VERSION "BASE;119 -- 04.07.2025 -- R3233 -- FDMgenDBC1.0"

NS_ :

BS_:

BU_: CM4

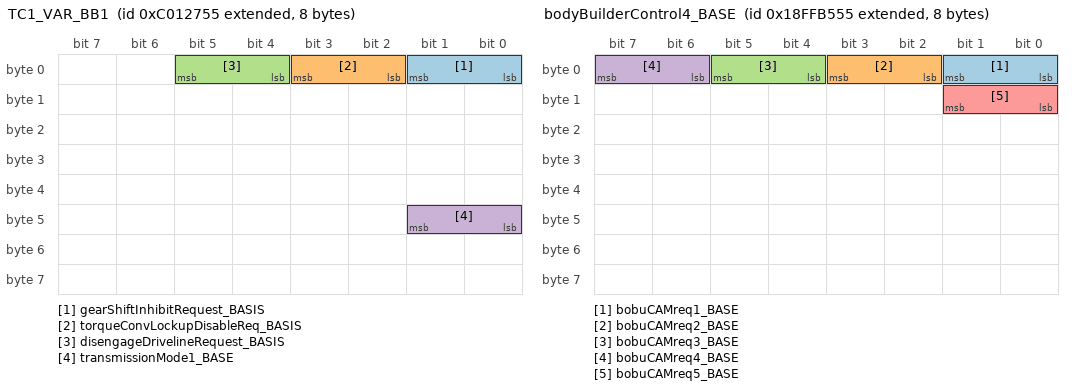
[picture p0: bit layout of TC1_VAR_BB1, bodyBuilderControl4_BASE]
BO_ 2348885845 TC1_VAR_BB1: 8 CM4
 SG_ gearShiftInhibitRequest_BASIS : 0|2@1+ (1,0) [0|0] "-" Vector__XXX
 SG_ torqueConvLockupDisableReq_BASIS : 2|2@1+ (1,0) [0|0] "-" Vector__XXX
 SG_ disengageDrivelineRequest_BASIS : 4|2@1+ (1,0) [0|0] "-" Vector__XXX
 SG_ transmissionMode1_BASE : 40|2@1+ (1,0) [0|0] "-" Vector__XXX

BO_ 2349075285 XBR_VAR7: 8 CM4
 SG_ externalAccelerationDemand_BASIS : 0|16@1+ (0.00048828125,-15.687) [-15.687|15.687] "m/s²" Vector__XXX
 SG_ XBRcontrolMode_BASIS : 20|2@1+ (1,0) [0|0] "-" Vector__XXX
 SG_ XBRmessageCounter_BASIS : 56|4@1+ (1,0) [0|15] "count" Vector__XXX
 SG_ XBRmessageChecksum_BASIS : 60|4@1+ (1,0) [0|15] "count" Vector__XXX

BO_ 2566894933 bodyBuilderControl4_BASE: 8 CM4
 SG_ bobuCAMreq1_BASE : 0|2@1+ (1,0) [0|0] "-" Vector__XXX
 SG_ bobuCAMreq2_BASE : 2|2@1+ (1,0) [0|0] "-" Vector__XXX
 SG_ bobuCAMreq3_BASE : 4|2@1+ (1,0) [0|0] "-" Vector__XXX
 SG_ bobuCAMreq4_BASE : 6|2@1+ (1,0) [0|0] "-" Vector__XXX
 SG_ bobuCAMreq5_BASE : 8|2@1+ (1,0) [0|0] "-" Vector__XXX

BO_ 2566656597 CDC1_BASE: 8 CM4
 SG_ leftFrontWindowPositionCommand_B : 16|3@1+ (1,0) [0|0] "-" Vector__XXX
 SG_ righFrontWindowPositionCommand_B : 19|3@1+ (1,0) [0|0] "-" Vector__XXX
 SG_ remoteCabDoorLockRequest_BASE : 8|3@1+ (1,0) [0|0] "-" Vector__XXX

BO_ 2564816981 cabMessage1_VAR4: 8 CM4
 SG_ DPFregenerationInhibitSw_BASE : 40|2@1+ (1,0) [0|0] "-" Vector__XXX

BO_ 2364538256 KSM1_A_VAR_BB2: 8 CM4
 SG_ requestedRoadSpeedLimit_BASIS : 32|8@1+ (1,0) [0|250] "km/h" Vector__XXX
 SG_ CCswitchStatus_KSM : 40|8@1+ (1,0) [0|0] "-" Vector__XXX
 SG_ motorStart_KSM : 48|2@1+ (1,0) [0|0] "-" Vector__XXX
 SG_ motorStop_KSM : 50|2@1+ (1,0) [0|0] "-" Vector__XXX

BO_ 2348885904 TC1_VAR_BB2: 8 CM4
 SG_ gearShiftInhibitRequest_BASIS : 0|2@1+ (1,0) [0|0] "-" Vector__XXX
 SG_ torqueConvLockupDisableReq_BASIS : 2|2@1+ (1,0) [0|0] "-" Vector__XXX
 SG_ disengageDrivelineRequest_BASIS : 4|2@1+ (1,0) [0|0] "-" Vector__XXX
 SG_ transmissionMode1_BASE : 40|2@1+ (1,0) [0|0] "-" Vector__XXX

BO_ 2349075344 XBR_VAR_BB2: 8 CM4
 SG_ externalAccelerationDemand_BASIS : 0|16@1+ (0.00048828125,-15.687) [-15.687|15.687] "m/s²" Vector__XXX
 SG_ XBRcontrolMode_BASIS : 20|2@1+ (1,0) [0|0] "-" Vector__XXX
 SG_ XBRmessageCounter_BASIS : 56|4@1+ (1,0) [0|15] "count" Vector__XXX
 SG_ XBRmessageChecksum_BASIS : 60|4@1+ (1,0) [0|15] "count" Vector__XXX

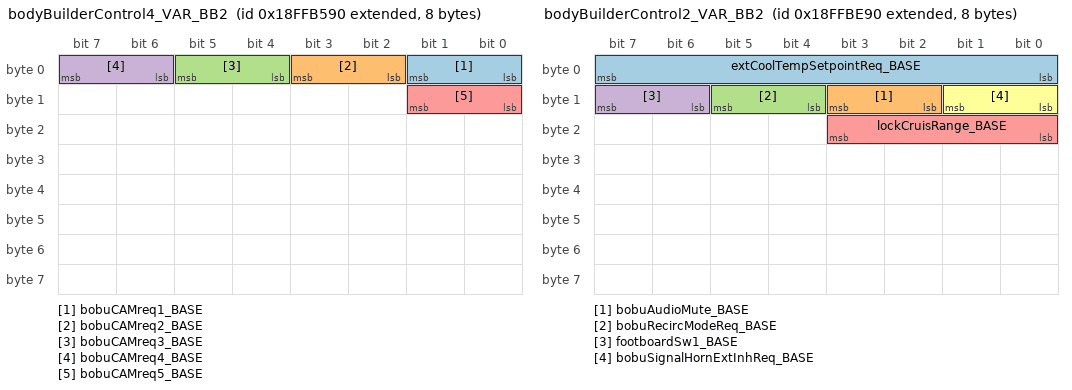
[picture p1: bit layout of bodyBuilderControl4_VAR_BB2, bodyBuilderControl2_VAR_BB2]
BO_ 2566894992 bodyBuilderControl4_VAR_BB2: 8 CM4
 SG_ bobuCAMreq1_BASE : 0|2@1+ (1,0) [0|0] "-" Vector__XXX
 SG_ bobuCAMreq2_BASE : 2|2@1+ (1,0) [0|0] "-" Vector__XXX
 SG_ bobuCAMreq3_BASE : 4|2@1+ (1,0) [0|0] "-" Vector__XXX
 SG_ bobuCAMreq4_BASE : 6|2@1+ (1,0) [0|0] "-" Vector__XXX
 SG_ bobuCAMreq5_BASE : 8|2@1+ (1,0) [0|0] "-" Vector__XXX

BO_ 2566897296 bodyBuilderControl2_VAR_BB2: 8 CM4
 SG_ extCoolTempSetpointReq_BASE : 0|8@1+ (1,-40) [-40|210] "°C" Vector__XXX
 SG_ bobuAudioMute_BASE : 10|2@1+ (1,0) [0|0] "-" Vector__XXX
 SG_ bobuRecircModeReq_BASE : 12|2@1+ (1,0) [0|0] "-" Vector__XXX
 SG_ footboardSw1_BASE : 14|2@1+ (1,0) [0|0] "-" Vector__XXX
 SG_ lockCruisRange_BASE : 16|4@1+ (1,0) [0|0] "-" Vector__XXX
 SG_ bobuSignalHornExtInhReq_BASE : 8|2@1+ (1,0) [0|0] "-" Vector__XXX

BO_ 2564817040 cabMessage1_VAR_BB2: 8 CM4
 SG_ DPFregenerationInhibitSw_BASE : 40|2@1+ (1,0) [0|0] "-" Vector__XXX

BO_ 2566656656 CDC1_VAR_BB2: 8 CM4
 SG_ leftFrontWindowPositionCommand_B : 16|3@1+ (1,0) [0|0] "-" Vector__XXX
 SG_ righFrontWindowPositionCommand_B : 19|3@1+ (1,0) [0|0] "-" Vector__XXX
 SG_ remoteCabDoorLockRequest_BASE : 8|3@1+ (1,0) [0|0] "-" Vector__XXX

BO_ 2365443216 operatorsExtLightControlsMessage: 8 CM4
 SG_ hazardLightSwitch_BASE : 40|2@1+ (1,0) [0|0] "-" Vector__XXX

BO_ 2564817041 cabMessage1_VAR_BB3: 8 CM4
 SG_ DPFregenerationInhibitSw_BASE : 40|2@1+ (1,0) [0|0] "-" Vector__XXX

BO_ 2566656657 CDC1_VAR_BB3: 8 CM4
 SG_ leftFrontWindowPositionCommand_B : 16|3@1+ (1,0) [0|0] "-" Vector__XXX
 SG_ righFrontWindowPositionCommand_B : 19|3@1+ (1,0) [0|0] "-" Vector__XXX
 SG_ remoteCabDoorLockRequest_BASE : 8|3@1+ (1,0) [0|0] "-" Vector__XXX

BO_ 2364538257 KSM1_A_VAR_BB3: 8 CM4
 SG_ requestedRoadSpeedLimit_BASIS : 32|8@1+ (1,0) [0|250] "km/h" Vector__XXX
 SG_ CCswitchStatus_KSM : 40|8@1+ (1,0) [0|0] "-" Vector__XXX
 SG_ motorStart_KSM : 48|2@1+ (1,0) [0|0] "-" Vector__XXX
 SG_ motorStop_KSM : 50|2@1+ (1,0) [0|0] "-" Vector__XXX

BO_ 2365443217 operatorsExtLightControlsMessage: 8 CM4
 SG_ hazardLightSwitch_BASE : 12|2@1+ (1,0) [0|0] "-" Vector__XXX

BO_ 2348885905 TC1_VAR_BB3: 8 CM4
 SG_ gearShiftInhibitRequest_BASIS : 0|2@1+ (1,0) [0|0] "-" Vector__XXX
 SG_ torqueConvLockupDisableReq_BASIS : 2|2@1+ (1,0) [0|0] "-" Vector__XXX
 SG_ disengageDrivelineRequest_BASIS : 4|2@1+ (1,0) [0|0] "-" Vector__XXX
 SG_ transmissionMode1_BASE : 40|2@1+ (1,0) [0|0] "-" Vector__XXX

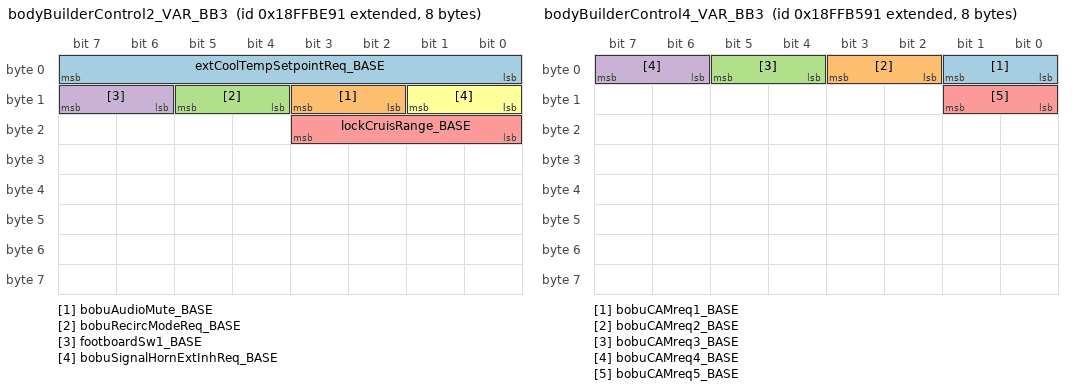
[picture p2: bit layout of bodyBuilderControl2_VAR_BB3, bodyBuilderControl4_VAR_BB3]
BO_ 2566897297 bodyBuilderControl2_VAR_BB3: 8 CM4
 SG_ extCoolTempSetpointReq_BASE : 0|8@1+ (1,-40) [-40|210] "°C" Vector__XXX
 SG_ bobuAudioMute_BASE : 10|2@1+ (1,0) [0|0] "-" Vector__XXX
 SG_ bobuRecircModeReq_BASE : 12|2@1+ (1,0) [0|0] "-" Vector__XXX
 SG_ footboardSw1_BASE : 14|2@1+ (1,0) [0|0] "-" Vector__XXX
 SG_ lockCruisRange_BASE : 16|4@1+ (1,0) [0|0] "-" Vector__XXX
 SG_ bobuSignalHornExtInhReq_BASE : 8|2@1+ (1,0) [0|0] "-" Vector__XXX

BO_ 2566894993 bodyBuilderControl4_VAR_BB3: 8 CM4
 SG_ bobuCAMreq1_BASE : 0|2@1+ (1,0) [0|0] "-" Vector__XXX
 SG_ bobuCAMreq2_BASE : 2|2@1+ (1,0) [0|0] "-" Vector__XXX
 SG_ bobuCAMreq3_BASE : 4|2@1+ (1,0) [0|0] "-" Vector__XXX
 SG_ bobuCAMreq4_BASE : 6|2@1+ (1,0) [0|0] "-" Vector__XXX
 SG_ bobuCAMreq5_BASE : 8|2@1+ (1,0) [0|0] "-" Vector__XXX

BO_ 2349075345 XBR_VAR_BB3: 8 CM4
 SG_ externalAccelerationDemand_BASIS : 0|16@1+ (0.00048828125,-15.687) [-15.687|15.687] "m/s²" Vector__XXX
 SG_ XBRcontrolMode_BASIS : 20|2@1+ (1,0) [0|0] "-" Vector__XXX
 SG_ XBRmessageCounter_BASIS : 56|4@1+ (1,0) [0|15] "count" Vector__XXX
 SG_ XBRmessageChecksum_BASIS : 60|4@1+ (1,0) [0|15] "count" Vector__XXX

BO_ 2565865813 EBC1_VAR3: 8 CM4
 SG_ haltBrakeSwitch_BASIS : 58|2@1+ (1,0) [0|0] "-" Vector__XXX

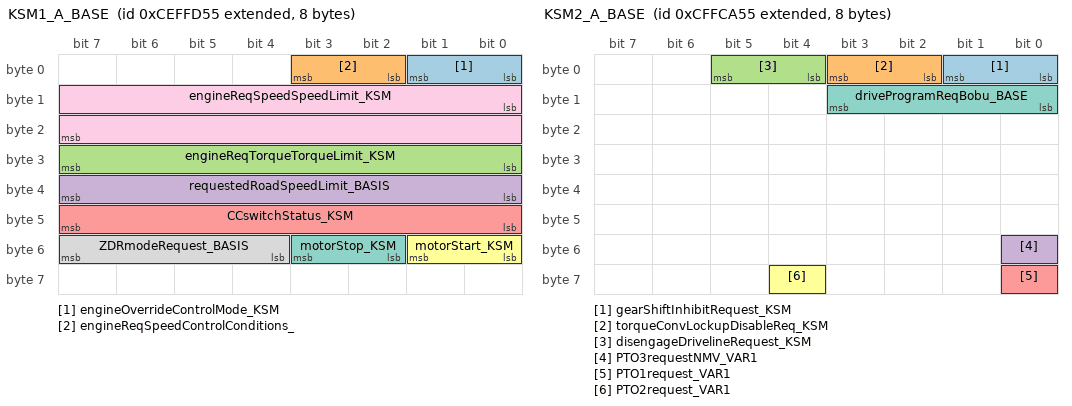
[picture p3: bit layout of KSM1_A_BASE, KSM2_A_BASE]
BO_ 2364538197 KSM1_A_BASE: 8 CM4
 SG_ engineOverrideControlMode_KSM : 0|2@1+ (1,0) [0|0] "-" Vector__XXX
 SG_ engineReqSpeedControlConditions_ : 2|2@1+ (1,0) [0|0] "-" Vector__XXX
 SG_ engineReqTorqueTorqueLimit_KSM : 24|8@1+ (1,-125) [-125|125] "%" Vector__XXX
 SG_ requestedRoadSpeedLimit_BASIS : 32|8@1+ (1,0) [0|250] "km/h" Vector__XXX
 SG_ CCswitchStatus_KSM : 40|8@1+ (1,0) [0|0] "-" Vector__XXX
 SG_ motorStart_KSM : 48|2@1+ (1,0) [0|0] "-" Vector__XXX
 SG_ motorStop_KSM : 50|2@1+ (1,0) [0|0] "-" Vector__XXX
 SG_ ZDRmodeRequest_BASIS : 52|4@1+ (1,0) [0|0] "-" Vector__XXX
 SG_ engineReqSpeedSpeedLimit_KSM : 8|16@1+ (0.125,0) [0|8031.875] "rpm" Vector__XXX

BO_ 2365573717 KSM2_A_BASE: 8 CM4
 SG_ gearShiftInhibitRequest_KSM : 0|2@1+ (1,0) [0|0] "-" Vector__XXX
 SG_ torqueConvLockupDisableReq_KSM : 2|2@1+ (1,0) [0|0] "-" Vector__XXX
 SG_ disengageDrivelineRequest_KSM : 4|2@1+ (1,0) [0|0] "-" Vector__XXX
 SG_ PTO3requestNMV_VAR1 : 48|1@1+ (1,0) [0|0] "-" Vector__XXX
 SG_ PTO1request_VAR1 : 56|1@1+ (1,0) [0|0] "-" Vector__XXX
 SG_ PTO2request_VAR1 : 60|1@1+ (1,0) [0|0] "-" Vector__XXX
 SG_ driveProgramReqBobu_BASE : 8|4@1+ (1,0) [0|0] "-" Vector__XXX

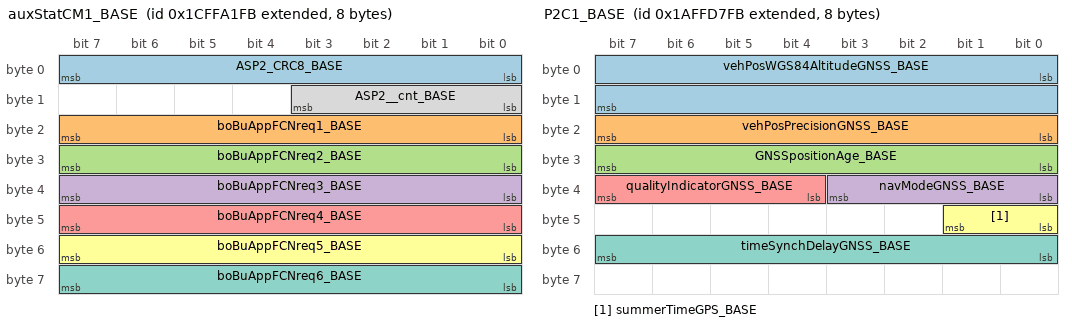
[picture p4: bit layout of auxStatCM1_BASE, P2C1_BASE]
BO_ 2633998843 auxStatCM1_BASE: 8 CM4
 SG_ ASP2_CRC8_BASE : 0|8@1+ (1,0) [0|255] "-" Vector__XXX
 SG_ boBuAppFCNreq1_BASE : 16|8@1+ (1,0) [0|250] "-" Vector__XXX
 SG_ boBuAppFCNreq2_BASE : 24|8@1+ (1,0) [0|250] "-" Vector__XXX
 SG_ boBuAppFCNreq3_BASE : 32|8@1+ (1,0) [0|250] "-" Vector__XXX
 SG_ boBuAppFCNreq4_BASE : 40|8@1+ (1,0) [0|250] "-" Vector__XXX
 SG_ boBuAppFCNreq5_BASE : 48|8@1+ (1,0) [0|250] "-" Vector__XXX
 SG_ boBuAppFCNreq6_BASE : 56|8@1+ (1,0) [0|250] "-" Vector__XXX
 SG_ ASP2__cnt_BASE : 8|4@1+ (1,0) [0|15] "-" Vector__XXX

BO_ 2600458491 P2C2_BASE: 8 CM4
 SG_ vehPosCWGS84LatitudeGNSS_BASE : 0|32@1+ (0.0000001,-210) [-210|210] "°" Vector__XXX
 SG_ vehPosCWGS84LongitudeGNSS_BASE : 32|32@1+ (0.0000001,-210) [-210|210] "°" Vector__XXX

BO_ 2600458235 P2C1_BASE: 8 CM4
 SG_ vehPosWGS84AltitudeGNSS_BASE : 0|16@1+ (1,-1000) [-1000|10000] "m" Vector__XXX
 SG_ vehPosPrecisionGNSS_BASE : 16|8@1+ (0.5,0) [0|120] "m" Vector__XXX
 SG_ GNSSpositionAge_BASE : 24|8@1+ (5,0) [0|1250] "ms" Vector__XXX
 SG_ navModeGNSS_BASE : 32|4@1+ (1,0) [0|0] "-" Vector__XXX
 SG_ qualityIndicatorGNSS_BASE : 36|4@1+ (1,0) [0|0] "-" Vector__XXX
 SG_ summerTimeGPS_BASE : 40|2@1+ (1,0) [0|0] "-" Vector__XXX
 SG_ timeSynchDelayGNSS_BASE : 48|8@1+ (5,0) [0|1250] "ms" Vector__XXX

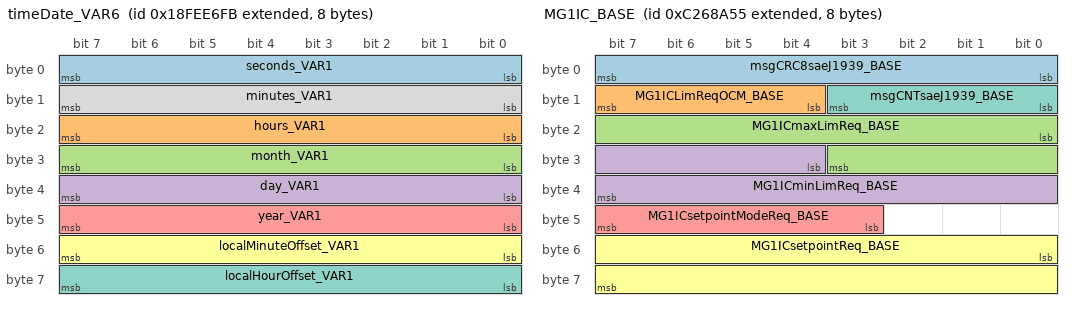
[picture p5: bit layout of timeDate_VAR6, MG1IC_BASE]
BO_ 2566842107 timeDate_VAR6: 8 CM4
 SG_ seconds_VAR1 : 0|8@1+ (0.25,0) [0|62.5] "s" Vector__XXX
 SG_ hours_VAR1 : 16|8@1+ (1,0) [0|250] "h" Vector__XXX
 SG_ month_VAR1 : 24|8@1+ (1,0) [0|250] "month" Vector__XXX
 SG_ day_VAR1 : 32|8@1+ (0.25,0) [0|62.5] "day" Vector__XXX
 SG_ year_VAR1 : 40|8@1+ (1,1985) [1985|2235] "year" Vector__XXX
 SG_ localMinuteOffset_VAR1 : 48|8@1+ (1,-125) [-125|125] "min" Vector__XXX
 SG_ localHourOffset_VAR1 : 56|8@1+ (1,-125) [-125|125] "h" Vector__XXX
 SG_ minutes_VAR1 : 8|8@1+ (1,0) [0|250] "min" Vector__XXX

BO_ 2566649595 VP2_BASE: 8 CM4
 SG_ numberSatellitesGNSS_BASE : 0|8@1+ (1,0) [0|250] "-" Vector__XXX
 SG_ vdopGNSS_BASE : 16|8@1+ (0.1,0) [0|25] "-" Vector__XXX
 SG_ pdopGNSS_BASE : 24|8@1+ (0.1,0) [0|25] "-" Vector__XXX
 SG_ tdopGNSS_BASE : 32|8@1+ (0.1,0) [0|25] "-" Vector__XXX
 SG_ hdopGNSS_BASE : 8|8@1+ (0.1,0) [0|25] "-" Vector__XXX

BO_ 2566842619 VDS_BASE: 8 CM4
 SG_ compBearingGNSS_BASE : 0|16@1+ (0.0078125,0) [0|501.99] "°" Vector__XXX
 SG_ vehSpdGNSS_BASE : 16|16@1+ (0.00390625,0) [0|250.996] "km/h" Vector__XXX
 SG_ pitchGNSS_BASE : 32|16@1+ (0.0078125,-200) [-200|301.99] "°" Vector__XXX
 SG_ altitudeGNSS_BASE : 48|16@1+ (0.125,-2500) [-2500|5531.875] "m" Vector__XXX

BO_ 2566845435 VP1_BASE: 8 CM4
 SG_ vehPosWGS84LatitudeGNSS_BASE : 0|32@1+ (0.0000001,-210) [-210|210] "°" Vector__XXX
 SG_ vehPosWGS84LongitudeGNSS_BASE : 32|32@1+ (0.0000001,-210) [-210|210] "°" Vector__XXX

BO_ 2583638267 appControlInterface_VAR2: 8 CM4
 SG_ appFrameworkCtrlAppID_BASE : 24|16@1+ (1,0) [0|64255] "-" Vector__XXX
 SG_ appFrameworkAppCommand_BASE : 40|16@1+ (1,0) [0|0] "-" Vector__XXX

BO_ 2564484859 UDSreq_TBM2DTCO: 8 CM4
 SG_ UDSreq_TBM2DTCO : 0|8@1+ (1,0) [0|255] "-" Vector__XXX

BO_ 2564554736 UDSreqFCN_F0_TO_ALL: 8 CM4
 SG_ UDS_FCNF0_TO_ALL : 0|8@1+ (1,0) [0|255] "-" Vector__XXX

BO_ 2564484632 UDSreq_CM42DTCO: 8 CM4
 SG_ UDSreq_CM42DTCO : 0|8@1+ (1,0) [0|255] "-" Vector__XXX

BO_ 2600460056 RTprop1_BASE: 100 CM4
 SG_ rmtTstrInstallMsgHeaderRsp_BASE : 0|16@1+ (1,0) [0|0] "-" Vector__XXX
 SG_ rmtTstrInstallPduSize_BASE : 16|8@1+ (1,0) [0|127] "-" Vector__XXX
 SG_ rmtTstrInstallJobIdResp_BASE : 24|8@1+ (1,0) [0|250] "-" Vector__XXX
 SG_ rmtTstrInstallListIdxResp_BASE : 32|8@1+ (1,0) [0|250] "-" Vector__XXX
 SG_ rmtTstrInstallRespCode_BASE : 40|8@1+ (1,0) [0|0] "-" Vector__XXX
 SG_ rmtTstrInstallRespIdx_BASE : 48|8@1+ (1,0) [0|250] "-" Vector__XXX
 SG_ rmtTstrInstallTotNumOfResp_BASE : 56|8@1+ (1,0) [0|250] "-" Vector__XXX
 SG_ rmtTstrInstallContentSize_BASE : 64|8@1+ (1,0) [0|127] "-" Vector__XXX
 SG_ rmtTstrInstallContent_BASE : 72|728@1+ (1,0) [0|0] "-" Vector__XXX

BO_ 2600403195 NM_CM4: 8 CM4
 SG_ HB_Wakeup_BASE : 0|8@1+ (1,0) [0|0] "-" Vector__XXX
 SG_ NM_CBV_Res2_BASE : 10|1@1+ (1,0) [0|1] "-" Vector__XXX
 SG_ NM_CBV_Res3_BASE : 11|1@1+ (1,0) [0|1] "-" Vector__XXX
 SG_ NM_ActiveWakeupBit_BASE : 12|1@1+ (1,0) [0|0] "-" Vector__XXX
 SG_ NM_CBV_Res5_BASE : 13|1@1+ (1,0) [0|1] "-" Vector__XXX
 SG_ NM_CRI_BASE : 14|1@1+ (1,0) [0|0] "-" Vector__XXX
 SG_ NM_CBV_Res7_BASE : 15|1@1+ (1,0) [0|1] "-" Vector__XXX
 SG_ NM_State_BASE : 16|6@1+ (1,0) [0|0] "-" Vector__XXX
 SG_ NM_CarWakeup_BASE : 22|1@1+ (1,0) [0|0] "-" Vector__XXX
 SG_ NM_CC_BASE : 23|1@1+ (1,0) [0|0] "-" Vector__XXX
 SG_ NM_activeClamp15_BASE : 24|1@1+ (1,0) [0|0] "-" Vector__XXX
 SG_ NM_activeDiag_BASE : 25|1@1+ (1,0) [0|0] "-" Vector__XXX
 SG_ NM_activeTmin_BASE : 26|1@1+ (1,0) [0|0] "-" Vector__XXX
 SG_ NM_activeCWU_BASE : 27|1@1+ (1,0) [0|0] "-" Vector__XXX
 SG_ NM_activeFC_BASE : 28|1@1+ (1,0) [0|0] "-" Vector__XXX
 SG_ NM_Res29_BASE : 29|7@1+ (1,0) [0|127] "-" Vector__XXX
 SG_ NM_Res36_BASE : 36|4@1+ (1,0) [0|15] "-" Vector__XXX
 SG_ nmClusterActive00_BASE : 40|1@1+ (1,0) [0|0] "-" Vector__XXX
 SG_ nmClusterActive01_BASE : 41|1@1+ (1,0) [0|0] "-" Vector__XXX
 SG_ nmClusterActive02_BASE : 42|1@1+ (1,0) [0|0] "-" Vector__XXX
 SG_ nmClusterActive03_BASE : 43|1@1+ (1,0) [0|0] "-" Vector__XXX
 SG_ nmClusterActive04_BASE : 44|1@1+ (1,0) [0|0] "-" Vector__XXX
 SG_ nmClusterActive05_BASE : 45|1@1+ (1,0) [0|0] "-" Vector__XXX
 SG_ nmClusterActive06_BASE : 46|1@1+ (1,0) [0|0] "-" Vector__XXX
 SG_ nmClusterActive07_BASE : 47|1@1+ (1,0) [0|0] "-" Vector__XXX
 SG_ nmClusterActive08_BASE : 48|1@1+ (1,0) [0|0] "-" Vector__XXX
 SG_ nmClusterActive09_BASE : 49|1@1+ (1,0) [0|0] "-" Vector__XXX
 SG_ nmClusterActive10_BASE : 50|1@1+ (1,0) [0|0] "-" Vector__XXX
 SG_ nmClusterActive11_BASE : 51|1@1+ (1,0) [0|0] "-" Vector__XXX
 SG_ nmClusterActive12_BASE : 52|1@1+ (1,0) [0|0] "-" Vector__XXX
 SG_ nmClusterActive13_BASE : 53|1@1+ (1,0) [0|0] "-" Vector__XXX
 SG_ nmClusterActive14_BASE : 54|1@1+ (1,0) [0|0] "-" Vector__XXX
 SG_ nmClusterActive15_BASE : 55|1@1+ (1,0) [0|0] "-" Vector__XXX
 SG_ nmClusterActive16_BASE : 56|1@1+ (1,0) [0|0] "-" Vector__XXX
 SG_ nmClusterActive17_BASE : 57|1@1+ (1,0) [0|0] "-" Vector__XXX
 SG_ nmClusterActive18_BASE : 58|1@1+ (1,0) [0|0] "-" Vector__XXX
 SG_ nmClusterActive19_BASE : 59|1@1+ (1,0) [0|0] "-" Vector__XXX
 SG_ nmClusterActive20_BASE : 60|1@1+ (1,0) [0|0] "-" Vector__XXX
 SG_ nmClusterActive21_BASE : 61|1@1+ (1,0) [0|0] "-" Vector__XXX
 SG_ nmClusterActive22_BASE : 62|1@1+ (1,0) [0|0] "-" Vector__XXX
 SG_ nmClusterActive23_BASE : 63|1@1+ (1,0) [0|0] "-" Vector__XXX
 SG_ NM_CBV_Res0_BASE : 8|1@1+ (1,0) [0|1] "-" Vector__XXX
 SG_ NM_CBV_Res1_BASE : 9|1@1+ (1,0) [0|1] "-" Vector__XXX

BO_ 2566893819 FWS_TBM2MC_BASIS: 8 CM4
 SG_ reihenfolge_TBM2MC : 16|6@1+ (1,0) [0|0] "-" Vector__XXX
 SG_ abfrageZWS_FWS_TBM2MC : 3|1@1+ (1,0) [0|0] "-" Vector__XXX
 SG_ typMeldung_TBM2MC : 4|1@1+ (1,0) [0|0] "-" Vector__XXX
 SG_ abfragetyp_TBM2MC : 7|1@1+ (1,0) [0|0] "-" Vector__XXX

BO_ 2365443157 operatorsExtLightControlsMessage: 8 CM4
 SG_ hazardLightSwitch_BASE : 12|2@1+ (1,0) [0|0] "-" Vector__XXX

BO_ 2566895189 bodyBuilderControl5_BASE: 8 CM4
 SG_ ASP2_CRC8_BASE : 0|8@1+ (1,0) [0|255] "-" Vector__XXX
 SG_ statusBodyEPTO_BASE : 12|2@1+ (1,0) [0|0] "-" Vector__XXX
 SG_ ePTOreqBodyBuilder_BASE : 14|2@1+ (1,0) [0|0] "-" Vector__XXX
 SG_ ASP2__cnt_BASE : 8|4@1+ (1,0) [0|15] "-" Vector__XXX

BO_ 2566679953 AWR_VAR_BB3: 8 CM4
 SG_ vehicleHorn_BASE : 2|2@1+ (1,0) [0|0] "-" Vector__XXX
 SG_ reverseDrivingAlarm_BASE : 4|2@1+ (1,0) [0|0] "-" Vector__XXX

BO_ 2566679952 AWR_VAR_BB2: 8 CM4
 SG_ vehicleHorn_BASE : 2|2@1+ (1,0) [0|0] "-" Vector__XXX
 SG_ reverseDrivingAlarm_BASE : 4|2@1+ (1,0) [0|0] "-" Vector__XXX

BO_ 2566679893 AWR_BASE: 8 CM4
 SG_ vehicleHorn_BASE : 2|2@1+ (1,0) [0|0] "-" Vector__XXX
 SG_ reverseDrivingAlarm_BASE : 4|2@1+ (1,0) [0|0] "-" Vector__XXX

BO_ 2566895445 bodyBuilderControl6_BASE: 8 CM4
 SG_ BB_PlaceHolder_BASE : 0|8@1+ (1,0) [0|255] "-" Vector__XXX

BO_ 2600454915 auxStatCM2_BASE: 8 CM4
 SG_ conMapSpdLimDC_BASE : 0|8@1+ (1,0) [0|250] "km/h" Vector__XXX
 SG_ conMapSpdLimPlayStreet_BASE : 16|8@1+ (1,0) [0|250] "km/h" Vector__XXX
 SG_ conMapSpdLimRural_BASE : 24|8@1+ (1,0) [0|250] "km/h" Vector__XXX
 SG_ conMapSpdLimMotorway_BASE : 32|8@1+ (1,0) [0|250] "km/h" Vector__XXX
 SG_ conMapSpdLimUrban_BASE : 40|8@1+ (1,0) [0|250] "km/h" Vector__XXX
 SG_ conMapSpdLimSC_BASE : 8|8@1+ (1,0) [0|250] "km/h" Vector__XXX

BO_ 2583669489 ODSC_HB_BASE: 8 CM4
 SG_ ODSC_errorState_BASE : 0|16@1+ (1,0) [0|64255] "-" Vector__XXX

BO_ 2600454923 auxStatCM14_BASE: 8 CM4
 SG_ auxStatCM14placeholder_BASE : 0|8@1+ (1,0) [0|255] "-" Vector__XXX

BO_ 2600454916 auxStatCM7_BASE: 8 CM4
 SG_ updtMstrUpdateStatus_BASE : 0|4@1+ (1,0) [0|0] "-" Vector__XXX
 SG_ updtMstrDispSupCheckbox_BASE : 10|2@1+ (1,0) [0|0] "-" Vector__XXX
 SG_ updtMstrUpdateTypeInfo_BASE : 4|4@1+ (1,0) [0|0] "-" Vector__XXX
 SG_ updtMstrDrvrNotifStatus_BASE : 8|2@1+ (1,0) [0|0] "-" Vector__XXX

BO_ 2351336021 MG1IC_BASE: 8 CM4
 SG_ msgCRC8saeJ1939_BASE : 0|8@1+ (1,0) [0|255] "-" Vector__XXX
 SG_ MG1ICLimReqOCM_BASE : 12|4@1+ (1,0) [0|0] "-" Vector__XXX
 SG_ MG1ICmaxLimReq_BASE : 16|12@1+ (0.0625,-125) [-125|125.9375] "%" Vector__XXX
 SG_ MG1ICminLimReq_BASE : 28|12@1+ (0.0625,-125) [-125|125.9375] "%" Vector__XXX
 SG_ MG1ICsetpointModeReq_BASE : 43|5@1+ (1,0) [0|0] "-" Vector__XXX
 SG_ MG1ICsetpointReq_BASE : 48|16@1+ (0.00390625,-125) [-125|125.99609375] "%" Vector__XXX
 SG_ msgCNTsaeJ1939_BASE : 8|4@1+ (1,0) [0|15] "-" Vector__XXX

BO_ 2364638805 MG2IMF1_BASE: 8 CM4
 SG_ msgCRC8saeJ1939_BASE : 0|8@1+ (1,0) [0|255] "-" Vector__XXX
 SG_ MG2IMF1setpointMode_BASE : 16|5@1+ (1,0) [0|0] "-" Vector__XXX
 SG_ msgCNTsaeJ1939_BASE : 8|4@1+ (1,0) [0|15] "-" Vector__XXX

BO_ 2365287765 MG2IS1_BASE: 8 CM4
 SG_ msgCRC8saeJ1939_BASE : 0|8@1+ (1,0) [0|255] "-" Vector__XXX
 SG_ actMotorTrqPrcnt_BASE : 12|12@1+ (0.0625,-125) [-125|125.9375] "%" Vector__XXX
 SG_ actMotorSpeedPrcnt_BASE : 24|16@1+ (0.00390625,-125) [-125|125.99609375] "%" Vector__XXX
 SG_ msgCNTsaeJ1939_BASE : 8|4@1+ (1,0) [0|15] "-" Vector__XXX

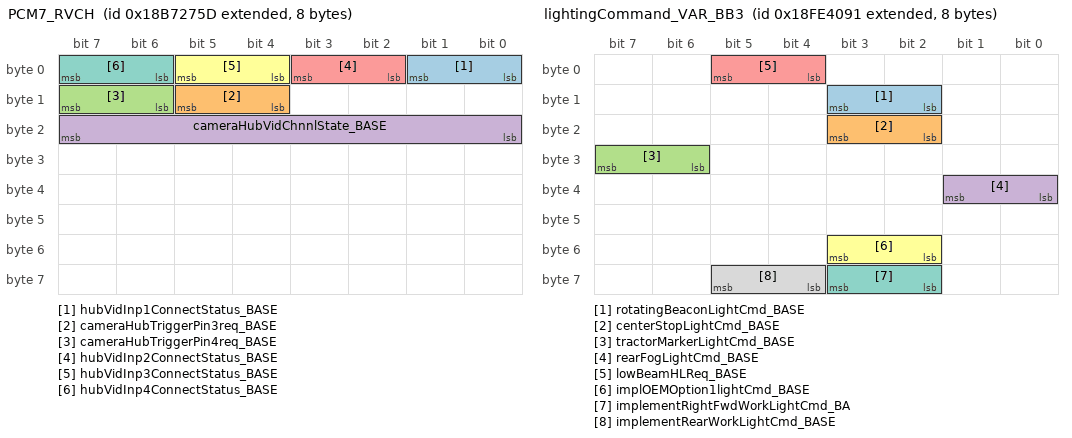
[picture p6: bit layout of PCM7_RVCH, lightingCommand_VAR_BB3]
BO_ 2562139997 PCM7_RVCH: 8 CM4
 SG_ hubVidInp1ConnectStatus_BASE : 0|2@1+ (1,0) [0|0] "-" Vector__XXX
 SG_ cameraHubTriggerPin3req_BASE : 12|2@1+ (1,0) [0|0] "-" Vector__XXX
 SG_ cameraHubTriggerPin4req_BASE : 14|2@1+ (1,0) [0|0] "-" Vector__XXX
 SG_ cameraHubVidChnnlState_BASE : 16|8@1+ (1,0) [0|0] "-" Vector__XXX
 SG_ hubVidInp2ConnectStatus_BASE : 2|2@1+ (1,0) [0|0] "-" Vector__XXX
 SG_ hubVidInp3ConnectStatus_BASE : 4|2@1+ (1,0) [0|0] "-" Vector__XXX
 SG_ hubVidInp4ConnectStatus_BASE : 6|2@1+ (1,0) [0|0] "-" Vector__XXX

BO_ 2566799505 lightingCommand_VAR_BB3: 8 CM4
 SG_ rotatingBeaconLightCmd_BASE : 10|2@1+ (1,0) [0|0] "-" Vector__XXX
 SG_ centerStopLightCmd_BASE : 18|2@1+ (1,0) [0|0] "-" Vector__XXX
 SG_ tractorMarkerLightCmd_BASE : 30|2@1+ (1,0) [0|0] "-" Vector__XXX
 SG_ rearFogLightCmd_BASE : 32|2@1+ (1,0) [0|0] "-" Vector__XXX
 SG_ lowBeamHLReq_BASE : 4|2@1+ (1,0) [0|0] "-" Vector__XXX
 SG_ implOEMOption1lightCmd_BASE : 50|2@1+ (1,0) [0|0] "-" Vector__XXX
 SG_ implementRightFwdWorkLightCmd_BA : 58|2@1+ (1,0) [0|0] "-" Vector__XXX
 SG_ implementRearWorkLightCmd_BASE : 60|2@1+ (1,0) [0|0] "-" Vector__XXX

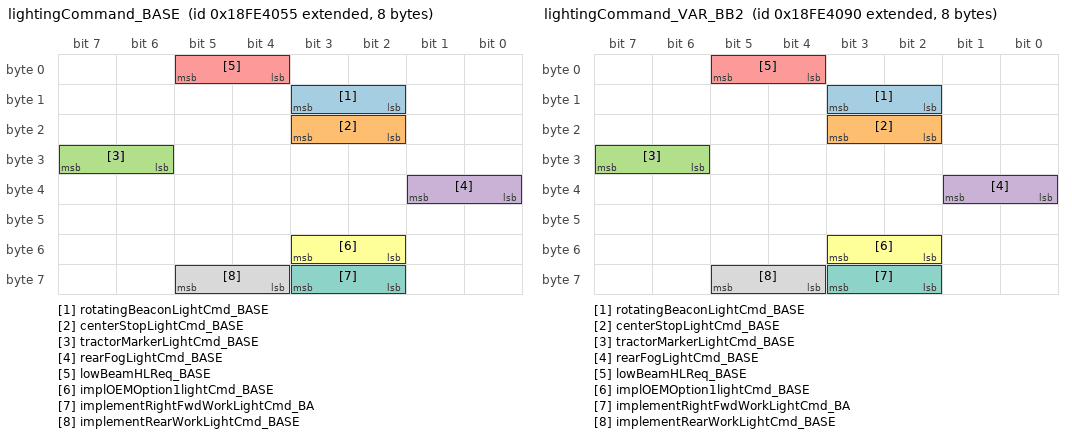
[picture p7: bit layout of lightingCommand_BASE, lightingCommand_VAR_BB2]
BO_ 2566799445 lightingCommand_BASE: 8 CM4
 SG_ rotatingBeaconLightCmd_BASE : 10|2@1+ (1,0) [0|0] "-" Vector__XXX
 SG_ centerStopLightCmd_BASE : 18|2@1+ (1,0) [0|0] "-" Vector__XXX
 SG_ tractorMarkerLightCmd_BASE : 30|2@1+ (1,0) [0|0] "-" Vector__XXX
 SG_ rearFogLightCmd_BASE : 32|2@1+ (1,0) [0|0] "-" Vector__XXX
 SG_ lowBeamHLReq_BASE : 4|2@1+ (1,0) [0|0] "-" Vector__XXX
 SG_ implOEMOption1lightCmd_BASE : 50|2@1+ (1,0) [0|0] "-" Vector__XXX
 SG_ implementRightFwdWorkLightCmd_BA : 58|2@1+ (1,0) [0|0] "-" Vector__XXX
 SG_ implementRearWorkLightCmd_BASE : 60|2@1+ (1,0) [0|0] "-" Vector__XXX

BO_ 2566799504 lightingCommand_VAR_BB2: 8 CM4
 SG_ rotatingBeaconLightCmd_BASE : 10|2@1+ (1,0) [0|0] "-" Vector__XXX
 SG_ centerStopLightCmd_BASE : 18|2@1+ (1,0) [0|0] "-" Vector__XXX
 SG_ tractorMarkerLightCmd_BASE : 30|2@1+ (1,0) [0|0] "-" Vector__XXX
 SG_ rearFogLightCmd_BASE : 32|2@1+ (1,0) [0|0] "-" Vector__XXX
 SG_ lowBeamHLReq_BASE : 4|2@1+ (1,0) [0|0] "-" Vector__XXX
 SG_ implOEMOption1lightCmd_BASE : 50|2@1+ (1,0) [0|0] "-" Vector__XXX
 SG_ implementRightFwdWorkLightCmd_BA : 58|2@1+ (1,0) [0|0] "-" Vector__XXX
 SG_ implementRearWorkLightCmd_BASE : 60|2@1+ (1,0) [0|0] "-" Vector__XXX

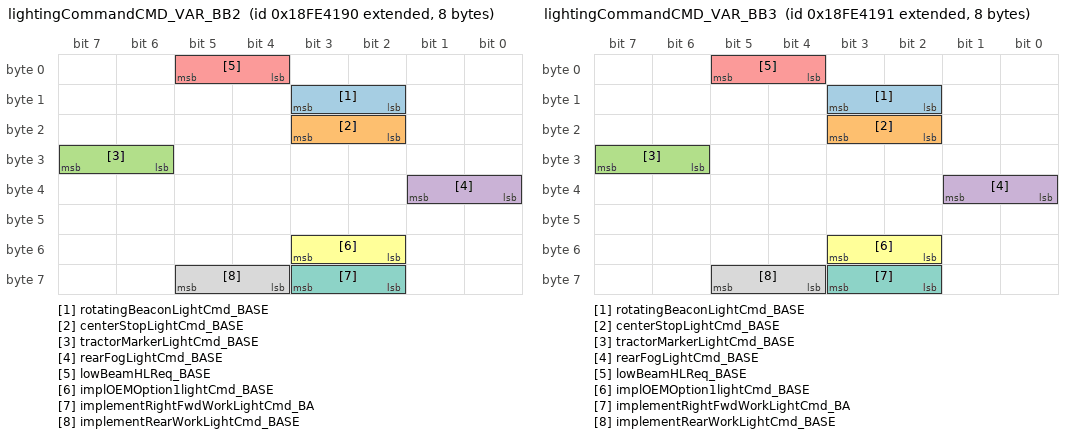
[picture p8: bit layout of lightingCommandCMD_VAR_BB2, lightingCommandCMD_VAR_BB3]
BO_ 2566799760 lightingCommandCMD_VAR_BB2: 8 CM4
 SG_ rotatingBeaconLightCmd_BASE : 10|2@1+ (1,0) [0|0] "-" Vector__XXX
 SG_ centerStopLightCmd_BASE : 18|2@1+ (1,0) [0|0] "-" Vector__XXX
 SG_ tractorMarkerLightCmd_BASE : 30|2@1+ (1,0) [0|0] "-" Vector__XXX
 SG_ rearFogLightCmd_BASE : 32|2@1+ (1,0) [0|0] "-" Vector__XXX
 SG_ lowBeamHLReq_BASE : 4|2@1+ (1,0) [0|0] "-" Vector__XXX
 SG_ implOEMOption1lightCmd_BASE : 50|2@1+ (1,0) [0|0] "-" Vector__XXX
 SG_ implementRightFwdWorkLightCmd_BA : 58|2@1+ (1,0) [0|0] "-" Vector__XXX
 SG_ implementRearWorkLightCmd_BASE : 60|2@1+ (1,0) [0|0] "-" Vector__XXX

BO_ 2566799761 lightingCommandCMD_VAR_BB3: 8 CM4
 SG_ rotatingBeaconLightCmd_BASE : 10|2@1+ (1,0) [0|0] "-" Vector__XXX
 SG_ centerStopLightCmd_BASE : 18|2@1+ (1,0) [0|0] "-" Vector__XXX
 SG_ tractorMarkerLightCmd_BASE : 30|2@1+ (1,0) [0|0] "-" Vector__XXX
 SG_ rearFogLightCmd_BASE : 32|2@1+ (1,0) [0|0] "-" Vector__XXX
 SG_ lowBeamHLReq_BASE : 4|2@1+ (1,0) [0|0] "-" Vector__XXX
 SG_ implOEMOption1lightCmd_BASE : 50|2@1+ (1,0) [0|0] "-" Vector__XXX
 SG_ implementRightFwdWorkLightCmd_BA : 58|2@1+ (1,0) [0|0] "-" Vector__XXX
 SG_ implementRearWorkLightCmd_BASE : 60|2@1+ (1,0) [0|0] "-" Vector__XXX

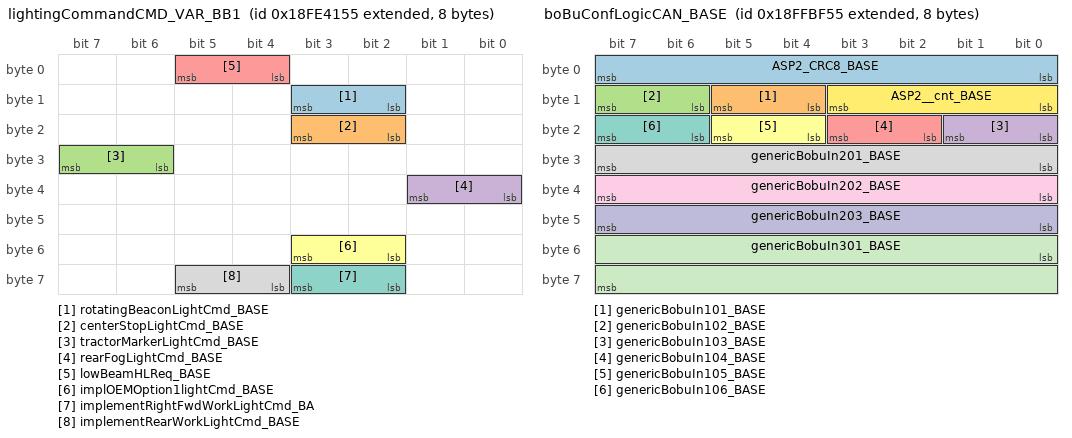
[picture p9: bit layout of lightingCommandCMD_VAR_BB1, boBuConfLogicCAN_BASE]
BO_ 2566799701 lightingCommandCMD_VAR_BB1: 8 CM4
 SG_ rotatingBeaconLightCmd_BASE : 10|2@1+ (1,0) [0|0] "-" Vector__XXX
 SG_ centerStopLightCmd_BASE : 18|2@1+ (1,0) [0|0] "-" Vector__XXX
 SG_ tractorMarkerLightCmd_BASE : 30|2@1+ (1,0) [0|0] "-" Vector__XXX
 SG_ rearFogLightCmd_BASE : 32|2@1+ (1,0) [0|0] "-" Vector__XXX
 SG_ lowBeamHLReq_BASE : 4|2@1+ (1,0) [0|0] "-" Vector__XXX
 SG_ implOEMOption1lightCmd_BASE : 50|2@1+ (1,0) [0|0] "-" Vector__XXX
 SG_ implementRightFwdWorkLightCmd_BA : 58|2@1+ (1,0) [0|0] "-" Vector__XXX
 SG_ implementRearWorkLightCmd_BASE : 60|2@1+ (1,0) [0|0] "-" Vector__XXX

BO_ 2566897493 boBuConfLogicCAN_BASE: 8 CM4
 SG_ ASP2_CRC8_BASE : 0|8@1+ (1,0) [0|255] "-" Vector__XXX
 SG_ genericBobuIn101_BASE : 12|2@1+ (1,0) [0|0] "-" Vector__XXX
 SG_ genericBobuIn102_BASE : 14|2@1+ (1,0) [0|0] "-" Vector__XXX
 SG_ genericBobuIn103_BASE : 16|2@1+ (1,0) [0|0] "-" Vector__XXX
 SG_ genericBobuIn104_BASE : 18|2@1+ (1,0) [0|0] "-" Vector__XXX
 SG_ genericBobuIn105_BASE : 20|2@1+ (1,0) [0|0] "-" Vector__XXX
 SG_ genericBobuIn106_BASE : 22|2@1+ (1,0) [0|0] "-" Vector__XXX
 SG_ genericBobuIn201_BASE : 24|8@1+ (1,0) [0|250] "-" Vector__XXX
 SG_ genericBobuIn202_BASE : 32|8@1+ (1,0) [0|250] "-" Vector__XXX
 SG_ genericBobuIn203_BASE : 40|8@1+ (1,0) [0|250] "-" Vector__XXX
 SG_ genericBobuIn301_BASE : 48|16@1+ (1,0) [0|64255] "-" Vector__XXX
 SG_ ASP2__cnt_BASE : 8|4@1+ (1,0) [0|15] "-" Vector__XXX

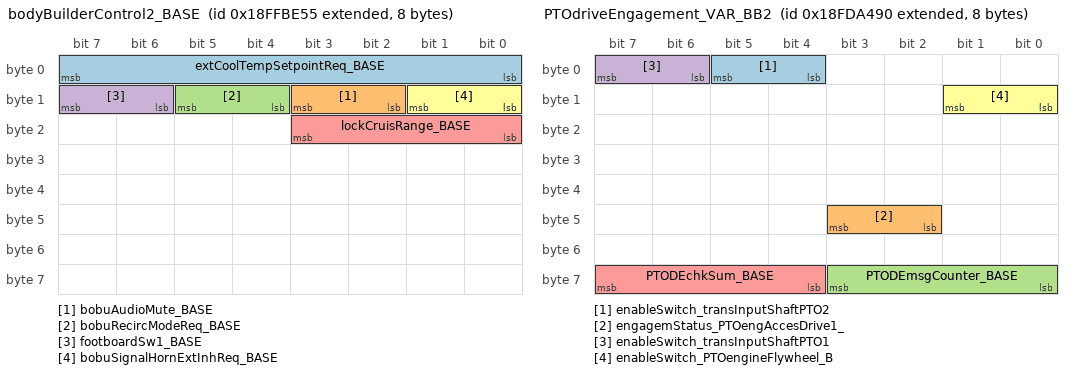
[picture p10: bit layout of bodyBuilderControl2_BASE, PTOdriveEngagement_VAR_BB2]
BO_ 2566897237 bodyBuilderControl2_BASE: 8 CM4
 SG_ extCoolTempSetpointReq_BASE : 0|8@1+ (1,-40) [-40|210] "°C" Vector__XXX
 SG_ bobuAudioMute_BASE : 10|2@1+ (1,0) [0|0] "-" Vector__XXX
 SG_ bobuRecircModeReq_BASE : 12|2@1+ (1,0) [0|0] "-" Vector__XXX
 SG_ footboardSw1_BASE : 14|2@1+ (1,0) [0|0] "-" Vector__XXX
 SG_ lockCruisRange_BASE : 16|4@1+ (1,0) [0|0] "-" Vector__XXX
 SG_ bobuSignalHornExtInhReq_BASE : 8|2@1+ (1,0) [0|0] "-" Vector__XXX

BO_ 2566896278 eHorizon_BASE: 8 CM4
 SG_ eHorizonData_BASE : 0|64@1+ (1,0) [0|18446744073709551616] "-" Vector__XXX

BO_ 2566759568 PTOdriveEngagement_VAR_BB2: 8 CM4
 SG_ enableSwitch_transInputShaftPTO2 : 4|2@1+ (1,0) [0|0] "-" Vector__XXX
 SG_ engagemStatus_PTOengAccesDrive1_ : 42|2@1+ (1,0) [0|0] "-" Vector__XXX
 SG_ PTODEmsgCounter_BASE : 56|4@1+ (1,0) [0|7] "count" Vector__XXX
 SG_ enableSwitch_transInputShaftPTO1 : 6|2@1+ (1,0) [0|0] "-" Vector__XXX
 SG_ PTODEchkSum_BASE : 60|4@1+ (1,0) [0|7] "count" Vector__XXX
 SG_ enableSwitch_PTOengineFlywheel_B : 8|2@1+ (1,0) [0|0] "-" Vector__XXX

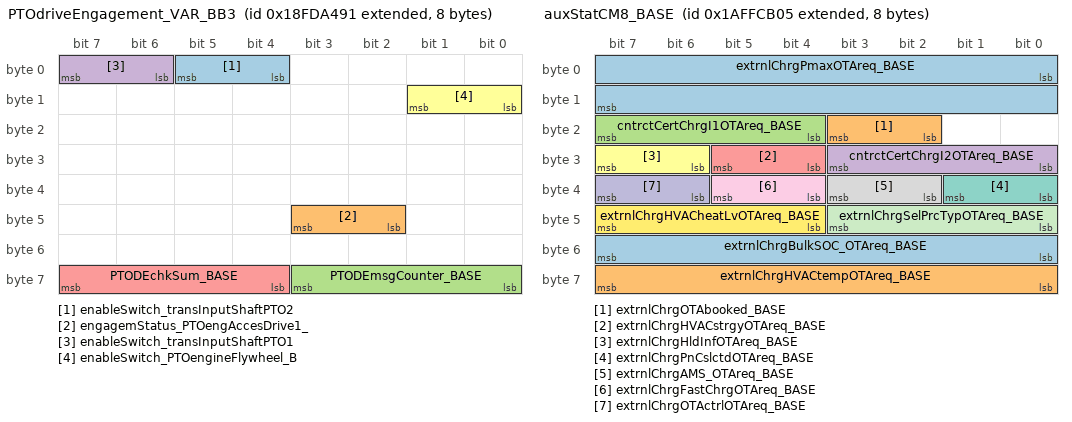
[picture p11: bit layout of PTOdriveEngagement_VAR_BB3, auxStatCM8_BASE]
BO_ 2566759569 PTOdriveEngagement_VAR_BB3: 8 CM4
 SG_ enableSwitch_transInputShaftPTO2 : 4|2@1+ (1,0) [0|0] "-" Vector__XXX
 SG_ engagemStatus_PTOengAccesDrive1_ : 42|2@1+ (1,0) [0|0] "-" Vector__XXX
 SG_ PTODEmsgCounter_BASE : 56|4@1+ (1,0) [0|7] "count" Vector__XXX
 SG_ enableSwitch_transInputShaftPTO1 : 6|2@1+ (1,0) [0|0] "-" Vector__XXX
 SG_ PTODEchkSum_BASE : 60|4@1+ (1,0) [0|7] "count" Vector__XXX
 SG_ enableSwitch_PTOengineFlywheel_B : 8|2@1+ (1,0) [0|0] "-" Vector__XXX

BO_ 2600454917 auxStatCM8_BASE: 8 CM4
 SG_ extrnlChrgPmaxOTAreq_BASE : 0|16@1+ (0.05,0) [0|3212.75] "kW" Vector__XXX
 SG_ extrnlChrgOTAbooked_BASE : 18|2@1+ (1,0) [0|0] "-" Vector__XXX
 SG_ cntrctCertChrgI1OTAreq_BASE : 20|4@1+ (1,0) [0|0] "-" Vector__XXX
 SG_ cntrctCertChrgI2OTAreq_BASE : 24|4@1+ (1,0) [0|0] "-" Vector__XXX
 SG_ extrnlChrgHVACstrgyOTAreq_BASE : 28|2@1+ (1,0) [0|0] "-" Vector__XXX
 SG_ extrnlChrgHldInfOTAreq_BASE : 30|2@1+ (1,0) [0|0] "-" Vector__XXX
 SG_ extrnlChrgPnCslctdOTAreq_BASE : 32|2@1+ (1,0) [0|0] "-" Vector__XXX
 SG_ extrnlChrgAMS_OTAreq_BASE : 34|2@1+ (1,0) [0|0] "-" Vector__XXX
 SG_ extrnlChrgFastChrgOTAreq_BASE : 36|2@1+ (1,0) [0|0] "-" Vector__XXX
 SG_ extrnlChrgOTActrlOTAreq_BASE : 38|2@1+ (1,0) [0|0] "-" Vector__XXX
 SG_ extrnlChrgSelPrcTypOTAreq_BASE : 40|4@1+ (1,0) [0|0] "-" Vector__XXX
 SG_ extrnlChrgHVACheatLvOTAreq_BASE : 44|4@1+ (1,0) [0|10] "-" Vector__XXX
 SG_ extrnlChrgBulkSOC_OTAreq_BASE : 48|8@1+ (0.5,0) [0|100] "%" Vector__XXX
 SG_ extrnlChrgHVACtempOTAreq_BASE : 56|8@1+ (0.1,16) [16|41] "°C" Vector__XXX

BO_ 2600454920 auxStatCM11_BASE: 8 CM4
 SG_ mapVersion_BASE : 0|64@1+ (1,0) [0|0] "-" Vector__XXX

BO_ 2564502513 UDSreqFCN_F1_OBD: 8 CM4
 SG_ UDSreq_F1_OBD : 0|8@1+ (1,0) [0|255] "-" Vector__XXX

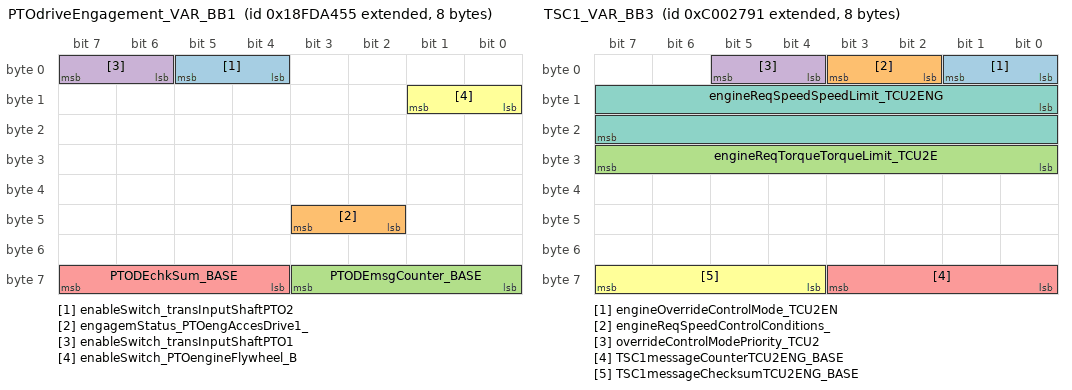
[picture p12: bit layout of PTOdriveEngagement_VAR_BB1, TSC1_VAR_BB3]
BO_ 2566759509 PTOdriveEngagement_VAR_BB1: 8 CM4
 SG_ enableSwitch_transInputShaftPTO2 : 4|2@1+ (1,0) [0|0] "-" Vector__XXX
 SG_ engagemStatus_PTOengAccesDrive1_ : 42|2@1+ (1,0) [0|0] "-" Vector__XXX
 SG_ PTODEmsgCounter_BASE : 56|4@1+ (1,0) [0|7] "count" Vector__XXX
 SG_ enableSwitch_transInputShaftPTO1 : 6|2@1+ (1,0) [0|0] "-" Vector__XXX
 SG_ PTODEchkSum_BASE : 60|4@1+ (1,0) [0|7] "count" Vector__XXX
 SG_ enableSwitch_PTOengineFlywheel_B : 8|2@1+ (1,0) [0|0] "-" Vector__XXX

BO_ 2348820369 TSC1_VAR_BB3: 8 CM4
 SG_ engineOverrideControlMode_TCU2EN : 0|2@1+ (1,0) [0|0] "-" Vector__XXX
 SG_ engineReqSpeedControlConditions_ : 2|2@1+ (1,0) [0|0] "-" Vector__XXX
 SG_ engineReqTorqueTorqueLimit_TCU2E : 24|8@1+ (1,-125) [-125|125] "%" Vector__XXX
 SG_ overrideControlModePriority_TCU2 : 4|2@1+ (1,0) [0|0] "-" Vector__XXX
 SG_ TSC1messageCounterTCU2ENG_BASE : 56|4@1+ (1,0) [0|7] "count" Vector__XXX
 SG_ TSC1messageChecksumTCU2ENG_BASE : 60|4@1+ (1,0) [0|7] "count" Vector__XXX
 SG_ engineReqSpeedSpeedLimit_TCU2ENG : 8|16@1+ (0.125,0) [0|8031.875] "rpm" Vector__XXX

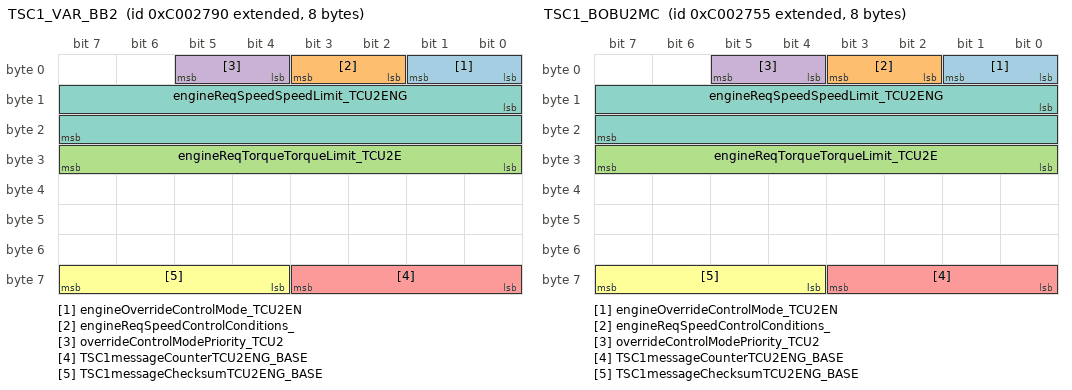
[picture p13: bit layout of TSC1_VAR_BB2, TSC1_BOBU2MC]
BO_ 2348820368 TSC1_VAR_BB2: 8 CM4
 SG_ engineOverrideControlMode_TCU2EN : 0|2@1+ (1,0) [0|0] "-" Vector__XXX
 SG_ engineReqSpeedControlConditions_ : 2|2@1+ (1,0) [0|0] "-" Vector__XXX
 SG_ engineReqTorqueTorqueLimit_TCU2E : 24|8@1+ (1,-125) [-125|125] "%" Vector__XXX
 SG_ overrideControlModePriority_TCU2 : 4|2@1+ (1,0) [0|0] "-" Vector__XXX
 SG_ TSC1messageCounterTCU2ENG_BASE : 56|4@1+ (1,0) [0|7] "count" Vector__XXX
 SG_ TSC1messageChecksumTCU2ENG_BASE : 60|4@1+ (1,0) [0|7] "count" Vector__XXX
 SG_ engineReqSpeedSpeedLimit_TCU2ENG : 8|16@1+ (0.125,0) [0|8031.875] "rpm" Vector__XXX

BO_ 2348820309 TSC1_BOBU2MC: 8 CM4
 SG_ engineOverrideControlMode_TCU2EN : 0|2@1+ (1,0) [0|0] "-" Vector__XXX
 SG_ engineReqSpeedControlConditions_ : 2|2@1+ (1,0) [0|0] "-" Vector__XXX
 SG_ engineReqTorqueTorqueLimit_TCU2E : 24|8@1+ (1,-125) [-125|125] "%" Vector__XXX
 SG_ overrideControlModePriority_TCU2 : 4|2@1+ (1,0) [0|0] "-" Vector__XXX
 SG_ TSC1messageCounterTCU2ENG_BASE : 56|4@1+ (1,0) [0|15] "count" Vector__XXX
 SG_ TSC1messageChecksumTCU2ENG_BASE : 60|4@1+ (1,0) [0|15] "count" Vector__XXX
 SG_ engineReqSpeedSpeedLimit_TCU2ENG : 8|16@1+ (0.125,0) [0|8031.875] "rpm" Vector__XXX

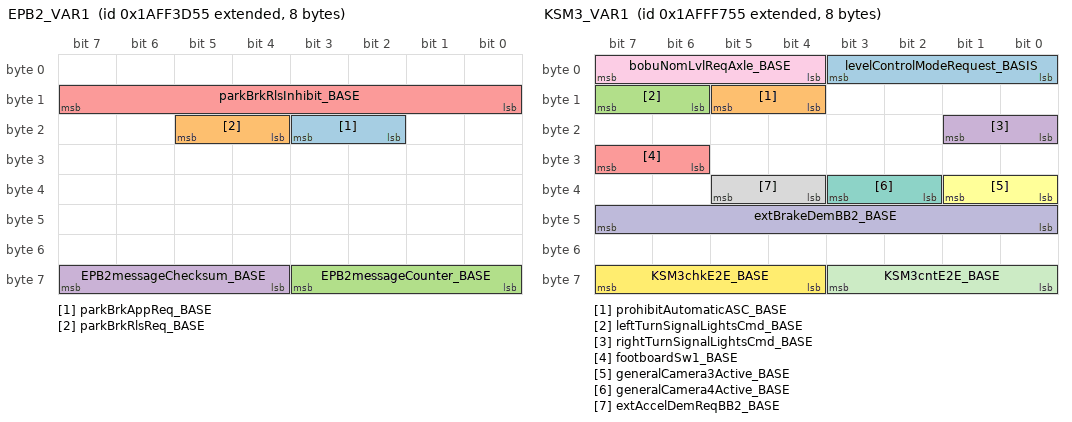
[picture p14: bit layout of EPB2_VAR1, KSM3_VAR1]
BO_ 2600418645 EPB2_VAR1: 8 CM4
 SG_ parkBrkAppReq_BASE : 18|2@1+ (1,0) [0|0] "-" Vector__XXX
 SG_ parkBrkRlsReq_BASE : 20|2@1+ (1,0) [0|0] "-" Vector__XXX
 SG_ EPB2messageCounter_BASE : 56|4@1+ (1,0) [0|15] "count" Vector__XXX
 SG_ EPB2messageChecksum_BASE : 60|4@1+ (1,0) [0|15] "count" Vector__XXX
 SG_ parkBrkRlsInhibit_BASE : 8|8@1+ (1,0) [0|0] "-" Vector__XXX

BO_ 2600466261 KSM3_VAR1: 8 CM4
 SG_ levelControlModeRequest_BASIS : 0|4@1+ (1,0) [0|0] "-" Vector__XXX
 SG_ prohibitAutomaticASC_BASE : 12|2@1+ (1,0) [0|0] "-" Vector__XXX
 SG_ leftTurnSignalLightsCmd_BASE : 14|2@1+ (1,0) [0|0] "-" Vector__XXX
 SG_ rightTurnSignalLightsCmd_BASE : 16|2@1+ (1,0) [0|0] "-" Vector__XXX
 SG_ footboardSw1_BASE : 30|2@1+ (1,0) [0|0] "-" Vector__XXX
 SG_ generalCamera3Active_BASE : 32|2@1+ (1,0) [0|0] "-" Vector__XXX
 SG_ generalCamera4Active_BASE : 34|2@1+ (1,0) [0|0] "-" Vector__XXX
 SG_ extAccelDemReqBB2_BASE : 36|2@1+ (1,0) [0|0] "-" Vector__XXX
 SG_ bobuNomLvlReqAxle_BASE : 4|4@1+ (1,0) [0|0] "-" Vector__XXX
 SG_ extBrakeDemBB2_BASE : 40|8@1+ (0.02,-5) [-5|0] "m/s²" Vector__XXX
 SG_ KSM3cntE2E_BASE : 56|4@1+ (1,0) [0|15] "-" Vector__XXX
 SG_ KSM3chkE2E_BASE : 60|4@1+ (1,0) [0|15] "-" Vector__XXX

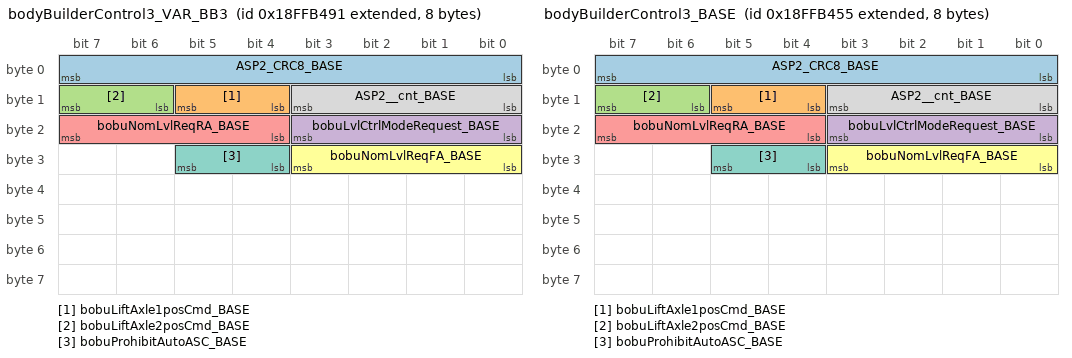
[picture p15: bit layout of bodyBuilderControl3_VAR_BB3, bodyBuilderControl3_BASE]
BO_ 2566894737 bodyBuilderControl3_VAR_BB3: 8 CM4
 SG_ ASP2_CRC8_BASE : 0|8@1+ (1,0) [0|255] "-" Vector__XXX
 SG_ bobuLiftAxle1posCmd_BASE : 12|2@1+ (1,0) [0|0] "-" Vector__XXX
 SG_ bobuLiftAxle2posCmd_BASE : 14|2@1+ (1,0) [0|0] "-" Vector__XXX
 SG_ bobuLvlCtrlModeRequest_BASE : 16|4@1+ (1,0) [0|0] "-" Vector__XXX
 SG_ bobuNomLvlReqRA_BASE : 20|4@1+ (1,0) [0|0] "-" Vector__XXX
 SG_ bobuNomLvlReqFA_BASE : 24|4@1+ (1,0) [0|0] "-" Vector__XXX
 SG_ bobuProhibitAutoASC_BASE : 28|2@1+ (1,0) [0|0] "-" Vector__XXX
 SG_ ASP2__cnt_BASE : 8|4@1+ (1,0) [0|15] "-" Vector__XXX

BO_ 2566894677 bodyBuilderControl3_BASE: 8 CM4
 SG_ ASP2_CRC8_BASE : 0|8@1+ (1,0) [0|255] "-" Vector__XXX
 SG_ bobuLiftAxle1posCmd_BASE : 12|2@1+ (1,0) [0|0] "-" Vector__XXX
 SG_ bobuLiftAxle2posCmd_BASE : 14|2@1+ (1,0) [0|0] "-" Vector__XXX
 SG_ bobuLvlCtrlModeRequest_BASE : 16|4@1+ (1,0) [0|0] "-" Vector__XXX
 SG_ bobuNomLvlReqRA_BASE : 20|4@1+ (1,0) [0|0] "-" Vector__XXX
 SG_ bobuNomLvlReqFA_BASE : 24|4@1+ (1,0) [0|0] "-" Vector__XXX
 SG_ bobuProhibitAutoASC_BASE : 28|2@1+ (1,0) [0|0] "-" Vector__XXX
 SG_ ASP2__cnt_BASE : 8|4@1+ (1,0) [0|15] "-" Vector__XXX

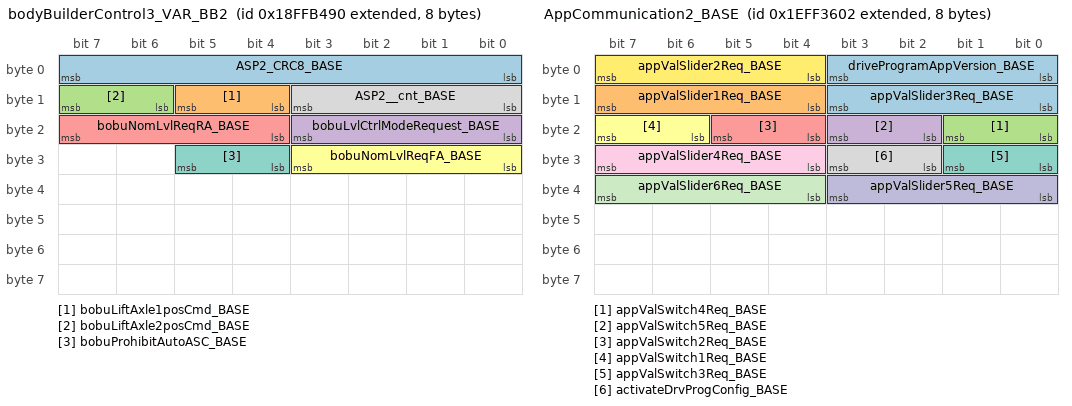
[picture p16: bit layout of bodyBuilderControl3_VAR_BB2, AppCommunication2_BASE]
BO_ 2566894736 bodyBuilderControl3_VAR_BB2: 8 CM4
 SG_ ASP2_CRC8_BASE : 0|8@1+ (1,0) [0|255] "-" Vector__XXX
 SG_ bobuLiftAxle1posCmd_BASE : 12|2@1+ (1,0) [0|0] "-" Vector__XXX
 SG_ bobuLiftAxle2posCmd_BASE : 14|2@1+ (1,0) [0|0] "-" Vector__XXX
 SG_ bobuLvlCtrlModeRequest_BASE : 16|4@1+ (1,0) [0|0] "-" Vector__XXX
 SG_ bobuNomLvlReqRA_BASE : 20|4@1+ (1,0) [0|0] "-" Vector__XXX
 SG_ bobuNomLvlReqFA_BASE : 24|4@1+ (1,0) [0|0] "-" Vector__XXX
 SG_ bobuProhibitAutoASC_BASE : 28|2@1+ (1,0) [0|0] "-" Vector__XXX
 SG_ ASP2__cnt_BASE : 8|4@1+ (1,0) [0|15] "-" Vector__XXX

BO_ 2600454921 auxStatCM12_BASE: 8 CM4
 SG_ conMapMaxSpdLimMotorway_BASE : 0|8@1+ (1,0) [0|250] "km/h" Vector__XXX
 SG_ conMapMaxSpdLimSC_BASE : 16|8@1+ (1,0) [0|250] "km/h" Vector__XXX
 SG_ conMapMaxSpdLimRural_BASE : 24|8@1+ (1,0) [0|250] "km/h" Vector__XXX
 SG_ conMapMaxSpdLimUrban_BASE : 32|8@1+ (1,0) [0|250] "km/h" Vector__XXX
 SG_ conMapMaxSpdLimPlayStreet_BASE : 40|8@1+ (1,0) [0|250] "km/h" Vector__XXX
 SG_ conMapMaxSpdLimDC_BASE : 8|8@1+ (1,0) [0|250] "km/h" Vector__XXX

BO_ 2667525634 AppCommunication2_BASE: 8 CM4
 SG_ driveProgramAppVersion_BASE : 0|4@1+ (1,0) [0|15] "-" Vector__XXX
 SG_ appValSlider1Req_BASE : 12|4@1+ (0.1,0) [0|1] "-" Vector__XXX
 SG_ appValSwitch4Req_BASE : 16|2@1+ (1,0) [0|0] "-" Vector__XXX
 SG_ appValSwitch5Req_BASE : 18|2@1+ (1,0) [0|0] "-" Vector__XXX
 SG_ appValSwitch2Req_BASE : 20|2@1+ (1,0) [0|0] "-" Vector__XXX
 SG_ appValSwitch1Req_BASE : 22|2@1+ (1,0) [0|0] "-" Vector__XXX
 SG_ appValSwitch3Req_BASE : 24|2@1+ (1,0) [0|0] "-" Vector__XXX
 SG_ activateDrvProgConfig_BASE : 26|2@1+ (1,0) [0|0] "-" Vector__XXX
 SG_ appValSlider4Req_BASE : 28|4@1+ (0.1,0) [0|1] "-" Vector__XXX
 SG_ appValSlider5Req_BASE : 32|4@1+ (0.1,0) [0|1] "-" Vector__XXX
 SG_ appValSlider6Req_BASE : 36|4@1+ (0.1,0) [0|1] "-" Vector__XXX
 SG_ appValSlider2Req_BASE : 4|4@1+ (0.1,0) [0|1] "-" Vector__XXX
 SG_ appValSlider3Req_BASE : 8|4@1+ (0.1,0) [0|1] "-" Vector__XXX

BO_ 2600454912 auxStatCM4_BASE: 8 CM4
 SG_ chllngngEnvrnmntDet_BASE : 0|2@1+ (1,0) [0|0] "-" Vector__XXX

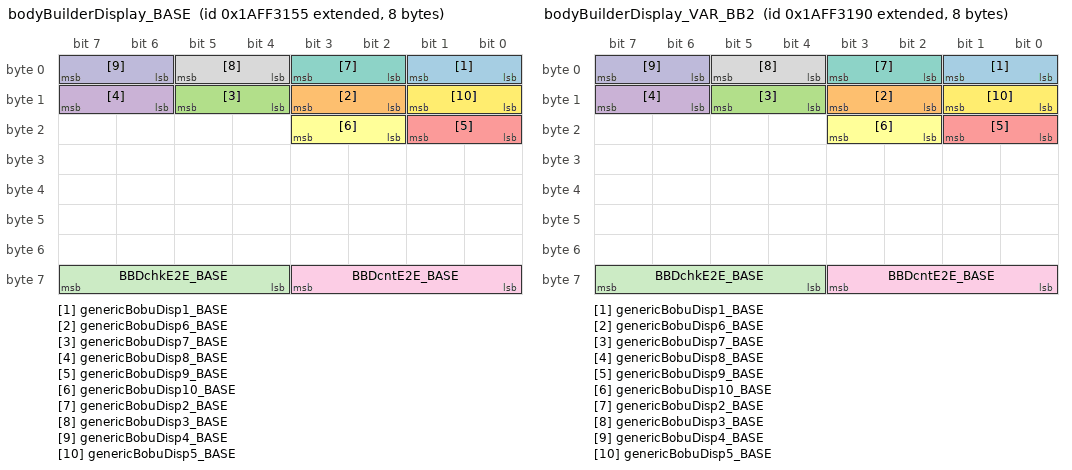
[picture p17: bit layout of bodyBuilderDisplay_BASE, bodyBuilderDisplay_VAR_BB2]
BO_ 2600415573 bodyBuilderDisplay_BASE: 8 CM4
 SG_ genericBobuDisp1_BASE : 0|2@1+ (1,0) [0|0] "-" Vector__XXX
 SG_ genericBobuDisp6_BASE : 10|2@1+ (1,0) [0|0] "-" Vector__XXX
 SG_ genericBobuDisp7_BASE : 12|2@1+ (1,0) [0|0] "-" Vector__XXX
 SG_ genericBobuDisp8_BASE : 14|2@1+ (1,0) [0|0] "-" Vector__XXX
 SG_ genericBobuDisp9_BASE : 16|2@1+ (1,0) [0|0] "-" Vector__XXX
 SG_ genericBobuDisp10_BASE : 18|2@1+ (1,0) [0|0] "-" Vector__XXX
 SG_ genericBobuDisp2_BASE : 2|2@1+ (1,0) [0|0] "-" Vector__XXX
 SG_ genericBobuDisp3_BASE : 4|2@1+ (1,0) [0|0] "-" Vector__XXX
 SG_ BBDcntE2E_BASE : 56|4@1+ (1,0) [0|15] "-" Vector__XXX
 SG_ genericBobuDisp4_BASE : 6|2@1+ (1,0) [0|0] "-" Vector__XXX
 SG_ BBDchkE2E_BASE : 60|4@1+ (1,0) [0|15] "-" Vector__XXX
 SG_ genericBobuDisp5_BASE : 8|2@1+ (1,0) [0|0] "-" Vector__XXX

BO_ 2600415632 bodyBuilderDisplay_VAR_BB2: 8 CM4
 SG_ genericBobuDisp1_BASE : 0|2@1+ (1,0) [0|0] "-" Vector__XXX
 SG_ genericBobuDisp6_BASE : 10|2@1+ (1,0) [0|0] "-" Vector__XXX
 SG_ genericBobuDisp7_BASE : 12|2@1+ (1,0) [0|0] "-" Vector__XXX
 SG_ genericBobuDisp8_BASE : 14|2@1+ (1,0) [0|0] "-" Vector__XXX
 SG_ genericBobuDisp9_BASE : 16|2@1+ (1,0) [0|0] "-" Vector__XXX
 SG_ genericBobuDisp10_BASE : 18|2@1+ (1,0) [0|0] "-" Vector__XXX
 SG_ genericBobuDisp2_BASE : 2|2@1+ (1,0) [0|0] "-" Vector__XXX
 SG_ genericBobuDisp3_BASE : 4|2@1+ (1,0) [0|0] "-" Vector__XXX
 SG_ BBDcntE2E_BASE : 56|4@1+ (1,0) [0|15] "-" Vector__XXX
 SG_ genericBobuDisp4_BASE : 6|2@1+ (1,0) [0|0] "-" Vector__XXX
 SG_ BBDchkE2E_BASE : 60|4@1+ (1,0) [0|15] "-" Vector__XXX
 SG_ genericBobuDisp5_BASE : 8|2@1+ (1,0) [0|0] "-" Vector__XXX

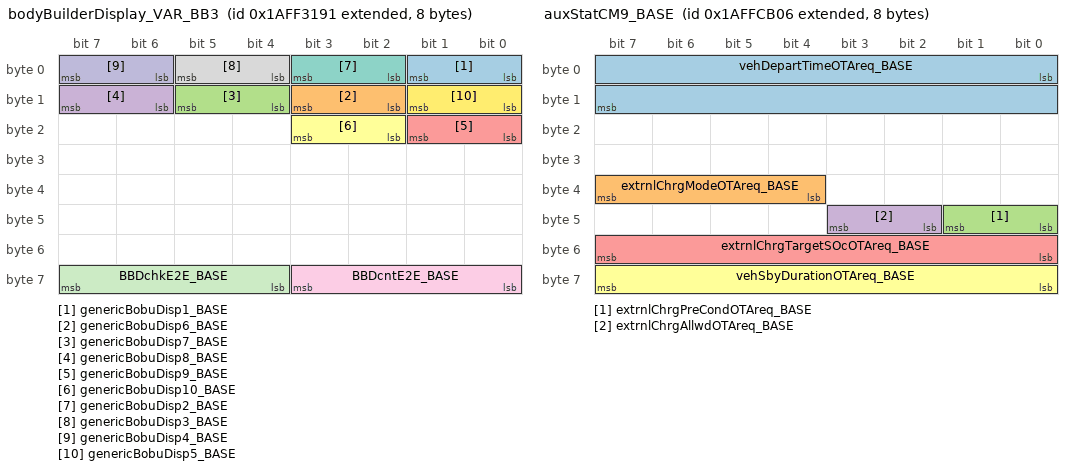
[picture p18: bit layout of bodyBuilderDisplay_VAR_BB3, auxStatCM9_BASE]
BO_ 2600415633 bodyBuilderDisplay_VAR_BB3: 8 CM4
 SG_ genericBobuDisp1_BASE : 0|2@1+ (1,0) [0|0] "-" Vector__XXX
 SG_ genericBobuDisp6_BASE : 10|2@1+ (1,0) [0|0] "-" Vector__XXX
 SG_ genericBobuDisp7_BASE : 12|2@1+ (1,0) [0|0] "-" Vector__XXX
 SG_ genericBobuDisp8_BASE : 14|2@1+ (1,0) [0|0] "-" Vector__XXX
 SG_ genericBobuDisp9_BASE : 16|2@1+ (1,0) [0|0] "-" Vector__XXX
 SG_ genericBobuDisp10_BASE : 18|2@1+ (1,0) [0|0] "-" Vector__XXX
 SG_ genericBobuDisp2_BASE : 2|2@1+ (1,0) [0|0] "-" Vector__XXX
 SG_ genericBobuDisp3_BASE : 4|2@1+ (1,0) [0|0] "-" Vector__XXX
 SG_ BBDcntE2E_BASE : 56|4@1+ (1,0) [0|15] "-" Vector__XXX
 SG_ genericBobuDisp4_BASE : 6|2@1+ (1,0) [0|0] "-" Vector__XXX
 SG_ BBDchkE2E_BASE : 60|4@1+ (1,0) [0|15] "-" Vector__XXX
 SG_ genericBobuDisp5_BASE : 8|2@1+ (1,0) [0|0] "-" Vector__XXX

BO_ 2600454925 auxStatCM16_BASE: 8 CM4
 SG_ auxStatCM16placeholder_BASE : 0|8@1+ (1,0) [0|255] "-" Vector__XXX

BO_ 2600454924 auxStatCM15_BASE: 8 CM4
 SG_ auxStatCM15placeholder_BASE : 0|8@1+ (1,0) [0|255] "-" Vector__XXX

BO_ 2600454927 auxStatCM18_BASE: 8 CM4
 SG_ auxStatCM18placeholder_BASE : 0|8@1+ (1,0) [0|255] "-" Vector__XXX

BO_ 2600454928 auxStatCM19_BASE: 8 CM4
 SG_ auxStatCM19placeholder_BASE : 0|8@1+ (1,0) [0|255] "-" Vector__XXX

BO_ 2600454929 auxStatCM20_BASE: 8 CM4
 SG_ auxStatCM20placeholder_BASE : 0|8@1+ (1,0) [0|255] "-" Vector__XXX

BO_ 2600454926 auxStatCM17_BASE: 8 CM4
 SG_ auxStatCM17placeholder_BASE : 0|8@1+ (1,0) [0|255] "-" Vector__XXX

BO_ 2600454931 auxStatCM22_BASE: 8 CM4
 SG_ auxStatCM22placeholder_BASE : 0|8@1+ (1,0) [0|255] "-" Vector__XXX

BO_ 2600454930 auxStatCM21_BASE: 8 CM4
 SG_ auxStatCM21placeholder_BASE : 0|8@1+ (1,0) [0|255] "-" Vector__XXX

BO_ 2600454918 auxStatCM9_BASE: 8 CM4
 SG_ vehDepartTimeOTAreq_BASE : 0|16@1+ (1,0) [0|64255] "min" Vector__XXX
 SG_ extrnlChrgModeOTAreq_BASE : 36|4@1+ (1,0) [0|0] "-" Vector__XXX
 SG_ extrnlChrgPreCondOTAreq_BASE : 40|2@1+ (1,0) [0|0] "-" Vector__XXX
 SG_ extrnlChrgAllwdOTAreq_BASE : 42|2@1+ (1,0) [0|0] "-" Vector__XXX
 SG_ extrnlChrgTargetSOcOTAreq_BASE : 48|8@1+ (0.4,0) [0|100] "%" Vector__XXX
 SG_ vehSbyDurationOTAreq_BASE : 56|8@1+ (1,0) [0|250] "min" Vector__XXX

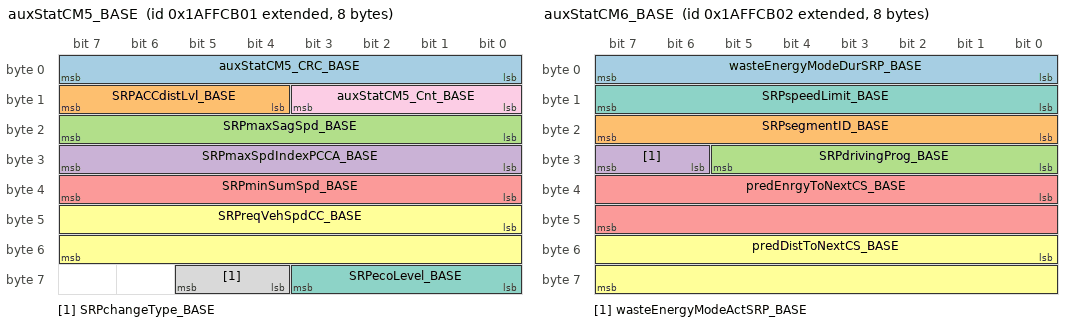
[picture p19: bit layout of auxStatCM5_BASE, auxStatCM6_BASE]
BO_ 2600454913 auxStatCM5_BASE: 8 CM4
 SG_ auxStatCM5_CRC_BASE : 0|8@1+ (1,0) [0|255] "-" Vector__XXX
 SG_ SRPACCdistLvl_BASE : 12|4@1+ (1,0) [0|4] "-" Vector__XXX
 SG_ SRPmaxSagSpd_BASE : 16|8@1+ (1,0) [0|250] "km/h" Vector__XXX
 SG_ SRPmaxSpdIndexPCCA_BASE : 24|8@1+ (1,0) [0|11] "-" Vector__XXX
 SG_ SRPminSumSpd_BASE : 32|8@1+ (1,0) [0|250] "km/h" Vector__XXX
 SG_ SRPreqVehSpdCC_BASE : 40|16@1+ (0.00390625,0) [0|200] "km/h" Vector__XXX
 SG_ SRPecoLevel_BASE : 56|4@1+ (1,0) [0|0] "-" Vector__XXX
 SG_ SRPchangeType_BASE : 60|2@1+ (1,0) [0|0] "-" Vector__XXX
 SG_ auxStatCM5_Cnt_BASE : 8|4@1+ (1,0) [0|15] "-" Vector__XXX

BO_ 2600454914 auxStatCM6_BASE: 8 CM4
 SG_ wasteEnergyModeDurSRP_BASE : 0|8@1+ (30,0) [0|3600] "s" Vector__XXX
 SG_ SRPsegmentID_BASE : 16|8@1+ (1,0) [0|250] "-" Vector__XXX
 SG_ SRPdrivingProg_BASE : 24|6@1+ (1,-1) [-1|62] "-" Vector__XXX
 SG_ wasteEnergyModeActSRP_BASE : 30|2@1+ (1,0) [0|0] "-" Vector__XXX
 SG_ predEnrgyToNextCS_BASE : 32|16@1+ (0.05,0) [0|3212.75] "kWh" Vector__XXX
 SG_ predDistToNextCS_BASE : 48|16@1+ (0.05,0) [0|3212.75] "km" Vector__XXX
 SG_ SRPspeedLimit_BASE : 8|8@1+ (1,0) [0|250] "km/h" Vector__XXX

CM_ SG_ 2348885845 disengageDrivelineRequest_BASIS "Command signal used to simply disengage the driveline, e.g., to prevent engine drag torque from causing high wheel slip on slippery surfaces.";
CM_ SG_ 2348885845 transmissionMode1_BASE "Indicates whether transmission mode 1 is enabled. Modes are manufacturer specific and are not necessarily mutually exclusive. See also SPN 2536.";
CM_ BO_ 2566894933 "body builder control 4 message";
CM_ SG_ 2566894933 bobuCAMreq1_BASE "Signal to activate the first customer camera on the infotainment system. Examples: turning Cam assistant or birdview. This signal is triggered via customer CAN.";
CM_ SG_ 2566894933 bobuCAMreq2_BASE "Signal to activate the second customer camera on the infotainment system. Examples: turning Cam assistant or birdview. This signal is triggered via customer CAN.";
CM_ SG_ 2566894933 bobuCAMreq3_BASE "Signal to activate the 3. customer camera on the infotainment system. Examples: turning Cam assistant or birdview. This signal is triggered via customer CAN.";
CM_ SG_ 2566894933 bobuCAMreq4_BASE "Signal to activate the 4. customer camera on the infotainment system. Examples: turning Cam assistant or birdview. This signal is triggered via customer CAN.";
CM_ SG_ 2566894933 bobuCAMreq5_BASE "Signal to activate the 5. customer camera on the infotainment system. Examples: turning Cam assistant or birdview. This signal is triggered via customer CAN.";
CM_ BO_ 2566656597 "Cab Door Control 1 This message requests or commands the cabin door functionality; door latches, windows, and mirrors. Doors are numbered left to right, front to back.  Prio 6 instead of default Prio 5.";
CM_ SG_ 2566656597 leftFrontWindowPositionCommand_B "Commands position change of left front window (driver door window on left-hand steer vehicles).";
CM_ SG_ 2566656597 righFrontWindowPositionCommand_B "Commands position change of right front window (passenger door window on left-hand steer vehicles).&#x0D;";
CM_ SG_ 2566656597 remoteCabDoorLockRequest_BASE "Request to the cab door lock controller from Remote Keyless Entry or or other external device to lock or unlock doors.This parameter is different from Cab Doors Lock Actuation Command (SPN 7727) because this is a request to actuate door locks. Based on se";
CM_ BO_ 2564816981 "Message containing parameters originating from the vehicle cab. ";
CM_ SG_ 2348885904 disengageDrivelineRequest_BASIS "Command signal used to simply disengage the driveline, e.g., to prevent engine drag torque from causing high wheel slip on slippery surfaces.";
CM_ SG_ 2348885904 transmissionMode1_BASE "Indicates whether transmission mode 1 is enabled. Modes are manufacturer specific and are not necessarily mutually exclusive. See also SPN 2536.";
CM_ BO_ 2566894992 "body builder control 4 message";
CM_ SG_ 2566894992 bobuCAMreq1_BASE "Signal to activate the first customer camera on the infotainment system. Examples: turning Cam assistant or birdview. This signal is triggered via customer CAN.";
CM_ SG_ 2566894992 bobuCAMreq2_BASE "Signal to activate the second customer camera on the infotainment system. Examples: turning Cam assistant or birdview. This signal is triggered via customer CAN.";
CM_ SG_ 2566894992 bobuCAMreq3_BASE "Signal to activate the 3. customer camera on the infotainment system. Examples: turning Cam assistant or birdview. This signal is triggered via customer CAN.";
CM_ SG_ 2566894992 bobuCAMreq4_BASE "Signal to activate the 4. customer camera on the infotainment system. Examples: turning Cam assistant or birdview. This signal is triggered via customer CAN.";
CM_ SG_ 2566894992 bobuCAMreq5_BASE "Signal to activate the 5. customer camera on the infotainment system. Examples: turning Cam assistant or birdview. This signal is triggered via customer CAN.";
CM_ SG_ 2566897296 extCoolTempSetpointReq_BASE "external Request of Setpoint for the coolant temperature";
CM_ SG_ 2566897296 bobuAudioMute_BASE "external audio mute request";
CM_ SG_ 2566897296 bobuRecircModeReq_BASE "external request for HVAC recirculation";
CM_ SG_ 2566897296 lockCruisRange_BASE "lock eval driving range";
CM_ SG_ 2566897296 bobuSignalHornExtInhReq_BASE "external signal horn inhibit request";
CM_ BO_ 2564817040 "Message containing parameters originating from the vehicle cab. ";
CM_ BO_ 2566656656 "Cab Door Control 1 This message requests or commands the cabin door functionality; door latches, windows, and mirrors. Doors are numbered left to right, front to back.  Prio 6 instead of default Prio 5.";
CM_ SG_ 2566656656 leftFrontWindowPositionCommand_B "Commands position change of left front window (driver door window on left-hand steer vehicles).";
CM_ SG_ 2566656656 righFrontWindowPositionCommand_B "Commands position change of right front window (passenger door window on left-hand steer vehicles).&#x0D;";
CM_ SG_ 2566656656 remoteCabDoorLockRequest_BASE "Request to the cab door lock controller from Remote Keyless Entry or or other external device to lock or unlock doors.This parameter is different from Cab Doors Lock Actuation Command (SPN 7727) because this is a request to actuate door locks. Based on se";
CM_ BO_ 2365443216 "The message containing the information about the position of the operator's external light control switch(s). Including switches for the Headlights, turn signals, hazard light, clearance lights, marker lights, etc.";
CM_ SG_ 2365443216 hazardLightSwitch_BASE "A 2 bit parameter to indicate the selected position of the operator's hazard light switch.";
CM_ BO_ 2564817041 "Message containing parameters originating from the vehicle cab. ";
CM_ BO_ 2566656657 "Cab Door Control 1 This message requests or commands the cabin door functionality; door latches, windows, and mirrors. Doors are numbered left to right, front to back.  Prio 6 instead of default Prio 5.";
CM_ SG_ 2566656657 leftFrontWindowPositionCommand_B "Commands position change of left front window (driver door window on left-hand steer vehicles).";
CM_ SG_ 2566656657 righFrontWindowPositionCommand_B "Commands position change of right front window (passenger door window on left-hand steer vehicles).&#x0D;";
CM_ SG_ 2566656657 remoteCabDoorLockRequest_BASE "Request to the cab door lock controller from Remote Keyless Entry or or other external device to lock or unlock doors.This parameter is different from Cab Doors Lock Actuation Command (SPN 7727) because this is a request to actuate door locks. Based on se";
CM_ BO_ 2365443217 "The message containing the information about the position of the operator's external light control switch(s). Including switches for the Headlights, turn signals, hazard light, clearance lights, marker lights, etc.";
CM_ SG_ 2365443217 hazardLightSwitch_BASE "A 2 bit parameter to indicate the selected position of the operator's hazard light switch.";
CM_ SG_ 2348885905 disengageDrivelineRequest_BASIS "Command signal used to simply disengage the driveline, e.g., to prevent engine drag torque from causing high wheel slip on slippery surfaces.";
CM_ SG_ 2348885905 transmissionMode1_BASE "Indicates whether transmission mode 1 is enabled. Modes are manufacturer specific and are not necessarily mutually exclusive. See also SPN 2536.";
CM_ SG_ 2566897297 extCoolTempSetpointReq_BASE "external Request of Setpoint for the coolant temperature";
CM_ SG_ 2566897297 bobuAudioMute_BASE "external audio mute request";
CM_ SG_ 2566897297 bobuRecircModeReq_BASE "external request for HVAC recirculation";
CM_ SG_ 2566897297 lockCruisRange_BASE "lock eval driving range";
CM_ SG_ 2566897297 bobuSignalHornExtInhReq_BASE "external signal horn inhibit request";
CM_ BO_ 2566894993 "body builder control 4 message";
CM_ SG_ 2566894993 bobuCAMreq1_BASE "Signal to activate the first customer camera on the infotainment system. Examples: turning Cam assistant or birdview. This signal is triggered via customer CAN.";
CM_ SG_ 2566894993 bobuCAMreq2_BASE "Signal to activate the second customer camera on the infotainment system. Examples: turning Cam assistant or birdview. This signal is triggered via customer CAN.";
CM_ SG_ 2566894993 bobuCAMreq3_BASE "Signal to activate the 3. customer camera on the infotainment system. Examples: turning Cam assistant or birdview. This signal is triggered via customer CAN.";
CM_ SG_ 2566894993 bobuCAMreq4_BASE "Signal to activate the 4. customer camera on the infotainment system. Examples: turning Cam assistant or birdview. This signal is triggered via customer CAN.";
CM_ SG_ 2566894993 bobuCAMreq5_BASE "Signal to activate the 5. customer camera on the infotainment system. Examples: turning Cam assistant or birdview. This signal is triggered via customer CAN.";
CM_ BO_ 2565865813 "brake control information";
CM_ SG_ 2633998843 ASP2_CRC8_BASE "CRC8 Autosar Profile 2 with Data ID";
CM_ SG_ 2633998843 boBuAppFCNreq1_BASE "generic bodybuilder app function request 1 function table see eese DOC: bodyBuilderFcnList";
CM_ SG_ 2633998843 boBuAppFCNreq2_BASE "generic bodybuilder app function request 2 function table see eese DOC: bodyBuilderFcnList";
CM_ SG_ 2633998843 boBuAppFCNreq3_BASE "generic bodybuilder app function request 3 function table see eese DOC: bodyBuilderFcnList";
CM_ SG_ 2633998843 boBuAppFCNreq4_BASE "generic bodybuilder app function request 4 function table see eese DOC: bodyBuilderFcnList";
CM_ SG_ 2633998843 boBuAppFCNreq5_BASE "generic bodybuilder app function request 5 function table see eese DOC: bodyBuilderFcnList";
CM_ SG_ 2633998843 boBuAppFCNreq6_BASE "generic bodybuilder app function request 6 function table see eese DOC: bodyBuilderFcnList";
CM_ SG_ 2633998843 ASP2__cnt_BASE "Cnt Autosar Profile 2";
CM_ SG_ 2600458491 vehPosCWGS84LatitudeGNSS_BASE "Latitude position of the vehicle including map matching";
CM_ SG_ 2600458491 vehPosCWGS84LongitudeGNSS_BASE "Longitude position of the vehicle including map matching";
CM_ SG_ 2600458235 vehPosPrecisionGNSS_BASE "Estimated GNSS Precision";
CM_ SG_ 2600458235 timeSynchDelayGNSS_BASE "Time delay between receiption of time signals via GNSS and transmission of CAN message.";
CM_ BO_ 2566842107 "Time/Date - variant for VCM with output of GPS-Time and -date (UTC) Scaling due to SAE J1939  In contrast to the definition according to SAE J1939 the message is sent on event and cyclic with a maximum cycle time of 1500 ms.";
CM_ SG_ 2566842107 seconds_VAR1 "GPS/UTC - VCM The seconds component of the current time of day.";
CM_ SG_ 2566842107 hours_VAR1 "GPS/UTC - VCM The hour component of the current time of day.";
CM_ SG_ 2566842107 month_VAR1 "GPS/UTC - VCM The month component of the current calendar date.";
CM_ SG_ 2566842107 day_VAR1 "GPS/UTC - VCM The day component of the current calendar date.";
CM_ SG_ 2566842107 year_VAR1 "GPS/UTC - VCM The year component of the current calendar date.";
CM_ SG_ 2566842107 localMinuteOffset_VAR1 "GPS/UTC - VCM The minute component of the offset between the UTC time and date and a local time zone time and date.";
CM_ SG_ 2566842107 localHourOffset_VAR1 "GPS/UTC - VCM The hour component of the offset between the UTC (Universal Time Coordinate) time and date and a local time zone time and date.";
CM_ SG_ 2566842107 minutes_VAR1 "GPS/UTC - VCM The minutes component of the current time of day.";
CM_ BO_ 2566649595 "VP2: Vehicle Position according to SAE J1939 - PGN 64502  In contrast to the definition according to SAE J1939 the message is sent on event and cyclic with a maximum cycle time of 1500 ms.";
CM_ SG_ 2566649595 vdopGNSS_BASE "Vertical Dilution of Precision SPN 8130 - Vertical Dilution of Precision";
CM_ SG_ 2566649595 pdopGNSS_BASE "Position Dilution of Precision SPN 8131 - Position Dilution of Precision";
CM_ SG_ 2566649595 tdopGNSS_BASE "Time Dilution of Precision SPN 8132 - Time Dilution of Precision";
CM_ SG_ 2566649595 hdopGNSS_BASE "Horizontal Dilution of Precision SPN 8129 - Horizontal Dilution of Precision";
CM_ BO_ 2566842619 "VDS: Vehicle Direction/Speed due to J1939 - PGN 65256  In contrast to the definition according to SAE J1939 the message is sent on event and cyclic with a maximum cycle time of 1500 ms.";
CM_ SG_ 2566842619 compBearingGNSS_BASE "Present compass bearing of vehicle. SPN 165 - Compass Bearing";
CM_ SG_ 2566842619 vehSpdGNSS_BASE "Vehicle Speed obtained from GNSS Module SPN 517 - Navigation-Based Vehicle Speed";
CM_ SG_ 2566842619 pitchGNSS_BASE "Pitch (rotation about the y-axis) of the vehicle as calculated by the navigation device(s). The pitch angle for an angle of ascent is reported with a positive value. This parameter is defined according to a Z-Down axis system and the sign of the value is ";
CM_ SG_ 2566842619 altitudeGNSS_BASE "The signal describes the altitude of the vehicle referenced to sea level of the GNSS system. SPN 580 - Altitude";
CM_ BO_ 2566845435 "VP1: Vehicle Position 1 due to SAE J1939 - PGN 65267  In contrast to the definition according to SAE J1939 the message is sent on event and cyclic with a maximum cycle time of 1500 ms.";
CM_ SG_ 2566845435 vehPosWGS84LatitudeGNSS_BASE "Latitude as obtained from the GNSS module SPN 584 - Latitude";
CM_ SG_ 2566845435 vehPosWGS84LongitudeGNSS_BASE "Longitude as obtained from the GPS module SPN 585 - Longitude";
CM_ BO_ 2583638267 "Proprietary CAN message appControlInterface / VAR2 sent by the Connectivity Module.  This OnEvent CAN message must not be sent faster than every 100ms.";
CM_ SG_ 2583638267 appFrameworkCtrlAppID_BASE "ID of an specific App - for controlling the app (send ctrl cmd e.g. open chapter 2.4.1) 0 is not an AppID";
CM_ SG_ 2583638267 appFrameworkAppCommand_BASE "Command to controlling a specific app (send ctrl cmd to app e.g. open chapter 2.4.1) Other Commands are: 1 = Trigger the start of an installed app in the background. 2 = Trigger to close an installed app. 3 = Trigger to force quit an running app. 4 = Tr";
CM_ BO_ 2564554736 "UDS req FCN";
CM_ SG_ 2564554736 UDS_FCNF0_TO_ALL "Base signals for UDS";
CM_ BO_ 2600460056 "Proprietary message RTprop1 for responding to requests of remote tester texts according to SOA concept and ServiceSpec_RemoteTesterFeatureList";
CM_ SG_ 2600460056 rmtTstrInstallMsgHeaderRsp_BASE "Response header according to service specification RemoteTesterFeatureList. Please refer also to: Service Specification for RemoteTesterFeatureList (ServiceSpec_RemoteTesterFeatureList.pdf)";
CM_ SG_ 2600460056 rmtTstrInstallPduSize_BASE "Size indicator for the length of the SOA PDU contained in responses of the RemoteTesterFeatureList server. Used in the following responses: RemoteTesterFeatureList_GetJobId_PosResp RemoteTesterFeatureList_GetJobId_NegResp RemoteTesterFeatureList_GetTitles";
CM_ SG_ 2600460056 rmtTstrInstallJobIdResp_BASE "RemoteTester JobId contained in the response of the RemoteTesterFeatureList server. Used in the following responses: RemoteTesterFeatureList_GetJobId_PosResp: Remote tester jobId which was contained in the request. RemoteTesterFeatureList_GetJobId_NegResp";
CM_ SG_ 2600460056 rmtTstrInstallListIdxResp_BASE "RemoteTester list index contained in the response of the RemoteTesterFeatureList server. Used in the following responses: RemoteTesterFeatureList_GetJobId_PosResp: List index which was contained in the request. RemoteTesterFeatureList_GetJobId_NegResp: Li";
CM_ SG_ 2600460056 rmtTstrInstallRespCode_BASE "Denotes the response code, i.e. whether the job-id is valid or the list idx is valid or not. Contained in the response of the RemoteTesterFeatureList server. Used in the following responses: RemoteTesterFeatureList_GetJobId_PosResp: Response code RemoteTe";
CM_ SG_ 2600460056 rmtTstrInstallRespIdx_BASE "Index of the response contained in responses of the RemoteTesterFeatureList server starting with 0. Maximum value is totalNoOfResponses -1. Used in the following responses: RemoteTesterFeatureList_GetJobId_PosResp: Index of the response starting with 0. M";
CM_ SG_ 2600460056 rmtTstrInstallTotNumOfResp_BASE "Total number of responses contained in responses of the RemoteTesterFeatureList server. Used in the following responses: RemoteTesterFeatureList_GetJobId_PosResp: totalNoOfResponses. RemoteTesterFeatureList_GetJobId_NegResp: totalNoOfResponses. RemoteTest";
CM_ SG_ 2600460056 rmtTstrInstallContentSize_BASE "Size indicator for the content contained in positive responses of the RemoteTesterFeatureList server. Used in the following responses: RemoteTesterFeatureList_GetJobId_PosResp: size of job Id (size of the job Id is always one) RemoteTesterFeatureList_GetT";
CM_ SG_ 2600460056 rmtTstrInstallContent_BASE "Data/content contained in a response of the RemoteTesterFeatureList server. Used in the following responses: RemoteTesterFeatureList_GetTitles_PosResp: Title RemoteTesterFeatureList_GetText_PosResp: Detail Text of the corresponding title RemoteTesterFeatu";
CM_ SG_ 2600403195 HB_Wakeup_BASE "contains the wake up reason; If there are several wake up reasons in parallel, the smallest value must be transmitted";
CM_ SG_ 2600403195 NM_CBV_Res2_BASE "Reserved bit 2 in Control Bit Vector (CBV) of AUTOSAR NM must be set to 0.";
CM_ SG_ 2600403195 NM_CBV_Res3_BASE "Reserved bit 3 in Control Bit Vector (CBV) of AUTOSAR NM must be set to 0.";
CM_ SG_ 2600403195 NM_ActiveWakeupBit_BASE "Active Wakeup Bit of AUTOSAR NM";
CM_ SG_ 2600403195 NM_CBV_Res5_BASE "Reserved bit 5 in Control Bit Vector (CBV) of AUTOSAR NM must be set to 0.";
CM_ SG_ 2600403195 NM_CRI_BASE "Signal permanently on, NM layout is according par net operation";
CM_ SG_ 2600403195 NM_CBV_Res7_BASE "Reserved bit 7 in Control Bit Vector (CBV) of AUTOSAR NM must be set to 0.";
CM_ SG_ 2600403195 NM_State_BASE "NM state transition - RM: Repeat Message - BSM: Bus-Sleep Mode - PBSM: Prepare Bus-Sleep Mode - NO: Normal Operation - RS: Ready Sleep";
CM_ SG_ 2600403195 NM_CarWakeup_BASE "Car-Wakeup of NM-High";
CM_ SG_ 2600403195 NM_CC_BASE "Communication Control Indicator";
CM_ SG_ 2600403195 NM_activeClamp15_BASE "ECU can not change to Ready Sleep due to clamp 15 on recognized";
CM_ SG_ 2600403195 NM_activeDiag_BASE "ECU can not change to Ready Sleep due to active diagnostic communication";
CM_ SG_ 2600403195 NM_activeTmin_BASE "ECU can not change to Ready Sleep due to Tmin not exceeded";
CM_ SG_ 2600403195 NM_activeCWU_BASE "ECU can not change to Ready Sleep due to car wake up on recognized";
CM_ SG_ 2600403195 NM_activeFC_BASE "ECU can not change to Ready Sleep due to cluster request recognized";
CM_ SG_ 2600403195 NM_Res29_BASE "Reserved bits 29-35 of CAN message must be set to 0";
CM_ SG_ 2600403195 NM_Res36_BASE "Reserved bits 36-39 of CAN message must be set to 0";
CM_ SG_ 2600403195 nmClusterActive00_BASE "Cluster Active Bit 0";
CM_ SG_ 2600403195 nmClusterActive01_BASE "Cluster Active Bit 1";
CM_ SG_ 2600403195 nmClusterActive02_BASE "Cluster Active Bit 2";
CM_ SG_ 2600403195 nmClusterActive03_BASE "Cluster Active Bit 3";
CM_ SG_ 2600403195 nmClusterActive04_BASE "Cluster Active Bit 4";
CM_ SG_ 2600403195 nmClusterActive05_BASE "Cluster Active Bit 5";
CM_ SG_ 2600403195 nmClusterActive06_BASE "Cluster Active Bit 6";
CM_ SG_ 2600403195 nmClusterActive07_BASE "Cluster Active Bit 7";
CM_ SG_ 2600403195 nmClusterActive08_BASE "Cluster Active Bit 8";
CM_ SG_ 2600403195 nmClusterActive09_BASE "Cluster Active Bit 9";
CM_ SG_ 2600403195 nmClusterActive10_BASE "Cluster Active Bit 10";
CM_ SG_ 2600403195 nmClusterActive11_BASE "Cluster Active Bit 11";
CM_ SG_ 2600403195 nmClusterActive12_BASE "Cluster Active Bit 12";
CM_ SG_ 2600403195 nmClusterActive13_BASE "Cluster Active Bit 13";
CM_ SG_ 2600403195 nmClusterActive14_BASE "Cluster Active Bit 14";
CM_ SG_ 2600403195 nmClusterActive15_BASE "Cluster Active Bit 15";
CM_ SG_ 2600403195 nmClusterActive16_BASE "Cluster Active Bit 16";
CM_ SG_ 2600403195 nmClusterActive17_BASE "Cluster Active Bit 17";
CM_ SG_ 2600403195 nmClusterActive18_BASE "Cluster Active Bit 18";
CM_ SG_ 2600403195 nmClusterActive19_BASE "Cluster Active Bit 19";
CM_ SG_ 2600403195 nmClusterActive20_BASE "Cluster Active Bit 20";
CM_ SG_ 2600403195 nmClusterActive21_BASE "Cluster Active Bit 21";
CM_ SG_ 2600403195 nmClusterActive22_BASE "Cluster Active Bit 22";
CM_ SG_ 2600403195 nmClusterActive23_BASE "Cluster Active Bit 23";
CM_ SG_ 2600403195 NM_CBV_Res0_BASE "Reserved bit 0 in Control Bit Vector (CBV) of AUTOSAR NM must be set to 0.";
CM_ SG_ 2600403195 NM_CBV_Res1_BASE "Reserved bit 1 in Control Bit Vector (CBV) of AUTOSAR NM must be set to 0.";
CM_ BO_ 2365443157 "The message containing the information about the position of the operator's external light control switch(s). Including switches for the Headlights, turn signals, hazard light, clearance lights, marker lights, etc.";
CM_ BO_ 2566895189 "CANMSG: bodyBuilderControl5 for BEV; ASP 2 Data ID No: 455; Data ID: 237 17 76 169 219 217 4 121 90 231 244 199 216 241 196 227;";
CM_ SG_ 2566895189 ASP2_CRC8_BASE "CRC8 Autosar Profile 2 with Data ID";
CM_ SG_ 2566895189 statusBodyEPTO_BASE "current Operating state of the body.";
CM_ SG_ 2566895189 ePTOreqBodyBuilder_BASE "Request to activate ePTO";
CM_ SG_ 2566895189 ASP2__cnt_BASE "Cnt Autosar Profile 2";
CM_ BO_ 2566679953 "Acoustic Warning. This PG contains requests to control the acoustic warning functions of the vehicle. DIN 4630";
CM_ SG_ 2566679953 vehicleHorn_BASE "Vehicle horn";
CM_ SG_ 2566679953 reverseDrivingAlarm_BASE "Reverse driving alarm";
CM_ BO_ 2566679952 "Acoustic Warning. This PG contains requests to control the acoustic warning functions of the vehicle. DIN 4630";
CM_ SG_ 2566679952 vehicleHorn_BASE "Vehicle horn";
CM_ SG_ 2566679952 reverseDrivingAlarm_BASE "Reverse driving alarm";
CM_ BO_ 2566679893 "Acoustic Warning. This PG contains requests to control the acoustic warning functions of the vehicle. DIN 4630";
CM_ SG_ 2566679893 vehicleHorn_BASE "Vehicle horn";
CM_ SG_ 2566679893 reverseDrivingAlarm_BASE "Reverse driving alarm";
CM_ BO_ 2600454915 "CANMSG auxStatCM2";
CM_ SG_ 2600454915 conMapSpdLimDC_BASE "This signal describes the implicit speed limit for dual carriageways in the current country for the current vehicle. 0 - No speed limit or speed limit unknown";
CM_ SG_ 2600454915 conMapSpdLimPlayStreet_BASE "This signal describes the implicit speed limit for playstreets (i.e. home zones) in the current country for the current vehicle. 0 - No speed limit or speed limit unknown";
CM_ SG_ 2600454915 conMapSpdLimRural_BASE "This signal describes the implicit speed limit for rural roads in the current country for the current vehicle. 0 - No speed limit or speed limit unknown";
CM_ SG_ 2600454915 conMapSpdLimMotorway_BASE "This signal describes the implicit [0] speed limit for motorways in the current country for the current vehicle. 0 - No speed limit or speed limit unknown";
CM_ SG_ 2600454915 conMapSpdLimUrban_BASE "This signal describes the implicit [0] and maximum [1] speed limit for urban areas in the current country for the current vehicle. 0 - No speed limit or speed limit unknown";
CM_ SG_ 2600454915 conMapSpdLimSC_BASE "This signal describes the implicit speed limit for single carriageways in the current country for the current vehicle. 0 - No speed limit or speed limit unknown";
CM_ BO_ 2600454923 "CANMSG auxStatCM14";
CM_ SG_ 2600454923 auxStatCM14placeholder_BASE "Placeholder signal";
CM_ BO_ 2600454916 "CANMSG auxStatCM7";
CM_ SG_ 2600454916 updtMstrUpdateStatus_BASE "Update status of Update Master shown to the driver";
CM_ SG_ 2600454916 updtMstrDispSupCheckbox_BASE "Signal indicates if the checkbox with the option of suppressing update notifcations should be displayed.";
CM_ SG_ 2600454916 updtMstrUpdateTypeInfo_BASE "Type of update information shown to the driver";
CM_ SG_ 2600454916 updtMstrDrvrNotifStatus_BASE "Signal contains the driver's decision to suppress or not suppress update notifications.";
CM_ BO_ 2351336021 "Primary Control Message from this instance of Inverter. Some examples of use would be for a hybrid or electric vehicle propulsion motor or generator. msg id 0x002600A55";
CM_ SG_ 2351336021 msgCRC8saeJ1939_BASE "CRC8 SAE J1939";
CM_ SG_ 2351336021 MG1ICLimReqOCM_BASE "This parameter provides a way to temporarily override limits that are being received by the inverter in other messages. It allows a specific type of limit to be transmitted at a high rate or at the same moment as the set point for synchronization purposes";
CM_ SG_ 2351336021 MG1ICmaxLimReq_BASE "The Maximum limit requested";
CM_ SG_ 2351336021 MG1ICminLimReq_BASE "The Minimum limit requested";
CM_ SG_ 2351336021 MG1ICsetpointModeReq_BASE "Requests the modes for this instance of the inverter.";
CM_ SG_ 2351336021 MG1ICsetpointReq_BASE "Requests the set point for this inverter.";
CM_ SG_ 2351336021 msgCNTsaeJ1939_BASE "The message counter is used to detect situations where the transmitting ECU malfunction repeats the same frame all the time. The receiver of the information may use the counter parameter to detect this situation. The transmitting device will increase the ";
CM_ BO_ 2364638805 "Motor/Generator 2 Inverter Mode Feedback 1";
CM_ SG_ 2364638805 msgCRC8saeJ1939_BASE "CRC8 SAE J1939";
CM_ SG_ 2364638805 MG2IMF1setpointMode_BASE "Reports the inverter mode";
CM_ SG_ 2364638805 msgCNTsaeJ1939_BASE "The message counter is used to detect situations where the transmitting ECU malfunction repeats the same frame all the time. The receiver of the information may use the counter parameter to detect this situation. The transmitting device will increase the ";
CM_ BO_ 2365287765 "Motor/Generator 2 Inverter Status 1 Msg ID 00FB6D55";
CM_ SG_ 2365287765 msgCRC8saeJ1939_BASE "CRC8 SAE J1939";
CM_ SG_ 2365287765 actMotorTrqPrcnt_BASE "The measured or estimated motor torque";
CM_ SG_ 2365287765 actMotorSpeedPrcnt_BASE "current motor speed of the drive inverter with percentage reference to the reference speed";
CM_ SG_ 2365287765 msgCNTsaeJ1939_BASE "The message counter is used to detect situations where the transmitting ECU malfunction repeats the same frame all the time. The receiver of the information may use the counter parameter to detect this situation. The transmitting device will increase the ";
CM_ SG_ 2562139997 hubVidInp1ConnectStatus_BASE "Camera connection Status of Camera Hub Video Input 1";
CM_ SG_ 2562139997 cameraHubTriggerPin3req_BASE "Camera Hub Pin Input Trigger via physical pin (which can be wired by the customer) to activate the camera on Video Input Port 3.";
CM_ SG_ 2562139997 cameraHubTriggerPin4req_BASE "Camera Hub Pin Input Trigger via physical pin (which can be wired by the customer) to activate the camera on Video Input Port 4.";
CM_ SG_ 2562139997 cameraHubVidChnnlState_BASE "Camera Hub signal which indicates which video stream is routed to the video output currently.";
CM_ SG_ 2562139997 hubVidInp2ConnectStatus_BASE "Camera connection Status of Camera Hub Video Input 1";
CM_ SG_ 2562139997 hubVidInp3ConnectStatus_BASE "Camera connection Status of Camera Hub Video Input 1";
CM_ SG_ 2562139997 hubVidInp4ConnectStatus_BASE "Camera connection Status of Camera Hub Video Input 1";
CM_ BO_ 2566799505 "Lighting Data message used also for commands to vehicle, same layout as lightingCommand. Name will stay lighting command.";
CM_ SG_ 2566799505 rotatingBeaconLightCmd_BASE "Command to activate or de-activate slow moving vehicle indicator lights on tractor and/or implements. Activation of the slow moving vehicle lights implies that the controller should manipulate the lighting as appropriate to provide the slow moving vehicle";
CM_ SG_ 2566799505 centerStopLightCmd_BASE "Command to activate or de-activate the tractor and implement center stop light";
CM_ SG_ 2566799505 tractorMarkerLightCmd_BASE "Command to activate or de-activate tractor and implement front position lights, rear red tail lights, side amber running lights, license plate lights and instrument and switch back lights.";
CM_ SG_ 2566799505 rearFogLightCmd_BASE "Command to activate or de-activate tractor or implement rear fog lights.";
CM_ SG_ 2566799505 lowBeamHLReq_BASE "Command to activate or de-activate the tractor low beam head light lamps.";
CM_ SG_ 2566799505 implOEMOption1lightCmd_BASE "Command to activate or de-activate an implement OEM option 1 light. This is provided to meet special needs on implements, such as tank inspection or filling lights.";
CM_ SG_ 2566799505 implementRightFwdWorkLightCmd_BA "Command to activate or de-activate the forward facing work lights toward the right end of the implement.";
CM_ SG_ 2566799505 implementRearWorkLightCmd_BASE "Command to activate or de-activate implement rear work lights. (This is also the same as Reversing Lights for truck applications.)";
CM_ BO_ 2566799445 "Lighting Data message used also for commands to vehicle, same layout as lightingCommand. Name will stay lighting command.";
CM_ SG_ 2566799445 rotatingBeaconLightCmd_BASE "Command to activate or de-activate slow moving vehicle indicator lights on tractor and/or implements. Activation of the slow moving vehicle lights implies that the controller should manipulate the lighting as appropriate to provide the slow moving vehicle";
CM_ SG_ 2566799445 centerStopLightCmd_BASE "Command to activate or de-activate the tractor and implement center stop light";
CM_ SG_ 2566799445 tractorMarkerLightCmd_BASE "Command to activate or de-activate tractor and implement front position lights, rear red tail lights, side amber running lights, license plate lights and instrument and switch back lights.";
CM_ SG_ 2566799445 rearFogLightCmd_BASE "Command to activate or de-activate tractor or implement rear fog lights.";
CM_ SG_ 2566799445 lowBeamHLReq_BASE "Command to activate or de-activate the tractor low beam head light lamps.";
CM_ SG_ 2566799445 implOEMOption1lightCmd_BASE "Command to activate or de-activate an implement OEM option 1 light. This is provided to meet special needs on implements, such as tank inspection or filling lights.";
CM_ SG_ 2566799445 implementRightFwdWorkLightCmd_BA "Command to activate or de-activate the forward facing work lights toward the right end of the implement.";
CM_ SG_ 2566799445 implementRearWorkLightCmd_BASE "Command to activate or de-activate implement rear work lights. (This is also the same as Reversing Lights for truck applications.)";
CM_ BO_ 2566799504 "Lighting Data message used also for commands to vehicle, same layout as lightingCommand. Name will stay lighting command.";
CM_ SG_ 2566799504 rotatingBeaconLightCmd_BASE "Command to activate or de-activate slow moving vehicle indicator lights on tractor and/or implements. Activation of the slow moving vehicle lights implies that the controller should manipulate the lighting as appropriate to provide the slow moving vehicle";
CM_ SG_ 2566799504 centerStopLightCmd_BASE "Command to activate or de-activate the tractor and implement center stop light";
CM_ SG_ 2566799504 tractorMarkerLightCmd_BASE "Command to activate or de-activate tractor and implement front position lights, rear red tail lights, side amber running lights, license plate lights and instrument and switch back lights.";
CM_ SG_ 2566799504 rearFogLightCmd_BASE "Command to activate or de-activate tractor or implement rear fog lights.";
CM_ SG_ 2566799504 lowBeamHLReq_BASE "Command to activate or de-activate the tractor low beam head light lamps.";
CM_ SG_ 2566799504 implOEMOption1lightCmd_BASE "Command to activate or de-activate an implement OEM option 1 light. This is provided to meet special needs on implements, such as tank inspection or filling lights.";
CM_ SG_ 2566799504 implementRightFwdWorkLightCmd_BA "Command to activate or de-activate the forward facing work lights toward the right end of the implement.";
CM_ SG_ 2566799504 implementRearWorkLightCmd_BASE "Command to activate or de-activate implement rear work lights. (This is also the same as Reversing Lights for truck applications.)";
CM_ BO_ 2566799760 "Lighting Data message used also for commands to vehicle";
CM_ SG_ 2566799760 rotatingBeaconLightCmd_BASE "Command to activate or de-activate slow moving vehicle indicator lights on tractor and/or implements. Activation of the slow moving vehicle lights implies that the controller should manipulate the lighting as appropriate to provide the slow moving vehicle";
CM_ SG_ 2566799760 centerStopLightCmd_BASE "Command to activate or de-activate the tractor and implement center stop light";
CM_ SG_ 2566799760 tractorMarkerLightCmd_BASE "Command to activate or de-activate tractor and implement front position lights, rear red tail lights, side amber running lights, license plate lights and instrument and switch back lights.";
CM_ SG_ 2566799760 rearFogLightCmd_BASE "Command to activate or de-activate tractor or implement rear fog lights.";
CM_ SG_ 2566799760 lowBeamHLReq_BASE "Command to activate or de-activate the tractor low beam head light lamps.";
CM_ SG_ 2566799760 implOEMOption1lightCmd_BASE "Command to activate or de-activate an implement OEM option 1 light. This is provided to meet special needs on implements, such as tank inspection or filling lights.";
CM_ SG_ 2566799760 implementRightFwdWorkLightCmd_BA "Command to activate or de-activate the forward facing work lights toward the right end of the implement.";
CM_ SG_ 2566799760 implementRearWorkLightCmd_BASE "Command to activate or de-activate implement rear work lights. (This is also the same as Reversing Lights for truck applications.)";
CM_ BO_ 2566799761 "Lighting Data message used also for commands to vehicle";
CM_ SG_ 2566799761 rotatingBeaconLightCmd_BASE "Command to activate or de-activate slow moving vehicle indicator lights on tractor and/or implements. Activation of the slow moving vehicle lights implies that the controller should manipulate the lighting as appropriate to provide the slow moving vehicle";
CM_ SG_ 2566799761 centerStopLightCmd_BASE "Command to activate or de-activate the tractor and implement center stop light";
CM_ SG_ 2566799761 tractorMarkerLightCmd_BASE "Command to activate or de-activate tractor and implement front position lights, rear red tail lights, side amber running lights, license plate lights and instrument and switch back lights.";
CM_ SG_ 2566799761 rearFogLightCmd_BASE "Command to activate or de-activate tractor or implement rear fog lights.";
CM_ SG_ 2566799761 lowBeamHLReq_BASE "Command to activate or de-activate the tractor low beam head light lamps.";
CM_ SG_ 2566799761 implOEMOption1lightCmd_BASE "Command to activate or de-activate an implement OEM option 1 light. This is provided to meet special needs on implements, such as tank inspection or filling lights.";
CM_ SG_ 2566799761 implementRightFwdWorkLightCmd_BA "Command to activate or de-activate the forward facing work lights toward the right end of the implement.";
CM_ SG_ 2566799761 implementRearWorkLightCmd_BASE "Command to activate or de-activate implement rear work lights. (This is also the same as Reversing Lights for truck applications.)";
CM_ BO_ 2566799701 "Lighting Data message used also for commands to vehicle";
CM_ SG_ 2566799701 rotatingBeaconLightCmd_BASE "Command to activate or de-activate slow moving vehicle indicator lights on tractor and/or implements. Activation of the slow moving vehicle lights implies that the controller should manipulate the lighting as appropriate to provide the slow moving vehicle";
CM_ SG_ 2566799701 centerStopLightCmd_BASE "Command to activate or de-activate the tractor and implement center stop light";
CM_ SG_ 2566799701 tractorMarkerLightCmd_BASE "Command to activate or de-activate tractor and implement front position lights, rear red tail lights, side amber running lights, license plate lights and instrument and switch back lights.";
CM_ SG_ 2566799701 rearFogLightCmd_BASE "Command to activate or de-activate tractor or implement rear fog lights.";
CM_ SG_ 2566799701 lowBeamHLReq_BASE "Command to activate or de-activate the tractor low beam head light lamps.";
CM_ SG_ 2566799701 implOEMOption1lightCmd_BASE "Command to activate or de-activate an implement OEM option 1 light. This is provided to meet special needs on implements, such as tank inspection or filling lights.";
CM_ SG_ 2566799701 implementRightFwdWorkLightCmd_BA "Command to activate or de-activate the forward facing work lights toward the right end of the implement.";
CM_ SG_ 2566799701 implementRearWorkLightCmd_BASE "Command to activate or de-activate implement rear work lights. (This is also the same as Reversing Lights for truck applications.)";
CM_ BO_ 2566897493 "body builder configurable logic CAN input Data ID No: 446; Data ID : 58 83 138 100 90 137 23 183 193 154 158 104 160 189 228 136;";
CM_ SG_ 2566897493 ASP2_CRC8_BASE "CRC8 Autosar Profile 2 with Data ID";
CM_ SG_ 2566897493 genericBobuIn101_BASE "Generic Input Signal via CAN - bool";
CM_ SG_ 2566897493 genericBobuIn102_BASE "Generic Input Signal via CAN - bool";
CM_ SG_ 2566897493 genericBobuIn103_BASE "Generic Input Signal via CAN - bool";
CM_ SG_ 2566897493 genericBobuIn104_BASE "Generic Input Signal via CAN - bool";
CM_ SG_ 2566897493 genericBobuIn105_BASE "Generic Input Signal via CAN - bool";
CM_ SG_ 2566897493 genericBobuIn106_BASE "Generic Input Signal via CAN - bool";
CM_ SG_ 2566897493 genericBobuIn201_BASE "Generic Input Signal via CAN - 8bit";
CM_ SG_ 2566897493 genericBobuIn202_BASE "Generic Input Signal via CAN - 8bit";
CM_ SG_ 2566897493 genericBobuIn203_BASE "Generic Input Signal via CAN - 8bit";
CM_ SG_ 2566897493 genericBobuIn301_BASE "Generic Input Signal via CAN - 16bit";
CM_ SG_ 2566897493 ASP2__cnt_BASE "Cnt Autosar Profile 2";
CM_ SG_ 2566897237 extCoolTempSetpointReq_BASE "external Request of Setpoint for the coolant temperature";
CM_ SG_ 2566897237 bobuAudioMute_BASE "external audio mute request";
CM_ SG_ 2566897237 bobuRecircModeReq_BASE "external request for HVAC recirculation";
CM_ SG_ 2566897237 lockCruisRange_BASE "lock eval driving range";
CM_ SG_ 2566897237 bobuSignalHornExtInhReq_BASE "external signal horn inhibit request";
CM_ SG_ 2566759568 PTODEmsgCounter_BASE "The message checksum is used to verify the signal path from the transmitting device to the receiving device.";
CM_ SG_ 2566759568 PTODEchkSum_BASE "Checksum according TSC1 The message counter is used to detect situations where the transmitting ECU malfunction repeats the same frame all the time. The receiver of the information may use the counter parameter to detect this situation. The transmitting d";
CM_ SG_ 2566759569 PTODEmsgCounter_BASE "The message checksum is used to verify the signal path from the transmitting device to the receiving device.";
CM_ SG_ 2566759569 PTODEchkSum_BASE "Checksum according TSC1 The message counter is used to detect situations where the transmitting ECU malfunction repeats the same frame all the time. The receiver of the information may use the counter parameter to detect this situation. The transmitting d";
CM_ BO_ 2600454917 "D-CAN CANMSG auxStatCM8";
CM_ SG_ 2600454917 extrnlChrgPmaxOTAreq_BASE "Maximum charge power allowed by the OTA backend.";
CM_ SG_ 2600454917 extrnlChrgOTAbooked_BASE "Booking state of OTA control (eManager) provided by OTA backend.";
CM_ SG_ 2600454917 cntrctCertChrgI1OTAreq_BASE "The signal indicates the selected contract certificate for charging interface 1 requested by the OTA backend.";
CM_ SG_ 2600454917 cntrctCertChrgI2OTAreq_BASE "The signal indicates the selected contract certificate for charging interface 2 requested by the OTA backend.";
CM_ SG_ 2600454917 extrnlChrgHVACstrgyOTAreq_BASE "The signal indicates the HVAC preconditioning strategy during external charging requested by the OTA backend.";
CM_ SG_ 2600454917 extrnlChrgHldInfOTAreq_BASE "The signal indicates if the holding period shall be infinite, requested by the OTA backend.";
CM_ SG_ 2600454917 extrnlChrgPnCslctdOTAreq_BASE "The signal indicates if Plug and Charge for external charging is requested by the OTA backend.";
CM_ SG_ 2600454917 extrnlChrgAMS_OTAreq_BASE "Request for AMS preconditioning by the OTA-Backend.";
CM_ SG_ 2600454917 extrnlChrgFastChrgOTAreq_BASE "The signal indicates if fast charging is requested from the OTA interface (e-manager).";
CM_ SG_ 2600454917 extrnlChrgOTActrlOTAreq_BASE "Enables control of the charging settings via OTA (over the air) requested from OTA (eManager).";
CM_ SG_ 2600454917 extrnlChrgSelPrcTypOTAreq_BASE "The signal indicates the selected pricing type for the running/upcoming charging session requested by the OTA backend.";
CM_ SG_ 2600454917 extrnlChrgHVACheatLvOTAreq_BASE "The signal indicates the heating level for the HVAC preconditioning during external charging requested by the OTA backend.";
CM_ SG_ 2600454917 extrnlChrgBulkSOC_OTAreq_BASE "The signal indicates the bulk SOC requested by the OTA Backend.";
CM_ SG_ 2600454917 extrnlChrgHVACtempOTAreq_BASE "The signal indicates the temperature for the HVAC preconditioning during external charging requested by the OTA backend.";
CM_ BO_ 2600454920 "CANMSG auxStatCM11";
CM_ SG_ 2600454920 mapVersion_BASE "array of uint8 asci value";
CM_ SG_ 2566759509 PTODEmsgCounter_BASE "The message checksum is used to verify the signal path from the transmitting device to the receiving device.";
CM_ SG_ 2566759509 PTODEchkSum_BASE "Checksum according TSC1 The message counter is used to detect situations where the transmitting ECU malfunction repeats the same frame all the time. The receiver of the information may use the counter parameter to detect this situation. The transmitting d";
CM_ BO_ 2348820369 "Torque/Speed Control 1  from the gear box to control the engine torque/speed.  SAE Content: NOTE - Retarder may be disabled by commanding a torque limit of 0%. Use of the limit mode allows the use of the retarder only up to the limit specified in the requ";
CM_ SG_ 2348820369 engineOverrideControlMode_TCU2EN "The override control mode defines which sort of command is used.";
CM_ SG_ 2348820369 engineReqSpeedControlConditions_ "This mode tells the engine control system the governor characteristics that are desired during speed control. 3 not used";
CM_ SG_ 2348820369 engineReqTorqueTorqueLimit_TCU2E "engineReqTorqueTorqueLimit; Parameter provided to the engine or retarder in the torque/speed control message for controlling or limiting the output torque. Requested torque to the engine is measured in indicated torque as a percentage of reference engine ";
CM_ SG_ 2348820369 overrideControlModePriority_TCU2 "This field is used as an input to the engine or retarder to determine the priority of the Override Control Mode received in the Torque/Speed Control message (see PGN 0). The default is 11 (Low priority). It is not required to use the same priority during ";
CM_ SG_ 2348820369 TSC1messageCounterTCU2ENG_BASE "The message counter is used to detect situations where the transmitting ECU malfunction repeats the same frame all the time. The receiver of the information may use the counter parameter to detect this situation. The transmitting device will increase the ";
CM_ SG_ 2348820369 TSC1messageChecksumTCU2ENG_BASE "The message checksum is used to verify the signal path from the transmitting device to the receiving device.";
CM_ SG_ 2348820369 engineReqSpeedSpeedLimit_TCU2ENG "engineReqSpeedSpeedLimit; Parameter provided to the engine from external sources in the torque/speed control message. This is the engine speed which the engine is expected to operate at if the speed control mode is active or the engine speed which the eng";
CM_ BO_ 2348820368 "Torque/Speed Control 1  from the gear box to control the engine torque/speed.  SAE Content: NOTE - Retarder may be disabled by commanding a torque limit of 0%. Use of the limit mode allows the use of the retarder only up to the limit specified in the requ";
CM_ SG_ 2348820368 engineOverrideControlMode_TCU2EN "The override control mode defines which sort of command is used.";
CM_ SG_ 2348820368 engineReqSpeedControlConditions_ "This mode tells the engine control system the governor characteristics that are desired during speed control. 3 not used";
CM_ SG_ 2348820368 engineReqTorqueTorqueLimit_TCU2E "engineReqTorqueTorqueLimit; Parameter provided to the engine or retarder in the torque/speed control message for controlling or limiting the output torque. Requested torque to the engine is measured in indicated torque as a percentage of reference engine ";
CM_ SG_ 2348820368 overrideControlModePriority_TCU2 "This field is used as an input to the engine or retarder to determine the priority of the Override Control Mode received in the Torque/Speed Control message (see PGN 0). The default is 11 (Low priority). It is not required to use the same priority during ";
CM_ SG_ 2348820368 TSC1messageCounterTCU2ENG_BASE "The message counter is used to detect situations where the transmitting ECU malfunction repeats the same frame all the time. The receiver of the information may use the counter parameter to detect this situation. The transmitting device will increase the ";
CM_ SG_ 2348820368 TSC1messageChecksumTCU2ENG_BASE "The message checksum is used to verify the signal path from the transmitting device to the receiving device.";
CM_ SG_ 2348820368 engineReqSpeedSpeedLimit_TCU2ENG "engineReqSpeedSpeedLimit; Parameter provided to the engine from external sources in the torque/speed control message. This is the engine speed which the engine is expected to operate at if the speed control mode is active or the engine speed which the eng";
CM_ BO_ 2348820309 "Torque/Speed Control 1  from the gear box to control the engine torque/speed.  SAE Content: NOTE - Retarder may be disabled by commanding a torque limit of 0%. Use of the limit mode allows the use of the retarder only up to the limit specified in the requ";
CM_ SG_ 2348820309 engineOverrideControlMode_TCU2EN "The override control mode defines which sort of command is used.";
CM_ SG_ 2348820309 engineReqSpeedControlConditions_ "This mode tells the engine control system the governor characteristics that are desired during speed control. 3 not used";
CM_ SG_ 2348820309 engineReqTorqueTorqueLimit_TCU2E "engineReqTorqueTorqueLimit; Parameter provided to the engine or retarder in the torque/speed control message for controlling or limiting the output torque. Requested torque to the engine is measured in indicated torque as a percentage of reference engine ";
CM_ SG_ 2348820309 overrideControlModePriority_TCU2 "This field is used as an input to the engine or retarder to determine the priority of the Override Control Mode received in the Torque/Speed Control message (see PGN 0). The default is 11 (Low priority). It is not required to use the same priority during ";
CM_ SG_ 2348820309 TSC1messageCounterTCU2ENG_BASE "The message counter is used to detect situations where the transmitting ECU malfunction repeats the same frame all the time. The receiver of the information may use the counter parameter to detect this situation. The transmitting device will increase the ";
CM_ SG_ 2348820309 TSC1messageChecksumTCU2ENG_BASE "The message checksum is used to verify the signal path from the transmitting device to the receiving device.";
CM_ SG_ 2348820309 engineReqSpeedSpeedLimit_TCU2ENG "engineReqSpeedSpeedLimit; Parameter provided to the engine from external sources in the torque/speed control message. This is the engine speed which the engine is expected to operate at if the speed control mode is active or the engine speed which the eng";
CM_ SG_ 2600418645 EPB2messageCounter_BASE "Message counter for EPB2 used to verify the signal path.";
CM_ SG_ 2600418645 EPB2messageChecksum_BASE "Message checksum EPB2 used to verify the signal path. Checksum = (Byte1 + Byte2 + Byte3 + Byte4 + Byte5 + Byte6 + Byte7 + message counter&0x0F + message ID low byte + message ID mid low byte + message ID mid high byte + message ID high byte) Message Check";
CM_ SG_ 2600466261 leftTurnSignalLightsCmd_BASE "Command to activate or de-activate left turn signal lights on the tractor and all connected implements";
CM_ SG_ 2600466261 rightTurnSignalLightsCmd_BASE "Command to activate or de-activate right turn signal lights on the tractor and all connected implements";
CM_ SG_ 2600466261 extAccelDemReqBB2_BASE "This signal indicates that a braking request from the bodybuilder2 is desired.";
CM_ SG_ 2600466261 extBrakeDemBB2_BASE "External BodyBuilder2 acceleration specification that the braking system must implement.";
CM_ SG_ 2600466261 KSM3chkE2E_BASE "checksum of end-to-end communication protection";
CM_ BO_ 2566894737 "body builder control 3 message; Data ID No: 451;  Data ID: 30 219 125 231 176 196 144 161 192 78 200 215 178 47 22 148 ";
CM_ SG_ 2566894737 ASP2_CRC8_BASE "CRC8 Autosar Profile 2 with Data ID";
CM_ SG_ 2566894737 bobuLiftAxle1posCmd_BASE "External signal to command the position of lift axle #1. Numbering of lift axles starts at front axle.";
CM_ SG_ 2566894737 bobuLiftAxle2posCmd_BASE "External signal to command the position of lift axle #2. Numbering of lift axles starts at front axle.";
CM_ SG_ 2566894737 bobuLvlCtrlModeRequest_BASE "Body Builder Chassis Level Control Mode Request";
CM_ SG_ 2566894737 bobuNomLvlReqRA_BASE "Command signal to activate a level of the rear axle programmed and/or memorised in the ECU. For explanations of nominal level see SPN 1734 - Nominal Level Front Axle.";
CM_ SG_ 2566894737 bobuNomLvlReqFA_BASE "Command signal to activate a level of the front axle programmed and/or memorised in the ECU. For explanations of nominal level see SPN 1734 - Nominal Level Front Axle.";
CM_ SG_ 2566894737 bobuProhibitAutoASC_BASE "This parameter is an internal request to the air suspension control system to prohibit automatic air suspension control. If the request is accepted, response intended to be sent in ASC1 (additional status requested in ASC1), there will be no automatic con";
CM_ SG_ 2566894737 ASP2__cnt_BASE "Cnt Autosar Profile 2";
CM_ BO_ 2566894677 "body builder control 3 message; Data ID No: 429;  Data ID: 210 106 74 176 159 205 101 78 180 224 76 22 55 28 232 34 ";
CM_ SG_ 2566894677 ASP2_CRC8_BASE "CRC8 Autosar Profile 2 with Data ID";
CM_ SG_ 2566894677 bobuLiftAxle1posCmd_BASE "External signal to command the position of lift axle #1. Numbering of lift axles starts at front axle.";
CM_ SG_ 2566894677 bobuLiftAxle2posCmd_BASE "External signal to command the position of lift axle #2. Numbering of lift axles starts at front axle.";
CM_ SG_ 2566894677 bobuLvlCtrlModeRequest_BASE "Body Builder Chassis Level Control Mode Request";
CM_ SG_ 2566894677 bobuNomLvlReqRA_BASE "Command signal to activate a level of the rear axle programmed and/or memorised in the ECU. For explanations of nominal level see SPN 1734 - Nominal Level Front Axle.";
CM_ SG_ 2566894677 bobuNomLvlReqFA_BASE "Command signal to activate a level of the front axle programmed and/or memorised in the ECU. For explanations of nominal level see SPN 1734 - Nominal Level Front Axle.";
CM_ SG_ 2566894677 bobuProhibitAutoASC_BASE "This parameter is an internal request to the air suspension control system to prohibit automatic air suspension control. If the request is accepted, response intended to be sent in ASC1 (additional status requested in ASC1), there will be no automatic con";
CM_ SG_ 2566894677 ASP2__cnt_BASE "Cnt Autosar Profile 2";
CM_ BO_ 2566894736 "body builder control 3 message; Data ID No: 449;  Data ID: 153 11 213 198 241 63 155 16 189 135 117 247 109 66 85 197 ";
CM_ SG_ 2566894736 ASP2_CRC8_BASE "CRC8 Autosar Profile 2 with Data ID";
CM_ SG_ 2566894736 bobuLiftAxle1posCmd_BASE "External signal to command the position of lift axle #1. Numbering of lift axles starts at front axle.";
CM_ SG_ 2566894736 bobuLiftAxle2posCmd_BASE "External signal to command the position of lift axle #2. Numbering of lift axles starts at front axle.";
CM_ SG_ 2566894736 bobuLvlCtrlModeRequest_BASE "Body Builder Chassis Level Control Mode Request";
CM_ SG_ 2566894736 bobuNomLvlReqRA_BASE "Command signal to activate a level of the rear axle programmed and/or memorised in the ECU. For explanations of nominal level see SPN 1734 - Nominal Level Front Axle.";
CM_ SG_ 2566894736 bobuNomLvlReqFA_BASE "Command signal to activate a level of the front axle programmed and/or memorised in the ECU. For explanations of nominal level see SPN 1734 - Nominal Level Front Axle.";
CM_ SG_ 2566894736 bobuProhibitAutoASC_BASE "This parameter is an internal request to the air suspension control system to prohibit automatic air suspension control. If the request is accepted, response intended to be sent in ASC1 (additional status requested in ASC1), there will be no automatic con";
CM_ SG_ 2566894736 ASP2__cnt_BASE "Cnt Autosar Profile 2";
CM_ BO_ 2600454921 "CANMSG auxStatCM12";
CM_ SG_ 2600454921 conMapMaxSpdLimMotorway_BASE "This signal describes the explicit (max) [0] speed limit for motorways in the current country for the current vehicle. 0 - No speed limit or speed limit unknown";
CM_ SG_ 2600454921 conMapMaxSpdLimSC_BASE "This signal describes the explicit (max) speed limit for single carriageways in the current country for the current vehicle. 0 - No speed limit or speed limit unknown";
CM_ SG_ 2600454921 conMapMaxSpdLimRural_BASE "This signal describes the explicit (max) speed limit for rural roads in the current country for the current vehicle. 0 - No speed limit or speed limit unknown";
CM_ SG_ 2600454921 conMapMaxSpdLimUrban_BASE "This signal describes the explicit (max) [0] and maximum [1] speed limit for urban areas in the current country for the current vehicle. 0 - No speed limit or speed limit unknown";
CM_ SG_ 2600454921 conMapMaxSpdLimPlayStreet_BASE "This signal describes the explicit (max) speed limit for playstreets (i.e. home zones) in the current country for the current vehicle. 0 - No speed limit or speed limit unknown";
CM_ SG_ 2600454921 conMapMaxSpdLimDC_BASE "This signal describes the explicit (max) speed limit for dual carriageways in the current country for the current vehicle. 0 - No speed limit or speed limit unknown";
CM_ SG_ 2667525634 driveProgramAppVersion_BASE "version CAN raw value 14: error CAN raw value 15: not available";
CM_ SG_ 2667525634 appValSlider1Req_BASE "App Slider1 Value Request";
CM_ SG_ 2667525634 appValSwitch4Req_BASE "App Switch4 Value Request";
CM_ SG_ 2667525634 appValSwitch5Req_BASE "App Switch5 Value Request";
CM_ SG_ 2667525634 appValSwitch2Req_BASE "App Switch2 Value Request";
CM_ SG_ 2667525634 appValSwitch1Req_BASE "App Switch1 Value Request";
CM_ SG_ 2667525634 appValSwitch3Req_BASE "App Switch3 Value Request";
CM_ SG_ 2667525634 appValSlider4Req_BASE "App Slider4 Value Request";
CM_ SG_ 2667525634 appValSlider5Req_BASE "App Slider5 Value Request";
CM_ SG_ 2667525634 appValSlider6Req_BASE "App Slider6 Value Request";
CM_ SG_ 2667525634 appValSlider2Req_BASE "App Slider2 Value Request";
CM_ SG_ 2667525634 appValSlider3Req_BASE "App Slider3 Value Request";
CM_ BO_ 2600454912 "CANMSG auxStatCM4";
CM_ SG_ 2600454912 chllngngEnvrnmntDet_BASE "This signal indicates whether a challenging environment is detected or not.";
CM_ BO_ 2600415573 "Generic Display Signals from Body Builder.";
CM_ SG_ 2600415573 BBDchkE2E_BASE "checksum of end-to-end communication protection";
CM_ BO_ 2600415632 "Generic Display Signals from Body Builder.";
CM_ SG_ 2600415632 BBDchkE2E_BASE "checksum of end-to-end communication protection";
CM_ BO_ 2600415633 "Generic Display Signals from Body Builder.";
CM_ SG_ 2600415633 BBDchkE2E_BASE "checksum of end-to-end communication protection";
CM_ BO_ 2600454925 "CANMSG auxStatCM16";
CM_ SG_ 2600454925 auxStatCM16placeholder_BASE "Placeholder signal";
CM_ BO_ 2600454924 "CANMSG auxStatCM15";
CM_ SG_ 2600454924 auxStatCM15placeholder_BASE "Placeholder signal";
CM_ BO_ 2600454927 "CANMSG auxStatCM18";
CM_ SG_ 2600454927 auxStatCM18placeholder_BASE "Placeholder signal";
CM_ BO_ 2600454928 "CANMSG auxStatCM19";
CM_ SG_ 2600454928 auxStatCM19placeholder_BASE "Placeholder signal";
CM_ BO_ 2600454929 "CANMSG auxStatCM20";
CM_ SG_ 2600454929 auxStatCM20placeholder_BASE "Placeholder signal";
CM_ BO_ 2600454926 "CANMSG auxStatCM17";
CM_ SG_ 2600454926 auxStatCM17placeholder_BASE "Placeholder signal";
CM_ BO_ 2600454931 "CANMSG auxStatCM22";
CM_ SG_ 2600454931 auxStatCM22placeholder_BASE "Placeholder signal";
CM_ BO_ 2600454930 "CANMSG auxStatCM21";
CM_ SG_ 2600454930 auxStatCM21placeholder_BASE "Placeholder signal";
CM_ BO_ 2600454918 "CANMSG auxStatCM9";
CM_ SG_ 2600454918 vehDepartTimeOTAreq_BASE "Duration until the next departure time requested by the backend.";
CM_ SG_ 2600454918 extrnlChrgModeOTAreq_BASE "Requested charging mode from OTA-Backend.";
CM_ SG_ 2600454918 extrnlChrgPreCondOTAreq_BASE "Request for HVAC conditioning from OTA-Backend.";
CM_ SG_ 2600454918 extrnlChrgAllwdOTAreq_BASE "Permission from OTA-Backend for external charging.";
CM_ SG_ 2600454918 extrnlChrgTargetSOcOTAreq_BASE "Requested charge state of the TES (traction energy accumulator) from OTA-Backend";
CM_ SG_ 2600454918 vehSbyDurationOTAreq_BASE "Requested time for which the vehicle must be kept ready for operation after the planned departure time has passed and the vehicle has not driven out.";
CM_ BO_ 2600454913 "CANMSG auxStatCM5 Data ID: 199 87 92 32 116 55 170 249 239 155 191 250 138 60 146 120";
CM_ SG_ 2600454913 auxStatCM5_CRC_BASE "Message checksum used to verify the signal path. The algorithm is according to CRC8 Autosar Profile 2 with Data ID";
CM_ SG_ 2600454913 SRPACCdistLvl_BASE "Remote control EfficientCruise ACC distance level";
CM_ SG_ 2600454913 SRPmaxSagSpd_BASE "highest sag speed";
CM_ SG_ 2600454913 SRPmaxSpdIndexPCCA_BASE "srp requested PCCA max speed level for sag overspeed";
CM_ SG_ 2600454913 SRPminSumSpd_BASE "lowest speed for vehicle on a summit";
CM_ SG_ 2600454913 SRPreqVehSpdCC_BASE "SRP desired speed of the CruiseControl functions (FGR, ACC)";
CM_ SG_ 2600454913 SRPecoLevel_BASE "ECO Level from a remote interface which can be an intelligent function";
CM_ SG_ 2600454913 SRPchangeType_BASE "change of setting immediate or in PCCA sitiuation";
CM_ SG_ 2600454913 auxStatCM5_Cnt_BASE "Counter of end-to-end communication protection.";
CM_ BO_ 2600454914 "CANMSG auxStatCM3";
CM_ SG_ 2600454914 wasteEnergyModeDurSRP_BASE "This signal indicates the duration the waste energy mode shall be active recommended by Smart Route Planning (SRP).";
CM_ SG_ 2600454914 SRPsegmentID_BASE "SRP segment ID of JSON segment";
CM_ SG_ 2600454914 SRPdrivingProg_BASE "Demanded SRP driving program";
CM_ SG_ 2600454914 wasteEnergyModeActSRP_BASE "This signal indicates if the Smart Route Planning Optimiser triggers the wasteEnergyMode.";
CM_ SG_ 2600454914 predEnrgyToNextCS_BASE "Predicted energy consumption to reach next planned charging station.";
CM_ SG_ 2600454914 predDistToNextCS_BASE "Predicted distance to next planned charging station.";
CM_ SG_ 2600454914 SRPspeedLimit_BASE "SRP variable high speed governour speed limit";

BA_DEF_ BU_  "TpOwnSystemEcuNumber" HEX 0 255;
BA_DEF_ SG_  "SigType" ENUM  "DEFAULT","RANGE","RANGESIGNED","ASCII","DISCRETE","CONTROL","REFERENCEPGN","DTC","STRINGDELIMITER","STRINGLENGTH","STRINGLENGTHCONTROL","vector_leerstring";
BA_DEF_ SG_  "GenSigSendType" ENUM  "Cyclic","OnWrite","reserved","OnChange","reserved","reserved","reserved","NoSigSendType";
BA_DEF_ BO_  "VFrameFormat" ENUM  "CAN Standard","CAN Extended","reserved","J1939PG","reserved","reserved","reserved","reserved","reserved","reserved","reserved","reserved","reserved","reserved","StandardCAN_FD","ExtendedCAN_FD","vector_leerstring";
BA_DEF_ BO_  "GenMsgSendType" ENUM  "cyclic","reserved","cyclicIfActive","reserved","reserved","reserved","reserved","reserved","noMsgSendType","vector_leerstring";
BA_DEF_ BO_  "GenMsgCycleTime" INT 0 3600000;
BA_DEF_ BO_  "GenMsgStartDelayTime" INT 0 0;
BA_DEF_ BU_  "ECU" STRING ;
BA_DEF_ BU_  "NmStationAddress" INT 0 0;
BA_DEF_ BO_  "GenMsgILSupport" ENUM  "No","Yes","vector_leerstring";
BA_DEF_ BU_  "ILUsed" ENUM  "No","Yes","vector_leerstring";
BA_DEF_  "Manufacturer" STRING ;
BA_DEF_  "ProtocolType" STRING ;
BA_DEF_  "BusType" STRING ;
BA_DEF_ SG_  "SystemSignalLongSymbol" STRING ;
BA_DEF_ BO_  "SystemMessageLongSymbol" STRING ;
BA_DEF_DEF_  "TpOwnSystemEcuNumber" 251;
BA_DEF_DEF_  "SigType" "DEFAULT";
BA_DEF_DEF_  "VFrameFormat" "CAN Extended";
BA_DEF_DEF_  "GenMsgSendType" "noMsgSendType";
BA_DEF_DEF_  "GenMsgCycleTime" 1000;
BA_DEF_DEF_  "GenMsgStartDelayTime" 0;
BA_DEF_DEF_  "ECU" "(null)";
BA_DEF_DEF_  "NmStationAddress" 251;
BA_DEF_DEF_  "GenMsgILSupport" "Yes";
BA_DEF_DEF_  "ILUsed" "Yes";
BA_DEF_DEF_  "Manufacturer" "Vector";
BA_DEF_DEF_  "ProtocolType" "J1939";
BA_DEF_DEF_  "BusType" "CAN";
BA_DEF_DEF_  "SystemSignalLongSymbol" "";
BA_DEF_DEF_  "GenSigSendType" "NoSigSendType";
BA_ "ECU" BU_ CM4 "CM4";

BA_ "GenMsgILSupport" BO_ 2348885845 0;
BA_ "GenMsgSendType" BO_ 2348885845 0;
BA_ "GenMsgCycleTime" BO_ 2348885845 100;
BA_ "GenMsgStartDelayTime" BO_ 2348885845 20;

BA_ "GenMsgSendType" BO_ 2349075285 0;
BA_ "GenMsgCycleTime" BO_ 2349075285 100;

BA_ "GenMsgILSupport" BO_ 2566894933 0;

BA_ "GenMsgILSupport" BO_ 2566656597 0;

BA_ "GenMsgILSupport" BO_ 2564816981 0;
BA_ "GenMsgSendType" BO_ 2564816981 0;

BA_ "GenMsgILSupport" BO_ 2364538256 0;
BA_ "GenMsgSendType" BO_ 2364538256 0;
BA_ "GenMsgCycleTime" BO_ 2364538256 10;

BA_ "GenMsgILSupport" BO_ 2348885904 0;
BA_ "GenMsgSendType" BO_ 2348885904 0;
BA_ "GenMsgCycleTime" BO_ 2348885904 100;
BA_ "GenMsgStartDelayTime" BO_ 2348885904 20;

BA_ "GenMsgSendType" BO_ 2349075344 0;
BA_ "GenMsgCycleTime" BO_ 2349075344 100;

BA_ "GenMsgILSupport" BO_ 2566894992 0;

BA_ "GenMsgILSupport" BO_ 2566897296 0;

BA_ "GenMsgILSupport" BO_ 2564817040 0;
BA_ "GenMsgSendType" BO_ 2564817040 0;

BA_ "GenMsgILSupport" BO_ 2566656656 0;

BA_ "GenMsgSendType" BO_ 2365443216 0;
BA_ "SystemMessageLongSymbol" BO_ 2365443216 "operatorsExtLightControlsMessage_VAR_BB2";
BA_ "GenMsgILSupport" BO_ 2564817041 0;
BA_ "GenMsgSendType" BO_ 2564817041 0;

BA_ "GenMsgILSupport" BO_ 2566656657 0;

BA_ "GenMsgILSupport" BO_ 2364538257 0;
BA_ "GenMsgSendType" BO_ 2364538257 0;
BA_ "GenMsgCycleTime" BO_ 2364538257 10;

BA_ "GenMsgSendType" BO_ 2365443217 0;
BA_ "SystemMessageLongSymbol" BO_ 2365443217 "operatorsExtLightControlsMessage_VAR_BB3";
BA_ "GenMsgILSupport" BO_ 2348885905 0;
BA_ "GenMsgSendType" BO_ 2348885905 0;
BA_ "GenMsgCycleTime" BO_ 2348885905 100;
BA_ "GenMsgStartDelayTime" BO_ 2348885905 20;

BA_ "GenMsgILSupport" BO_ 2566897297 0;

BA_ "GenMsgILSupport" BO_ 2566894993 0;

BA_ "GenMsgSendType" BO_ 2349075345 0;
BA_ "GenMsgCycleTime" BO_ 2349075345 100;

BA_ "GenMsgSendType" BO_ 2565865813 0;
BA_ "GenMsgCycleTime" BO_ 2565865813 100;
BA_ "VFrameFormat" BO_ 2565865813 3;

BA_ "GenMsgSendType" BO_ 2364538197 0;
BA_ "GenMsgCycleTime" BO_ 2364538197 10;

BA_ "GenMsgSendType" BO_ 2365573717 0;
BA_ "GenMsgCycleTime" BO_ 2365573717 50;

BA_ "GenMsgILSupport" BO_ 2633998843 0;

BA_ "GenMsgILSupport" BO_ 2600458491 0;
BA_ "GenMsgCycleTime" BO_ 2600458491 1500;

BA_ "GenMsgILSupport" BO_ 2600458235 0;
BA_ "GenMsgCycleTime" BO_ 2600458235 1500;

BA_ "GenMsgILSupport" BO_ 2566842107 0;
BA_ "GenMsgCycleTime" BO_ 2566842107 1500;

BA_ "GenMsgILSupport" BO_ 2566649595 0;
BA_ "GenMsgCycleTime" BO_ 2566649595 1500;

BA_ "GenMsgILSupport" BO_ 2566842619 0;
BA_ "GenMsgCycleTime" BO_ 2566842619 1500;

BA_ "GenMsgILSupport" BO_ 2566845435 0;
BA_ "GenMsgCycleTime" BO_ 2566845435 1500;

BA_ "GenMsgILSupport" BO_ 2583638267 0;
BA_ "GenMsgCycleTime" BO_ 2583638267 0;

BA_ "GenMsgILSupport" BO_ 2564484859 0;
BA_ "GenMsgCycleTime" BO_ 2564484859 0;

BA_ "GenMsgILSupport" BO_ 2564554736 0;
BA_ "GenMsgCycleTime" BO_ 2564554736 0;

BA_ "GenMsgILSupport" BO_ 2564484632 0;
BA_ "GenMsgCycleTime" BO_ 2564484632 0;

BA_ "GenMsgILSupport" BO_ 2600460056 0;
BA_ "GenMsgCycleTime" BO_ 2600460056 0;
BA_ "VFrameFormat" BO_ 2600460056 3;

BA_ "GenMsgILSupport" BO_ 2600403195 0;
BA_ "GenMsgCycleTime" BO_ 2600403195 0;

BA_ "GenMsgILSupport" BO_ 2566893819 0;
BA_ "GenMsgCycleTime" BO_ 2566893819 0;

BA_ "GenMsgSendType" BO_ 2365443157 0;
BA_ "SystemMessageLongSymbol" BO_ 2365443157 "operatorsExtLightControlsMessage_VAR1";
BA_ "GenMsgILSupport" BO_ 2566895189 0;

BA_ "GenMsgILSupport" BO_ 2566679953 0;

BA_ "GenMsgILSupport" BO_ 2566679952 0;

BA_ "GenMsgILSupport" BO_ 2566679893 0;

BA_ "GenMsgILSupport" BO_ 2566895445 0;
BA_ "GenMsgSendType" BO_ 2566895445 0;
BA_ "GenMsgCycleTime" BO_ 2566895445 100;

BA_ "GenMsgILSupport" BO_ 2600454915 0;

BA_ "GenMsgSendType" BO_ 2583669489 0;

BA_ "GenMsgILSupport" BO_ 2600454923 0;
BA_ "VFrameFormat" BO_ 2600454923 3;

BA_ "GenMsgILSupport" BO_ 2600454916 0;
BA_ "VFrameFormat" BO_ 2600454916 3;

BA_ "GenMsgILSupport" BO_ 2351336021 0;
BA_ "GenMsgSendType" BO_ 2351336021 0;
BA_ "GenMsgCycleTime" BO_ 2351336021 10;

BA_ "GenMsgILSupport" BO_ 2364638805 0;
BA_ "GenMsgSendType" BO_ 2364638805 0;
BA_ "GenMsgCycleTime" BO_ 2364638805 100;

BA_ "GenMsgILSupport" BO_ 2365287765 0;
BA_ "GenMsgSendType" BO_ 2365287765 0;
BA_ "GenMsgCycleTime" BO_ 2365287765 100;

BA_ "GenMsgILSupport" BO_ 2562139997 0;

BA_ "GenMsgILSupport" BO_ 2566799505 0;

BA_ "GenMsgILSupport" BO_ 2566799445 0;

BA_ "GenMsgILSupport" BO_ 2566799504 0;

BA_ "GenMsgILSupport" BO_ 2566799760 0;

BA_ "GenMsgILSupport" BO_ 2566799761 0;

BA_ "GenMsgILSupport" BO_ 2566799701 0;

BA_ "GenMsgILSupport" BO_ 2566897493 0;
BA_ "GenMsgSendType" BO_ 2566897493 0;
BA_ "GenMsgCycleTime" BO_ 2566897493 100;

BA_ "GenMsgILSupport" BO_ 2566897237 0;

BA_ "GenMsgILSupport" BO_ 2566896278 0;
BA_ "GenMsgSendType" BO_ 2566896278 0;
BA_ "GenMsgCycleTime" BO_ 2566896278 40;

BA_ "GenMsgSendType" BO_ 2566759568 0;
BA_ "GenMsgCycleTime" BO_ 2566759568 100;

BA_ "GenMsgSendType" BO_ 2566759569 0;
BA_ "GenMsgCycleTime" BO_ 2566759569 100;

BA_ "GenMsgILSupport" BO_ 2600454917 0;
BA_ "GenMsgSendType" BO_ 2600454917 0;
BA_ "VFrameFormat" BO_ 2600454917 3;

BA_ "GenMsgILSupport" BO_ 2600454920 0;
BA_ "GenMsgSendType" BO_ 2600454920 0;
BA_ "GenMsgCycleTime" BO_ 2600454920 10000;
BA_ "VFrameFormat" BO_ 2600454920 3;

BA_ "GenMsgILSupport" BO_ 2564502513 0;
BA_ "GenMsgCycleTime" BO_ 2564502513 0;

BA_ "GenMsgSendType" BO_ 2566759509 0;
BA_ "GenMsgCycleTime" BO_ 2566759509 100;

BA_ "GenMsgILSupport" BO_ 2348820369 0;
BA_ "GenMsgSendType" BO_ 2348820369 0;
BA_ "GenMsgCycleTime" BO_ 2348820369 100;

BA_ "GenMsgILSupport" BO_ 2348820368 0;
BA_ "GenMsgSendType" BO_ 2348820368 0;
BA_ "GenMsgCycleTime" BO_ 2348820368 100;

BA_ "GenMsgSendType" BO_ 2348820309 0;
BA_ "GenMsgCycleTime" BO_ 2348820309 10;

BA_ "GenMsgSendType" BO_ 2600418645 0;
BA_ "GenMsgCycleTime" BO_ 2600418645 100;

BA_ "GenMsgSendType" BO_ 2600466261 0;
BA_ "GenMsgCycleTime" BO_ 2600466261 100;

BA_ "GenMsgILSupport" BO_ 2566894737 0;

BA_ "GenMsgILSupport" BO_ 2566894677 0;
BA_ "GenMsgSendType" BO_ 2566894677 0;
BA_ "GenMsgCycleTime" BO_ 2566894677 100;

BA_ "GenMsgILSupport" BO_ 2566894736 0;
BA_ "GenMsgSendType" BO_ 2566894736 0;
BA_ "GenMsgCycleTime" BO_ 2566894736 100;

BA_ "GenMsgILSupport" BO_ 2600454921 0;
BA_ "VFrameFormat" BO_ 2600454921 3;

BA_ "GenMsgILSupport" BO_ 2667525634 0;
BA_ "GenMsgCycleTime" BO_ 2667525634 5000;

BA_ "GenMsgILSupport" BO_ 2600454912 0;

BA_ "GenMsgILSupport" BO_ 2600415573 0;

BA_ "GenMsgILSupport" BO_ 2600415632 0;

BA_ "GenMsgILSupport" BO_ 2600415633 0;

BA_ "GenMsgILSupport" BO_ 2600454925 0;
BA_ "VFrameFormat" BO_ 2600454925 3;

BA_ "GenMsgILSupport" BO_ 2600454924 0;
BA_ "VFrameFormat" BO_ 2600454924 3;

BA_ "GenMsgILSupport" BO_ 2600454927 0;
BA_ "VFrameFormat" BO_ 2600454927 3;

BA_ "GenMsgILSupport" BO_ 2600454928 0;
BA_ "VFrameFormat" BO_ 2600454928 3;

BA_ "GenMsgILSupport" BO_ 2600454929 0;
BA_ "VFrameFormat" BO_ 2600454929 3;

BA_ "GenMsgILSupport" BO_ 2600454926 0;
BA_ "VFrameFormat" BO_ 2600454926 3;

BA_ "GenMsgILSupport" BO_ 2600454931 0;
BA_ "VFrameFormat" BO_ 2600454931 3;

BA_ "GenMsgILSupport" BO_ 2600454930 0;
BA_ "VFrameFormat" BO_ 2600454930 3;

BA_ "GenMsgILSupport" BO_ 2600454918 0;
BA_ "GenMsgSendType" BO_ 2600454918 0;
BA_ "VFrameFormat" BO_ 2600454918 3;

BA_ "GenMsgILSupport" BO_ 2600454913 0;

BA_ "GenMsgILSupport" BO_ 2600454914 0;
BA_ "GenMsgSendType" BO_ 2600454914 0;
BA_ "SystemSignalLongSymbol" SG_ 2566656597 leftFrontWindowPositionCommand_B "leftFrontWindowPositionCommand_BASE";
BA_ "SystemSignalLongSymbol" SG_ 2566656597 righFrontWindowPositionCommand_B "righFrontWindowPositionCommand_BASE";
BA_ "SystemSignalLongSymbol" SG_ 2566656656 leftFrontWindowPositionCommand_B "leftFrontWindowPositionCommand_BASE";
BA_ "SystemSignalLongSymbol" SG_ 2566656656 righFrontWindowPositionCommand_B "righFrontWindowPositionCommand_BASE";
BA_ "SystemSignalLongSymbol" SG_ 2566656657 leftFrontWindowPositionCommand_B "leftFrontWindowPositionCommand_BASE";
BA_ "SystemSignalLongSymbol" SG_ 2566656657 righFrontWindowPositionCommand_B "righFrontWindowPositionCommand_BASE";
BA_ "SystemSignalLongSymbol" SG_ 2364538197 engineReqSpeedControlConditions_ "engineReqSpeedControlConditions_KSM";
BA_ "SystemSignalLongSymbol" SG_ 2566799505 implementRightFwdWorkLightCmd_BA "implementRightFwdWorkLightCmd_BASE";
BA_ "SystemSignalLongSymbol" SG_ 2566799445 implementRightFwdWorkLightCmd_BA "implementRightFwdWorkLightCmd_BASE";
BA_ "SystemSignalLongSymbol" SG_ 2566799504 implementRightFwdWorkLightCmd_BA "implementRightFwdWorkLightCmd_BASE";
BA_ "SystemSignalLongSymbol" SG_ 2566799760 implementRightFwdWorkLightCmd_BA "implementRightFwdWorkLightCmd_BASE";
BA_ "SystemSignalLongSymbol" SG_ 2566799761 implementRightFwdWorkLightCmd_BA "implementRightFwdWorkLightCmd_BASE";
BA_ "SystemSignalLongSymbol" SG_ 2566799701 implementRightFwdWorkLightCmd_BA "implementRightFwdWorkLightCmd_BASE";
BA_ "SystemSignalLongSymbol" SG_ 2566759568 enableSwitch_transInputShaftPTO2 "enableSwitch_transInputShaftPTO2_BASE";
BA_ "SystemSignalLongSymbol" SG_ 2566759568 engagemStatus_PTOengAccesDrive1_ "engagemStatus_PTOengAccesDrive1_BASE";
BA_ "SystemSignalLongSymbol" SG_ 2566759568 enableSwitch_transInputShaftPTO1 "enableSwitch_transInputShaftPTO1_BASE";
BA_ "SystemSignalLongSymbol" SG_ 2566759568 enableSwitch_PTOengineFlywheel_B "enableSwitch_PTOengineFlywheel_BASE";
BA_ "SystemSignalLongSymbol" SG_ 2566759569 enableSwitch_transInputShaftPTO2 "enableSwitch_transInputShaftPTO2_BASE";
BA_ "SystemSignalLongSymbol" SG_ 2566759569 engagemStatus_PTOengAccesDrive1_ "engagemStatus_PTOengAccesDrive1_BASE";
BA_ "SystemSignalLongSymbol" SG_ 2566759569 enableSwitch_transInputShaftPTO1 "enableSwitch_transInputShaftPTO1_BASE";
BA_ "SystemSignalLongSymbol" SG_ 2566759569 enableSwitch_PTOengineFlywheel_B "enableSwitch_PTOengineFlywheel_BASE";
BA_ "SystemSignalLongSymbol" SG_ 2566759509 enableSwitch_transInputShaftPTO2 "enableSwitch_transInputShaftPTO2_BASE";
BA_ "SystemSignalLongSymbol" SG_ 2566759509 engagemStatus_PTOengAccesDrive1_ "engagemStatus_PTOengAccesDrive1_BASE";
BA_ "SystemSignalLongSymbol" SG_ 2566759509 enableSwitch_transInputShaftPTO1 "enableSwitch_transInputShaftPTO1_BASE";
BA_ "SystemSignalLongSymbol" SG_ 2566759509 enableSwitch_PTOengineFlywheel_B "enableSwitch_PTOengineFlywheel_BASE";
BA_ "SystemSignalLongSymbol" SG_ 2348820369 engineOverrideControlMode_TCU2EN "engineOverrideControlMode_TCU2ENGINE";
BA_ "SystemSignalLongSymbol" SG_ 2348820369 engineReqSpeedControlConditions_ "engineReqSpeedControlConditions_TCU2ENGINE";
BA_ "SystemSignalLongSymbol" SG_ 2348820369 engineReqTorqueTorqueLimit_TCU2E "engineReqTorqueTorqueLimit_TCU2ENGINE";
BA_ "SystemSignalLongSymbol" SG_ 2348820369 overrideControlModePriority_TCU2 "overrideControlModePriority_TCU2ENGINE";
BA_ "SystemSignalLongSymbol" SG_ 2348820369 engineReqSpeedSpeedLimit_TCU2ENG "engineReqSpeedSpeedLimit_TCU2ENGINE";
BA_ "SystemSignalLongSymbol" SG_ 2348820368 engineOverrideControlMode_TCU2EN "engineOverrideControlMode_TCU2ENGINE";
BA_ "SystemSignalLongSymbol" SG_ 2348820368 engineReqSpeedControlConditions_ "engineReqSpeedControlConditions_TCU2ENGINE";
BA_ "SystemSignalLongSymbol" SG_ 2348820368 engineReqTorqueTorqueLimit_TCU2E "engineReqTorqueTorqueLimit_TCU2ENGINE";
BA_ "SystemSignalLongSymbol" SG_ 2348820368 overrideControlModePriority_TCU2 "overrideControlModePriority_TCU2ENGINE";
BA_ "SystemSignalLongSymbol" SG_ 2348820368 engineReqSpeedSpeedLimit_TCU2ENG "engineReqSpeedSpeedLimit_TCU2ENGINE";
BA_ "SystemSignalLongSymbol" SG_ 2348820309 engineOverrideControlMode_TCU2EN "engineOverrideControlMode_TCU2ENGINE";
BA_ "SystemSignalLongSymbol" SG_ 2348820309 engineReqSpeedControlConditions_ "engineReqSpeedControlConditions_TCU2ENGINE";
BA_ "SystemSignalLongSymbol" SG_ 2348820309 engineReqTorqueTorqueLimit_TCU2E "engineReqTorqueTorqueLimit_TCU2ENGINE";
BA_ "SystemSignalLongSymbol" SG_ 2348820309 overrideControlModePriority_TCU2 "overrideControlModePriority_TCU2ENGINE";
BA_ "SystemSignalLongSymbol" SG_ 2348820309 engineReqSpeedSpeedLimit_TCU2ENG "engineReqSpeedSpeedLimit_TCU2ENGINE";

BA_ "GenSigSendType" SG_ 2348885845 gearShiftInhibitRequest_BASIS 0;
BA_ "GenSigSendType" SG_ 2348885845 torqueConvLockupDisableReq_BASIS 0;
BA_ "GenSigSendType" SG_ 2348885845 disengageDrivelineRequest_BASIS 0;
BA_ "GenSigSendType" SG_ 2348885845 transmissionMode1_BASE 0;
BA_ "GenSigSendType" SG_ 2349075285 externalAccelerationDemand_BASIS 0;
BA_ "GenSigSendType" SG_ 2349075285 XBRcontrolMode_BASIS 0;
BA_ "GenSigSendType" SG_ 2349075285 XBRmessageCounter_BASIS 0;
BA_ "GenSigSendType" SG_ 2349075285 XBRmessageChecksum_BASIS 0;
BA_ "GenSigSendType" SG_ 2566894933 bobuCAMreq1_BASE 0;
BA_ "GenSigSendType" SG_ 2566894933 bobuCAMreq2_BASE 0;
BA_ "GenSigSendType" SG_ 2566894933 bobuCAMreq3_BASE 0;
BA_ "GenSigSendType" SG_ 2566894933 bobuCAMreq4_BASE 0;
BA_ "GenSigSendType" SG_ 2566894933 bobuCAMreq5_BASE 0;
BA_ "GenSigSendType" SG_ 2566656597 leftFrontWindowPositionCommand_B 0;
BA_ "GenSigSendType" SG_ 2566656597 righFrontWindowPositionCommand_B 0;
BA_ "GenSigSendType" SG_ 2566656597 remoteCabDoorLockRequest_BASE 0;
BA_ "GenSigSendType" SG_ 2564816981 DPFregenerationInhibitSw_BASE 0;
BA_ "GenSigSendType" SG_ 2364538256 requestedRoadSpeedLimit_BASIS 0;
BA_ "GenSigSendType" SG_ 2364538256 CCswitchStatus_KSM 0;
BA_ "GenSigSendType" SG_ 2364538256 motorStart_KSM 0;
BA_ "GenSigSendType" SG_ 2364538256 motorStop_KSM 0;
BA_ "GenSigSendType" SG_ 2348885904 gearShiftInhibitRequest_BASIS 0;
BA_ "GenSigSendType" SG_ 2348885904 torqueConvLockupDisableReq_BASIS 0;
BA_ "GenSigSendType" SG_ 2348885904 disengageDrivelineRequest_BASIS 0;
BA_ "GenSigSendType" SG_ 2348885904 transmissionMode1_BASE 0;
BA_ "GenSigSendType" SG_ 2349075344 externalAccelerationDemand_BASIS 0;
BA_ "GenSigSendType" SG_ 2349075344 XBRcontrolMode_BASIS 0;
BA_ "GenSigSendType" SG_ 2349075344 XBRmessageCounter_BASIS 0;
BA_ "GenSigSendType" SG_ 2349075344 XBRmessageChecksum_BASIS 0;
BA_ "GenSigSendType" SG_ 2566894992 bobuCAMreq1_BASE 0;
BA_ "GenSigSendType" SG_ 2566894992 bobuCAMreq2_BASE 0;
BA_ "GenSigSendType" SG_ 2566894992 bobuCAMreq3_BASE 0;
BA_ "GenSigSendType" SG_ 2566894992 bobuCAMreq4_BASE 0;
BA_ "GenSigSendType" SG_ 2566894992 bobuCAMreq5_BASE 0;
BA_ "GenSigSendType" SG_ 2566897296 extCoolTempSetpointReq_BASE 0;
BA_ "GenSigSendType" SG_ 2566897296 bobuAudioMute_BASE 0;
BA_ "GenSigSendType" SG_ 2566897296 bobuRecircModeReq_BASE 0;
BA_ "GenSigSendType" SG_ 2566897296 footboardSw1_BASE 0;
BA_ "GenSigSendType" SG_ 2566897296 lockCruisRange_BASE 0;
BA_ "GenSigSendType" SG_ 2566897296 bobuSignalHornExtInhReq_BASE 0;
BA_ "GenSigSendType" SG_ 2564817040 DPFregenerationInhibitSw_BASE 0;
BA_ "GenSigSendType" SG_ 2566656656 leftFrontWindowPositionCommand_B 0;
BA_ "GenSigSendType" SG_ 2566656656 righFrontWindowPositionCommand_B 0;
BA_ "GenSigSendType" SG_ 2566656656 remoteCabDoorLockRequest_BASE 0;
BA_ "GenSigSendType" SG_ 2365443216 hazardLightSwitch_BASE 0;
BA_ "GenSigSendType" SG_ 2564817041 DPFregenerationInhibitSw_BASE 0;
BA_ "GenSigSendType" SG_ 2566656657 leftFrontWindowPositionCommand_B 0;
BA_ "GenSigSendType" SG_ 2566656657 righFrontWindowPositionCommand_B 0;
BA_ "GenSigSendType" SG_ 2566656657 remoteCabDoorLockRequest_BASE 0;
BA_ "GenSigSendType" SG_ 2364538257 requestedRoadSpeedLimit_BASIS 0;
BA_ "GenSigSendType" SG_ 2364538257 CCswitchStatus_KSM 0;
BA_ "GenSigSendType" SG_ 2364538257 motorStart_KSM 0;
BA_ "GenSigSendType" SG_ 2364538257 motorStop_KSM 0;
BA_ "GenSigSendType" SG_ 2365443217 hazardLightSwitch_BASE 0;
BA_ "GenSigSendType" SG_ 2348885905 gearShiftInhibitRequest_BASIS 0;
BA_ "GenSigSendType" SG_ 2348885905 torqueConvLockupDisableReq_BASIS 0;
BA_ "GenSigSendType" SG_ 2348885905 disengageDrivelineRequest_BASIS 0;
BA_ "GenSigSendType" SG_ 2348885905 transmissionMode1_BASE 0;
BA_ "GenSigSendType" SG_ 2566897297 extCoolTempSetpointReq_BASE 0;
BA_ "GenSigSendType" SG_ 2566897297 bobuAudioMute_BASE 0;
BA_ "GenSigSendType" SG_ 2566897297 bobuRecircModeReq_BASE 0;
BA_ "GenSigSendType" SG_ 2566897297 footboardSw1_BASE 0;
BA_ "GenSigSendType" SG_ 2566897297 lockCruisRange_BASE 0;
BA_ "GenSigSendType" SG_ 2566897297 bobuSignalHornExtInhReq_BASE 0;
BA_ "GenSigSendType" SG_ 2566894993 bobuCAMreq1_BASE 0;
BA_ "GenSigSendType" SG_ 2566894993 bobuCAMreq2_BASE 0;
BA_ "GenSigSendType" SG_ 2566894993 bobuCAMreq3_BASE 0;
BA_ "GenSigSendType" SG_ 2566894993 bobuCAMreq4_BASE 0;
BA_ "GenSigSendType" SG_ 2566894993 bobuCAMreq5_BASE 0;
BA_ "GenSigSendType" SG_ 2349075345 externalAccelerationDemand_BASIS 0;
BA_ "GenSigSendType" SG_ 2349075345 XBRcontrolMode_BASIS 0;
BA_ "GenSigSendType" SG_ 2349075345 XBRmessageCounter_BASIS 0;
BA_ "GenSigSendType" SG_ 2349075345 XBRmessageChecksum_BASIS 0;
BA_ "GenSigSendType" SG_ 2565865813 haltBrakeSwitch_BASIS 0;
BA_ "GenSigSendType" SG_ 2364538197 engineOverrideControlMode_KSM 0;
BA_ "GenSigSendType" SG_ 2364538197 engineReqSpeedControlConditions_ 0;
BA_ "GenSigSendType" SG_ 2364538197 engineReqTorqueTorqueLimit_KSM 0;
BA_ "GenSigSendType" SG_ 2364538197 requestedRoadSpeedLimit_BASIS 0;
BA_ "GenSigSendType" SG_ 2364538197 CCswitchStatus_KSM 0;
BA_ "GenSigSendType" SG_ 2364538197 motorStart_KSM 0;
BA_ "GenSigSendType" SG_ 2364538197 motorStop_KSM 0;
BA_ "GenSigSendType" SG_ 2364538197 ZDRmodeRequest_BASIS 0;
BA_ "GenSigSendType" SG_ 2364538197 engineReqSpeedSpeedLimit_KSM 0;
BA_ "GenSigSendType" SG_ 2365573717 gearShiftInhibitRequest_KSM 0;
BA_ "GenSigSendType" SG_ 2365573717 torqueConvLockupDisableReq_KSM 0;
BA_ "GenSigSendType" SG_ 2365573717 disengageDrivelineRequest_KSM 0;
BA_ "GenSigSendType" SG_ 2365573717 PTO3requestNMV_VAR1 0;
BA_ "GenSigSendType" SG_ 2365573717 PTO1request_VAR1 0;
BA_ "GenSigSendType" SG_ 2365573717 PTO2request_VAR1 0;
BA_ "GenSigSendType" SG_ 2365573717 driveProgramReqBobu_BASE 0;
BA_ "GenSigSendType" SG_ 2633998843 ASP2_CRC8_BASE 0;
BA_ "GenSigSendType" SG_ 2633998843 boBuAppFCNreq1_BASE 0;
BA_ "GenSigSendType" SG_ 2633998843 boBuAppFCNreq2_BASE 0;
BA_ "GenSigSendType" SG_ 2633998843 boBuAppFCNreq3_BASE 0;
BA_ "GenSigSendType" SG_ 2633998843 boBuAppFCNreq4_BASE 0;
BA_ "GenSigSendType" SG_ 2633998843 boBuAppFCNreq5_BASE 0;
BA_ "GenSigSendType" SG_ 2633998843 boBuAppFCNreq6_BASE 0;
BA_ "GenSigSendType" SG_ 2633998843 ASP2__cnt_BASE 0;
BA_ "GenSigSendType" SG_ 2600458491 vehPosCWGS84LatitudeGNSS_BASE 0;
BA_ "GenSigSendType" SG_ 2600458491 vehPosCWGS84LongitudeGNSS_BASE 0;
BA_ "GenSigSendType" SG_ 2600458235 vehPosWGS84AltitudeGNSS_BASE 0;
BA_ "GenSigSendType" SG_ 2600458235 vehPosPrecisionGNSS_BASE 0;
BA_ "GenSigSendType" SG_ 2600458235 GNSSpositionAge_BASE 0;
BA_ "GenSigSendType" SG_ 2600458235 navModeGNSS_BASE 0;
BA_ "GenSigSendType" SG_ 2600458235 qualityIndicatorGNSS_BASE 0;
BA_ "GenSigSendType" SG_ 2600458235 summerTimeGPS_BASE 0;
BA_ "GenSigSendType" SG_ 2600458235 timeSynchDelayGNSS_BASE 0;
BA_ "GenSigSendType" SG_ 2566842107 seconds_VAR1 0;
BA_ "GenSigSendType" SG_ 2566842107 hours_VAR1 0;
BA_ "GenSigSendType" SG_ 2566842107 month_VAR1 0;
BA_ "GenSigSendType" SG_ 2566842107 day_VAR1 0;
BA_ "GenSigSendType" SG_ 2566842107 year_VAR1 0;
BA_ "GenSigSendType" SG_ 2566842107 localMinuteOffset_VAR1 0;
BA_ "GenSigSendType" SG_ 2566842107 localHourOffset_VAR1 0;
BA_ "GenSigSendType" SG_ 2566842107 minutes_VAR1 0;
BA_ "GenSigSendType" SG_ 2566649595 numberSatellitesGNSS_BASE 0;
BA_ "GenSigSendType" SG_ 2566649595 vdopGNSS_BASE 0;
BA_ "GenSigSendType" SG_ 2566649595 pdopGNSS_BASE 0;
BA_ "GenSigSendType" SG_ 2566649595 tdopGNSS_BASE 0;
BA_ "GenSigSendType" SG_ 2566649595 hdopGNSS_BASE 0;
BA_ "GenSigSendType" SG_ 2566842619 compBearingGNSS_BASE 0;
BA_ "GenSigSendType" SG_ 2566842619 vehSpdGNSS_BASE 0;
BA_ "GenSigSendType" SG_ 2566842619 pitchGNSS_BASE 0;
BA_ "GenSigSendType" SG_ 2566842619 altitudeGNSS_BASE 0;
BA_ "GenSigSendType" SG_ 2566845435 vehPosWGS84LatitudeGNSS_BASE 0;
BA_ "GenSigSendType" SG_ 2566845435 vehPosWGS84LongitudeGNSS_BASE 0;
BA_ "GenSigSendType" SG_ 2583638267 appFrameworkCtrlAppID_BASE 3;
BA_ "GenSigSendType" SG_ 2583638267 appFrameworkAppCommand_BASE 3;
BA_ "GenSigSendType" SG_ 2564484859 UDSreq_TBM2DTCO 3;
BA_ "GenSigSendType" SG_ 2564554736 UDS_FCNF0_TO_ALL 3;
BA_ "GenSigSendType" SG_ 2564484632 UDSreq_CM42DTCO 3;
BA_ "GenSigSendType" SG_ 2600460056 rmtTstrInstallMsgHeaderRsp_BASE 3;
BA_ "GenSigSendType" SG_ 2600460056 rmtTstrInstallPduSize_BASE 3;
BA_ "GenSigSendType" SG_ 2600460056 rmtTstrInstallJobIdResp_BASE 3;
BA_ "GenSigSendType" SG_ 2600460056 rmtTstrInstallListIdxResp_BASE 3;
BA_ "GenSigSendType" SG_ 2600460056 rmtTstrInstallRespCode_BASE 3;
BA_ "GenSigSendType" SG_ 2600460056 rmtTstrInstallRespIdx_BASE 3;
BA_ "GenSigSendType" SG_ 2600460056 rmtTstrInstallTotNumOfResp_BASE 3;
BA_ "GenSigSendType" SG_ 2600460056 rmtTstrInstallContentSize_BASE 3;
BA_ "GenSigSendType" SG_ 2600460056 rmtTstrInstallContent_BASE 3;
BA_ "GenSigSendType" SG_ 2600403195 HB_Wakeup_BASE 3;
BA_ "GenSigSendType" SG_ 2600403195 NM_CBV_Res2_BASE 3;
BA_ "GenSigSendType" SG_ 2600403195 NM_CBV_Res3_BASE 3;
BA_ "GenSigSendType" SG_ 2600403195 NM_ActiveWakeupBit_BASE 3;
BA_ "GenSigSendType" SG_ 2600403195 NM_CBV_Res5_BASE 3;
BA_ "GenSigSendType" SG_ 2600403195 NM_CRI_BASE 3;
BA_ "GenSigSendType" SG_ 2600403195 NM_CBV_Res7_BASE 3;
BA_ "GenSigSendType" SG_ 2600403195 NM_State_BASE 3;
BA_ "GenSigSendType" SG_ 2600403195 NM_CarWakeup_BASE 3;
BA_ "GenSigSendType" SG_ 2600403195 NM_CC_BASE 3;
BA_ "GenSigSendType" SG_ 2600403195 NM_activeClamp15_BASE 3;
BA_ "GenSigSendType" SG_ 2600403195 NM_activeDiag_BASE 3;
BA_ "GenSigSendType" SG_ 2600403195 NM_activeTmin_BASE 3;
BA_ "GenSigSendType" SG_ 2600403195 NM_activeCWU_BASE 3;
BA_ "GenSigSendType" SG_ 2600403195 NM_activeFC_BASE 3;
BA_ "GenSigSendType" SG_ 2600403195 NM_Res29_BASE 3;
BA_ "GenSigSendType" SG_ 2600403195 NM_Res36_BASE 3;
BA_ "GenSigSendType" SG_ 2600403195 nmClusterActive00_BASE 3;
BA_ "GenSigSendType" SG_ 2600403195 nmClusterActive01_BASE 3;
BA_ "GenSigSendType" SG_ 2600403195 nmClusterActive02_BASE 3;
BA_ "GenSigSendType" SG_ 2600403195 nmClusterActive03_BASE 3;
BA_ "GenSigSendType" SG_ 2600403195 nmClusterActive04_BASE 3;
BA_ "GenSigSendType" SG_ 2600403195 nmClusterActive05_BASE 3;
BA_ "GenSigSendType" SG_ 2600403195 nmClusterActive06_BASE 3;
BA_ "GenSigSendType" SG_ 2600403195 nmClusterActive07_BASE 3;
BA_ "GenSigSendType" SG_ 2600403195 nmClusterActive08_BASE 3;
BA_ "GenSigSendType" SG_ 2600403195 nmClusterActive09_BASE 3;
BA_ "GenSigSendType" SG_ 2600403195 nmClusterActive10_BASE 3;
BA_ "GenSigSendType" SG_ 2600403195 nmClusterActive11_BASE 3;
BA_ "GenSigSendType" SG_ 2600403195 nmClusterActive12_BASE 3;
BA_ "GenSigSendType" SG_ 2600403195 nmClusterActive13_BASE 3;
BA_ "GenSigSendType" SG_ 2600403195 nmClusterActive14_BASE 3;
BA_ "GenSigSendType" SG_ 2600403195 nmClusterActive15_BASE 3;
BA_ "GenSigSendType" SG_ 2600403195 nmClusterActive16_BASE 3;
BA_ "GenSigSendType" SG_ 2600403195 nmClusterActive17_BASE 3;
BA_ "GenSigSendType" SG_ 2600403195 nmClusterActive18_BASE 3;
BA_ "GenSigSendType" SG_ 2600403195 nmClusterActive19_BASE 3;
BA_ "GenSigSendType" SG_ 2600403195 nmClusterActive20_BASE 3;
BA_ "GenSigSendType" SG_ 2600403195 nmClusterActive21_BASE 3;
BA_ "GenSigSendType" SG_ 2600403195 nmClusterActive22_BASE 3;
BA_ "GenSigSendType" SG_ 2600403195 nmClusterActive23_BASE 3;
BA_ "GenSigSendType" SG_ 2600403195 NM_CBV_Res0_BASE 3;
BA_ "GenSigSendType" SG_ 2600403195 NM_CBV_Res1_BASE 3;
BA_ "GenSigSendType" SG_ 2566893819 reihenfolge_TBM2MC 3;
BA_ "GenSigSendType" SG_ 2566893819 abfrageZWS_FWS_TBM2MC 3;
BA_ "GenSigSendType" SG_ 2566893819 typMeldung_TBM2MC 3;
BA_ "GenSigSendType" SG_ 2566893819 abfragetyp_TBM2MC 3;
BA_ "GenSigSendType" SG_ 2365443157 hazardLightSwitch_BASE 0;
BA_ "GenSigSendType" SG_ 2566895189 ASP2_CRC8_BASE 0;
BA_ "GenSigSendType" SG_ 2566895189 statusBodyEPTO_BASE 0;
BA_ "GenSigSendType" SG_ 2566895189 ePTOreqBodyBuilder_BASE 0;
BA_ "GenSigSendType" SG_ 2566895189 ASP2__cnt_BASE 0;
BA_ "GenSigSendType" SG_ 2566679953 vehicleHorn_BASE 0;
BA_ "GenSigSendType" SG_ 2566679953 reverseDrivingAlarm_BASE 0;
BA_ "GenSigSendType" SG_ 2566679952 vehicleHorn_BASE 0;
BA_ "GenSigSendType" SG_ 2566679952 reverseDrivingAlarm_BASE 0;
BA_ "GenSigSendType" SG_ 2566679893 vehicleHorn_BASE 0;
BA_ "GenSigSendType" SG_ 2566679893 reverseDrivingAlarm_BASE 0;
BA_ "GenSigSendType" SG_ 2566895445 BB_PlaceHolder_BASE 0;
BA_ "GenSigSendType" SG_ 2600454915 conMapSpdLimDC_BASE 0;
BA_ "GenSigSendType" SG_ 2600454915 conMapSpdLimPlayStreet_BASE 0;
BA_ "GenSigSendType" SG_ 2600454915 conMapSpdLimRural_BASE 0;
BA_ "GenSigSendType" SG_ 2600454915 conMapSpdLimMotorway_BASE 0;
BA_ "GenSigSendType" SG_ 2600454915 conMapSpdLimUrban_BASE 0;
BA_ "GenSigSendType" SG_ 2600454915 conMapSpdLimSC_BASE 0;
BA_ "GenSigSendType" SG_ 2583669489 ODSC_errorState_BASE 0;
BA_ "GenSigSendType" SG_ 2600454923 auxStatCM14placeholder_BASE 0;
BA_ "GenSigSendType" SG_ 2600454916 updtMstrUpdateStatus_BASE 0;
BA_ "GenSigSendType" SG_ 2600454916 updtMstrDispSupCheckbox_BASE 0;
BA_ "GenSigSendType" SG_ 2600454916 updtMstrUpdateTypeInfo_BASE 0;
BA_ "GenSigSendType" SG_ 2600454916 updtMstrDrvrNotifStatus_BASE 0;
BA_ "GenSigSendType" SG_ 2351336021 msgCRC8saeJ1939_BASE 0;
BA_ "GenSigSendType" SG_ 2351336021 MG1ICLimReqOCM_BASE 0;
BA_ "GenSigSendType" SG_ 2351336021 MG1ICmaxLimReq_BASE 0;
BA_ "GenSigSendType" SG_ 2351336021 MG1ICminLimReq_BASE 0;
BA_ "GenSigSendType" SG_ 2351336021 MG1ICsetpointModeReq_BASE 0;
BA_ "GenSigSendType" SG_ 2351336021 MG1ICsetpointReq_BASE 0;
BA_ "GenSigSendType" SG_ 2351336021 msgCNTsaeJ1939_BASE 0;
BA_ "GenSigSendType" SG_ 2364638805 msgCRC8saeJ1939_BASE 0;
BA_ "GenSigSendType" SG_ 2364638805 MG2IMF1setpointMode_BASE 0;
BA_ "GenSigSendType" SG_ 2364638805 msgCNTsaeJ1939_BASE 0;
BA_ "GenSigSendType" SG_ 2365287765 msgCRC8saeJ1939_BASE 0;
BA_ "GenSigSendType" SG_ 2365287765 actMotorTrqPrcnt_BASE 0;
BA_ "GenSigSendType" SG_ 2365287765 actMotorSpeedPrcnt_BASE 0;
BA_ "GenSigSendType" SG_ 2365287765 msgCNTsaeJ1939_BASE 0;
BA_ "GenSigSendType" SG_ 2562139997 hubVidInp1ConnectStatus_BASE 0;
BA_ "GenSigSendType" SG_ 2562139997 cameraHubTriggerPin3req_BASE 0;
BA_ "GenSigSendType" SG_ 2562139997 cameraHubTriggerPin4req_BASE 0;
BA_ "GenSigSendType" SG_ 2562139997 cameraHubVidChnnlState_BASE 0;
BA_ "GenSigSendType" SG_ 2562139997 hubVidInp2ConnectStatus_BASE 0;
BA_ "GenSigSendType" SG_ 2562139997 hubVidInp3ConnectStatus_BASE 0;
BA_ "GenSigSendType" SG_ 2562139997 hubVidInp4ConnectStatus_BASE 0;
BA_ "GenSigSendType" SG_ 2566799505 rotatingBeaconLightCmd_BASE 0;
BA_ "GenSigSendType" SG_ 2566799505 centerStopLightCmd_BASE 0;
BA_ "GenSigSendType" SG_ 2566799505 tractorMarkerLightCmd_BASE 0;
BA_ "GenSigSendType" SG_ 2566799505 rearFogLightCmd_BASE 0;
BA_ "GenSigSendType" SG_ 2566799505 lowBeamHLReq_BASE 0;
BA_ "GenSigSendType" SG_ 2566799505 implOEMOption1lightCmd_BASE 0;
BA_ "GenSigSendType" SG_ 2566799505 implementRightFwdWorkLightCmd_BA 0;
BA_ "GenSigSendType" SG_ 2566799505 implementRearWorkLightCmd_BASE 0;
BA_ "GenSigSendType" SG_ 2566799445 rotatingBeaconLightCmd_BASE 0;
BA_ "GenSigSendType" SG_ 2566799445 centerStopLightCmd_BASE 0;
BA_ "GenSigSendType" SG_ 2566799445 tractorMarkerLightCmd_BASE 0;
BA_ "GenSigSendType" SG_ 2566799445 rearFogLightCmd_BASE 0;
BA_ "GenSigSendType" SG_ 2566799445 lowBeamHLReq_BASE 0;
BA_ "GenSigSendType" SG_ 2566799445 implOEMOption1lightCmd_BASE 0;
BA_ "GenSigSendType" SG_ 2566799445 implementRightFwdWorkLightCmd_BA 0;
BA_ "GenSigSendType" SG_ 2566799445 implementRearWorkLightCmd_BASE 0;
BA_ "GenSigSendType" SG_ 2566799504 rotatingBeaconLightCmd_BASE 0;
BA_ "GenSigSendType" SG_ 2566799504 centerStopLightCmd_BASE 0;
BA_ "GenSigSendType" SG_ 2566799504 tractorMarkerLightCmd_BASE 0;
BA_ "GenSigSendType" SG_ 2566799504 rearFogLightCmd_BASE 0;
BA_ "GenSigSendType" SG_ 2566799504 lowBeamHLReq_BASE 0;
BA_ "GenSigSendType" SG_ 2566799504 implOEMOption1lightCmd_BASE 0;
BA_ "GenSigSendType" SG_ 2566799504 implementRightFwdWorkLightCmd_BA 0;
BA_ "GenSigSendType" SG_ 2566799504 implementRearWorkLightCmd_BASE 0;
BA_ "GenSigSendType" SG_ 2566799760 rotatingBeaconLightCmd_BASE 0;
BA_ "GenSigSendType" SG_ 2566799760 centerStopLightCmd_BASE 0;
BA_ "GenSigSendType" SG_ 2566799760 tractorMarkerLightCmd_BASE 0;
BA_ "GenSigSendType" SG_ 2566799760 rearFogLightCmd_BASE 0;
BA_ "GenSigSendType" SG_ 2566799760 lowBeamHLReq_BASE 0;
BA_ "GenSigSendType" SG_ 2566799760 implOEMOption1lightCmd_BASE 0;
BA_ "GenSigSendType" SG_ 2566799760 implementRightFwdWorkLightCmd_BA 0;
BA_ "GenSigSendType" SG_ 2566799760 implementRearWorkLightCmd_BASE 0;
BA_ "GenSigSendType" SG_ 2566799761 rotatingBeaconLightCmd_BASE 0;
BA_ "GenSigSendType" SG_ 2566799761 centerStopLightCmd_BASE 0;
BA_ "GenSigSendType" SG_ 2566799761 tractorMarkerLightCmd_BASE 0;
BA_ "GenSigSendType" SG_ 2566799761 rearFogLightCmd_BASE 0;
BA_ "GenSigSendType" SG_ 2566799761 lowBeamHLReq_BASE 0;
BA_ "GenSigSendType" SG_ 2566799761 implOEMOption1lightCmd_BASE 0;
BA_ "GenSigSendType" SG_ 2566799761 implementRightFwdWorkLightCmd_BA 0;
BA_ "GenSigSendType" SG_ 2566799761 implementRearWorkLightCmd_BASE 0;
BA_ "GenSigSendType" SG_ 2566799701 rotatingBeaconLightCmd_BASE 0;
BA_ "GenSigSendType" SG_ 2566799701 centerStopLightCmd_BASE 0;
BA_ "GenSigSendType" SG_ 2566799701 tractorMarkerLightCmd_BASE 0;
BA_ "GenSigSendType" SG_ 2566799701 rearFogLightCmd_BASE 0;
BA_ "GenSigSendType" SG_ 2566799701 lowBeamHLReq_BASE 0;
BA_ "GenSigSendType" SG_ 2566799701 implOEMOption1lightCmd_BASE 0;
BA_ "GenSigSendType" SG_ 2566799701 implementRightFwdWorkLightCmd_BA 0;
BA_ "GenSigSendType" SG_ 2566799701 implementRearWorkLightCmd_BASE 0;
BA_ "GenSigSendType" SG_ 2566897493 ASP2_CRC8_BASE 0;
BA_ "GenSigSendType" SG_ 2566897493 genericBobuIn101_BASE 0;
BA_ "GenSigSendType" SG_ 2566897493 genericBobuIn102_BASE 0;
BA_ "GenSigSendType" SG_ 2566897493 genericBobuIn103_BASE 0;
BA_ "GenSigSendType" SG_ 2566897493 genericBobuIn104_BASE 0;
BA_ "GenSigSendType" SG_ 2566897493 genericBobuIn105_BASE 0;
BA_ "GenSigSendType" SG_ 2566897493 genericBobuIn106_BASE 0;
BA_ "GenSigSendType" SG_ 2566897493 genericBobuIn201_BASE 0;
BA_ "GenSigSendType" SG_ 2566897493 genericBobuIn202_BASE 0;
BA_ "GenSigSendType" SG_ 2566897493 genericBobuIn203_BASE 0;
BA_ "GenSigSendType" SG_ 2566897493 genericBobuIn301_BASE 0;
BA_ "GenSigSendType" SG_ 2566897493 ASP2__cnt_BASE 0;
BA_ "GenSigSendType" SG_ 2566897237 extCoolTempSetpointReq_BASE 0;
BA_ "GenSigSendType" SG_ 2566897237 bobuAudioMute_BASE 0;
BA_ "GenSigSendType" SG_ 2566897237 bobuRecircModeReq_BASE 0;
BA_ "GenSigSendType" SG_ 2566897237 footboardSw1_BASE 0;
BA_ "GenSigSendType" SG_ 2566897237 lockCruisRange_BASE 0;
BA_ "GenSigSendType" SG_ 2566897237 bobuSignalHornExtInhReq_BASE 0;
BA_ "GenSigSendType" SG_ 2566896278 eHorizonData_BASE 0;
BA_ "GenSigSendType" SG_ 2566759568 enableSwitch_transInputShaftPTO2 0;
BA_ "GenSigSendType" SG_ 2566759568 engagemStatus_PTOengAccesDrive1_ 0;
BA_ "GenSigSendType" SG_ 2566759568 PTODEmsgCounter_BASE 0;
BA_ "GenSigSendType" SG_ 2566759568 enableSwitch_transInputShaftPTO1 0;
BA_ "GenSigSendType" SG_ 2566759568 PTODEchkSum_BASE 0;
BA_ "GenSigSendType" SG_ 2566759568 enableSwitch_PTOengineFlywheel_B 0;
BA_ "GenSigSendType" SG_ 2566759569 enableSwitch_transInputShaftPTO2 0;
BA_ "GenSigSendType" SG_ 2566759569 engagemStatus_PTOengAccesDrive1_ 0;
BA_ "GenSigSendType" SG_ 2566759569 PTODEmsgCounter_BASE 0;
BA_ "GenSigSendType" SG_ 2566759569 enableSwitch_transInputShaftPTO1 0;
BA_ "GenSigSendType" SG_ 2566759569 PTODEchkSum_BASE 0;
BA_ "GenSigSendType" SG_ 2566759569 enableSwitch_PTOengineFlywheel_B 0;
BA_ "GenSigSendType" SG_ 2600454917 extrnlChrgPmaxOTAreq_BASE 0;
BA_ "GenSigSendType" SG_ 2600454917 extrnlChrgOTAbooked_BASE 0;
BA_ "GenSigSendType" SG_ 2600454917 cntrctCertChrgI1OTAreq_BASE 0;
BA_ "GenSigSendType" SG_ 2600454917 cntrctCertChrgI2OTAreq_BASE 0;
BA_ "GenSigSendType" SG_ 2600454917 extrnlChrgHVACstrgyOTAreq_BASE 0;
BA_ "GenSigSendType" SG_ 2600454917 extrnlChrgHldInfOTAreq_BASE 0;
BA_ "GenSigSendType" SG_ 2600454917 extrnlChrgPnCslctdOTAreq_BASE 0;
BA_ "GenSigSendType" SG_ 2600454917 extrnlChrgAMS_OTAreq_BASE 0;
BA_ "GenSigSendType" SG_ 2600454917 extrnlChrgFastChrgOTAreq_BASE 0;
BA_ "GenSigSendType" SG_ 2600454917 extrnlChrgOTActrlOTAreq_BASE 0;
BA_ "GenSigSendType" SG_ 2600454917 extrnlChrgSelPrcTypOTAreq_BASE 0;
BA_ "GenSigSendType" SG_ 2600454917 extrnlChrgHVACheatLvOTAreq_BASE 0;
BA_ "GenSigSendType" SG_ 2600454917 extrnlChrgBulkSOC_OTAreq_BASE 0;
BA_ "GenSigSendType" SG_ 2600454917 extrnlChrgHVACtempOTAreq_BASE 0;
BA_ "GenSigSendType" SG_ 2600454920 mapVersion_BASE 0;
BA_ "GenSigSendType" SG_ 2564502513 UDSreq_F1_OBD 3;
BA_ "GenSigSendType" SG_ 2566759509 enableSwitch_transInputShaftPTO2 0;
BA_ "GenSigSendType" SG_ 2566759509 engagemStatus_PTOengAccesDrive1_ 0;
BA_ "GenSigSendType" SG_ 2566759509 PTODEmsgCounter_BASE 0;
BA_ "GenSigSendType" SG_ 2566759509 enableSwitch_transInputShaftPTO1 0;
BA_ "GenSigSendType" SG_ 2566759509 PTODEchkSum_BASE 0;
BA_ "GenSigSendType" SG_ 2566759509 enableSwitch_PTOengineFlywheel_B 0;
BA_ "GenSigSendType" SG_ 2348820369 engineOverrideControlMode_TCU2EN 0;
BA_ "GenSigSendType" SG_ 2348820369 engineReqSpeedControlConditions_ 0;
BA_ "GenSigSendType" SG_ 2348820369 engineReqTorqueTorqueLimit_TCU2E 0;
BA_ "GenSigSendType" SG_ 2348820369 overrideControlModePriority_TCU2 0;
BA_ "GenSigSendType" SG_ 2348820369 TSC1messageCounterTCU2ENG_BASE 0;
BA_ "GenSigSendType" SG_ 2348820369 TSC1messageChecksumTCU2ENG_BASE 0;
BA_ "GenSigSendType" SG_ 2348820369 engineReqSpeedSpeedLimit_TCU2ENG 0;
BA_ "GenSigSendType" SG_ 2348820368 engineOverrideControlMode_TCU2EN 0;
BA_ "GenSigSendType" SG_ 2348820368 engineReqSpeedControlConditions_ 0;
BA_ "GenSigSendType" SG_ 2348820368 engineReqTorqueTorqueLimit_TCU2E 0;
BA_ "GenSigSendType" SG_ 2348820368 overrideControlModePriority_TCU2 0;
BA_ "GenSigSendType" SG_ 2348820368 TSC1messageCounterTCU2ENG_BASE 0;
BA_ "GenSigSendType" SG_ 2348820368 TSC1messageChecksumTCU2ENG_BASE 0;
BA_ "GenSigSendType" SG_ 2348820368 engineReqSpeedSpeedLimit_TCU2ENG 0;
BA_ "GenSigSendType" SG_ 2348820309 engineOverrideControlMode_TCU2EN 0;
BA_ "GenSigSendType" SG_ 2348820309 engineReqSpeedControlConditions_ 0;
BA_ "GenSigSendType" SG_ 2348820309 engineReqTorqueTorqueLimit_TCU2E 0;
BA_ "GenSigSendType" SG_ 2348820309 overrideControlModePriority_TCU2 0;
BA_ "GenSigSendType" SG_ 2348820309 TSC1messageCounterTCU2ENG_BASE 0;
BA_ "GenSigSendType" SG_ 2348820309 TSC1messageChecksumTCU2ENG_BASE 0;
BA_ "GenSigSendType" SG_ 2348820309 engineReqSpeedSpeedLimit_TCU2ENG 0;
BA_ "GenSigSendType" SG_ 2600418645 parkBrkAppReq_BASE 0;
BA_ "GenSigSendType" SG_ 2600418645 parkBrkRlsReq_BASE 0;
BA_ "GenSigSendType" SG_ 2600418645 EPB2messageCounter_BASE 0;
BA_ "GenSigSendType" SG_ 2600418645 EPB2messageChecksum_BASE 0;
BA_ "GenSigSendType" SG_ 2600418645 parkBrkRlsInhibit_BASE 0;
BA_ "GenSigSendType" SG_ 2600466261 levelControlModeRequest_BASIS 0;
BA_ "GenSigSendType" SG_ 2600466261 prohibitAutomaticASC_BASE 0;
BA_ "GenSigSendType" SG_ 2600466261 leftTurnSignalLightsCmd_BASE 0;
BA_ "GenSigSendType" SG_ 2600466261 rightTurnSignalLightsCmd_BASE 0;
BA_ "GenSigSendType" SG_ 2600466261 footboardSw1_BASE 0;
BA_ "GenSigSendType" SG_ 2600466261 generalCamera3Active_BASE 0;
BA_ "GenSigSendType" SG_ 2600466261 generalCamera4Active_BASE 0;
BA_ "GenSigSendType" SG_ 2600466261 extAccelDemReqBB2_BASE 0;
BA_ "GenSigSendType" SG_ 2600466261 bobuNomLvlReqAxle_BASE 0;
BA_ "GenSigSendType" SG_ 2600466261 extBrakeDemBB2_BASE 0;
BA_ "GenSigSendType" SG_ 2600466261 KSM3cntE2E_BASE 0;
BA_ "GenSigSendType" SG_ 2600466261 KSM3chkE2E_BASE 0;
BA_ "GenSigSendType" SG_ 2566894737 ASP2_CRC8_BASE 0;
BA_ "GenSigSendType" SG_ 2566894737 bobuLiftAxle1posCmd_BASE 0;
BA_ "GenSigSendType" SG_ 2566894737 bobuLiftAxle2posCmd_BASE 0;
BA_ "GenSigSendType" SG_ 2566894737 bobuLvlCtrlModeRequest_BASE 0;
BA_ "GenSigSendType" SG_ 2566894737 bobuNomLvlReqRA_BASE 0;
BA_ "GenSigSendType" SG_ 2566894737 bobuNomLvlReqFA_BASE 0;
BA_ "GenSigSendType" SG_ 2566894737 bobuProhibitAutoASC_BASE 0;
BA_ "GenSigSendType" SG_ 2566894737 ASP2__cnt_BASE 0;
BA_ "GenSigSendType" SG_ 2566894677 ASP2_CRC8_BASE 0;
BA_ "GenSigSendType" SG_ 2566894677 bobuLiftAxle1posCmd_BASE 0;
BA_ "GenSigSendType" SG_ 2566894677 bobuLiftAxle2posCmd_BASE 0;
BA_ "GenSigSendType" SG_ 2566894677 bobuLvlCtrlModeRequest_BASE 0;
BA_ "GenSigSendType" SG_ 2566894677 bobuNomLvlReqRA_BASE 0;
BA_ "GenSigSendType" SG_ 2566894677 bobuNomLvlReqFA_BASE 0;
BA_ "GenSigSendType" SG_ 2566894677 bobuProhibitAutoASC_BASE 0;
BA_ "GenSigSendType" SG_ 2566894677 ASP2__cnt_BASE 0;
BA_ "GenSigSendType" SG_ 2566894736 ASP2_CRC8_BASE 0;
BA_ "GenSigSendType" SG_ 2566894736 bobuLiftAxle1posCmd_BASE 0;
BA_ "GenSigSendType" SG_ 2566894736 bobuLiftAxle2posCmd_BASE 0;
BA_ "GenSigSendType" SG_ 2566894736 bobuLvlCtrlModeRequest_BASE 0;
BA_ "GenSigSendType" SG_ 2566894736 bobuNomLvlReqRA_BASE 0;
BA_ "GenSigSendType" SG_ 2566894736 bobuNomLvlReqFA_BASE 0;
BA_ "GenSigSendType" SG_ 2566894736 bobuProhibitAutoASC_BASE 0;
BA_ "GenSigSendType" SG_ 2566894736 ASP2__cnt_BASE 0;
BA_ "GenSigSendType" SG_ 2600454921 conMapMaxSpdLimMotorway_BASE 0;
BA_ "GenSigSendType" SG_ 2600454921 conMapMaxSpdLimSC_BASE 0;
BA_ "GenSigSendType" SG_ 2600454921 conMapMaxSpdLimRural_BASE 0;
BA_ "GenSigSendType" SG_ 2600454921 conMapMaxSpdLimUrban_BASE 0;
BA_ "GenSigSendType" SG_ 2600454921 conMapMaxSpdLimPlayStreet_BASE 0;
BA_ "GenSigSendType" SG_ 2600454921 conMapMaxSpdLimDC_BASE 0;
BA_ "GenSigSendType" SG_ 2667525634 driveProgramAppVersion_BASE 0;
BA_ "GenSigSendType" SG_ 2667525634 appValSlider1Req_BASE 0;
BA_ "GenSigSendType" SG_ 2667525634 appValSwitch4Req_BASE 0;
BA_ "GenSigSendType" SG_ 2667525634 appValSwitch5Req_BASE 0;
BA_ "GenSigSendType" SG_ 2667525634 appValSwitch2Req_BASE 0;
BA_ "GenSigSendType" SG_ 2667525634 appValSwitch1Req_BASE 0;
BA_ "GenSigSendType" SG_ 2667525634 appValSwitch3Req_BASE 0;
BA_ "GenSigSendType" SG_ 2667525634 activateDrvProgConfig_BASE 0;
BA_ "GenSigSendType" SG_ 2667525634 appValSlider4Req_BASE 0;
BA_ "GenSigSendType" SG_ 2667525634 appValSlider5Req_BASE 0;
BA_ "GenSigSendType" SG_ 2667525634 appValSlider6Req_BASE 0;
BA_ "GenSigSendType" SG_ 2667525634 appValSlider2Req_BASE 0;
BA_ "GenSigSendType" SG_ 2667525634 appValSlider3Req_BASE 0;
BA_ "GenSigSendType" SG_ 2600454912 chllngngEnvrnmntDet_BASE 0;
BA_ "GenSigSendType" SG_ 2600415573 genericBobuDisp1_BASE 0;
BA_ "GenSigSendType" SG_ 2600415573 genericBobuDisp6_BASE 0;
BA_ "GenSigSendType" SG_ 2600415573 genericBobuDisp7_BASE 0;
BA_ "GenSigSendType" SG_ 2600415573 genericBobuDisp8_BASE 0;
BA_ "GenSigSendType" SG_ 2600415573 genericBobuDisp9_BASE 0;
BA_ "GenSigSendType" SG_ 2600415573 genericBobuDisp10_BASE 0;
BA_ "GenSigSendType" SG_ 2600415573 genericBobuDisp2_BASE 0;
BA_ "GenSigSendType" SG_ 2600415573 genericBobuDisp3_BASE 0;
BA_ "GenSigSendType" SG_ 2600415573 BBDcntE2E_BASE 0;
BA_ "GenSigSendType" SG_ 2600415573 genericBobuDisp4_BASE 0;
BA_ "GenSigSendType" SG_ 2600415573 BBDchkE2E_BASE 0;
BA_ "GenSigSendType" SG_ 2600415573 genericBobuDisp5_BASE 0;
BA_ "GenSigSendType" SG_ 2600415632 genericBobuDisp1_BASE 0;
BA_ "GenSigSendType" SG_ 2600415632 genericBobuDisp6_BASE 0;
BA_ "GenSigSendType" SG_ 2600415632 genericBobuDisp7_BASE 0;
BA_ "GenSigSendType" SG_ 2600415632 genericBobuDisp8_BASE 0;
BA_ "GenSigSendType" SG_ 2600415632 genericBobuDisp9_BASE 0;
BA_ "GenSigSendType" SG_ 2600415632 genericBobuDisp10_BASE 0;
BA_ "GenSigSendType" SG_ 2600415632 genericBobuDisp2_BASE 0;
BA_ "GenSigSendType" SG_ 2600415632 genericBobuDisp3_BASE 0;
BA_ "GenSigSendType" SG_ 2600415632 BBDcntE2E_BASE 0;
BA_ "GenSigSendType" SG_ 2600415632 genericBobuDisp4_BASE 0;
BA_ "GenSigSendType" SG_ 2600415632 BBDchkE2E_BASE 0;
BA_ "GenSigSendType" SG_ 2600415632 genericBobuDisp5_BASE 0;
BA_ "GenSigSendType" SG_ 2600415633 genericBobuDisp1_BASE 0;
BA_ "GenSigSendType" SG_ 2600415633 genericBobuDisp6_BASE 0;
BA_ "GenSigSendType" SG_ 2600415633 genericBobuDisp7_BASE 0;
BA_ "GenSigSendType" SG_ 2600415633 genericBobuDisp8_BASE 0;
BA_ "GenSigSendType" SG_ 2600415633 genericBobuDisp9_BASE 0;
BA_ "GenSigSendType" SG_ 2600415633 genericBobuDisp10_BASE 0;
BA_ "GenSigSendType" SG_ 2600415633 genericBobuDisp2_BASE 0;
BA_ "GenSigSendType" SG_ 2600415633 genericBobuDisp3_BASE 0;
BA_ "GenSigSendType" SG_ 2600415633 BBDcntE2E_BASE 0;
BA_ "GenSigSendType" SG_ 2600415633 genericBobuDisp4_BASE 0;
BA_ "GenSigSendType" SG_ 2600415633 BBDchkE2E_BASE 0;
BA_ "GenSigSendType" SG_ 2600415633 genericBobuDisp5_BASE 0;
BA_ "GenSigSendType" SG_ 2600454925 auxStatCM16placeholder_BASE 0;
BA_ "GenSigSendType" SG_ 2600454924 auxStatCM15placeholder_BASE 0;
BA_ "GenSigSendType" SG_ 2600454927 auxStatCM18placeholder_BASE 0;
BA_ "GenSigSendType" SG_ 2600454928 auxStatCM19placeholder_BASE 0;
BA_ "GenSigSendType" SG_ 2600454929 auxStatCM20placeholder_BASE 0;
BA_ "GenSigSendType" SG_ 2600454926 auxStatCM17placeholder_BASE 0;
BA_ "GenSigSendType" SG_ 2600454931 auxStatCM22placeholder_BASE 0;
BA_ "GenSigSendType" SG_ 2600454930 auxStatCM21placeholder_BASE 0;
BA_ "GenSigSendType" SG_ 2600454918 vehDepartTimeOTAreq_BASE 0;
BA_ "GenSigSendType" SG_ 2600454918 extrnlChrgModeOTAreq_BASE 0;
BA_ "GenSigSendType" SG_ 2600454918 extrnlChrgPreCondOTAreq_BASE 0;
BA_ "GenSigSendType" SG_ 2600454918 extrnlChrgAllwdOTAreq_BASE 0;
BA_ "GenSigSendType" SG_ 2600454918 extrnlChrgTargetSOcOTAreq_BASE 0;
BA_ "GenSigSendType" SG_ 2600454918 vehSbyDurationOTAreq_BASE 0;
BA_ "GenSigSendType" SG_ 2600454913 auxStatCM5_CRC_BASE 0;
BA_ "GenSigSendType" SG_ 2600454913 SRPACCdistLvl_BASE 0;
BA_ "GenSigSendType" SG_ 2600454913 SRPmaxSagSpd_BASE 0;
BA_ "GenSigSendType" SG_ 2600454913 SRPmaxSpdIndexPCCA_BASE 0;
BA_ "GenSigSendType" SG_ 2600454913 SRPminSumSpd_BASE 0;
BA_ "GenSigSendType" SG_ 2600454913 SRPreqVehSpdCC_BASE 0;
BA_ "GenSigSendType" SG_ 2600454913 SRPecoLevel_BASE 0;
BA_ "GenSigSendType" SG_ 2600454913 SRPchangeType_BASE 0;
BA_ "GenSigSendType" SG_ 2600454913 auxStatCM5_Cnt_BASE 0;
BA_ "GenSigSendType" SG_ 2600454914 wasteEnergyModeDurSRP_BASE 0;
BA_ "GenSigSendType" SG_ 2600454914 SRPsegmentID_BASE 0;
BA_ "GenSigSendType" SG_ 2600454914 SRPdrivingProg_BASE 0;
BA_ "GenSigSendType" SG_ 2600454914 wasteEnergyModeActSRP_BASE 0;
BA_ "GenSigSendType" SG_ 2600454914 predEnrgyToNextCS_BASE 0;
BA_ "GenSigSendType" SG_ 2600454914 predDistToNextCS_BASE 0;
BA_ "GenSigSendType" SG_ 2600454914 SRPspeedLimit_BASE 0;

VAL_ 2348885845 gearShiftInhibitRequest_BASIS 0 "gear shifts are allowed" 1 "gear shifts are inhibited" 2 "invalid" 3 "take no action";
VAL_ 2348885845 torqueConvLockupDisableReq_BASIS 0 "allow torque converter lockup" 1 "disable torque converter lockup" 2 "error" 3 "not available";
VAL_ 2348885845 disengageDrivelineRequest_BASIS 0 "Allow driveline engagement" 1 "Disengage driveline" 2 "invalid" 3 "Take no action";
VAL_ 2348885845 transmissionMode1_BASE 0 "Transmission Mode 1 not active" 1 "Transmission Mode 1 Active" 2 "error" 3 "not available";
VAL_ 2349075285 XBRcontrolMode_BASIS 0 "Override disabled" 1 "acceleration control with addition mode" 2 "acceleration control with maximum mode" 3 "not defined";
VAL_ 2566894933 bobuCAMreq1_BASE 0 "not requested" 1 "requested" 2 "error" 3 "not available";
VAL_ 2566894933 bobuCAMreq2_BASE 0 "not requested" 1 "requested" 2 "error" 3 "not available";
VAL_ 2566894933 bobuCAMreq3_BASE 0 "not requested" 1 "requested" 2 "error" 3 "not available";
VAL_ 2566894933 bobuCAMreq4_BASE 0 "not requested" 1 "requested" 2 "error" 3 "not available";
VAL_ 2566894933 bobuCAMreq5_BASE 0 "not requested" 1 "requested" 2 "error" 3 "not available";
VAL_ 2566656597 leftFrontWindowPositionCommand_B 0 "window move up" 1 "window move down" 2 "window auto up" 3 "window auto down" 4 "reserved" 5 "reserved" 6 "reserved" 7 "take no action";
VAL_ 2566656597 righFrontWindowPositionCommand_B 0 "window move up" 1 "window move down" 2 "window auto up" 3 "window auto down" 4 "reserved" 5 "reserved" 6 "reserved" 7 "take no action";
VAL_ 2566656597 remoteCabDoorLockRequest_BASE 0 "request unlock left front cab door latch (driver door on LH steer vehicles)" 1 "request unlock right front cab door latch (front passenger door for LH steer vehicles)" 2 "request unlock left rear cab door latch" 3 "request unlock right rear cab door latch" 4 "request unlock all cab door latches" 5 "request lock all cab door latches" 6 "reserved" 7 "take no action";
VAL_ 2564816981 DPFregenerationInhibitSw_BASE 0 "not active" 1 "active" 2 "error" 3 "not available";
VAL_ 2364538256 CCswitchStatus_KSM 0 "neutral" 1 "Aus" 4 "Set-" 16 "Wiederaufnahme" 64 "Set+" 170 "Defekt";
VAL_ 2364538256 motorStart_KSM 0 "keine Start-Anforderung" 1 "Anforderung Normal Start" 2 "Anforderung Not Start" 3 "not defined, keine Anforderung";
VAL_ 2364538256 motorStop_KSM 0 "normale_Mengensollwertbildung" 1 "Nullmenge wegen Motor Stop" 2 "invalid, wie Interpretation wie 00" 3 "invalid, wie Interpretation wie 00";
VAL_ 2348885904 gearShiftInhibitRequest_BASIS 0 "gear shifts are allowed" 1 "gear shifts are inhibited" 2 "invalid" 3 "take no action";
VAL_ 2348885904 torqueConvLockupDisableReq_BASIS 0 "allow torque converter lockup" 1 "disable torque converter lockup" 2 "error" 3 "not available";
VAL_ 2348885904 disengageDrivelineRequest_BASIS 0 "Allow driveline engagement" 1 "Disengage driveline" 2 "invalid" 3 "Take no action";
VAL_ 2348885904 transmissionMode1_BASE 0 "Transmission Mode 1 not active" 1 "Transmission Mode 1 Active" 2 "error" 3 "not available";
VAL_ 2349075344 XBRcontrolMode_BASIS 0 "Override disabled" 1 "acceleration control with addition mode" 2 "acceleration control with maximum mode" 3 "not defined";
VAL_ 2566894992 bobuCAMreq1_BASE 0 "not requested" 1 "requested" 2 "error" 3 "not available";
VAL_ 2566894992 bobuCAMreq2_BASE 0 "not requested" 1 "requested" 2 "error" 3 "not available";
VAL_ 2566894992 bobuCAMreq3_BASE 0 "not requested" 1 "requested" 2 "error" 3 "not available";
VAL_ 2566894992 bobuCAMreq4_BASE 0 "not requested" 1 "requested" 2 "error" 3 "not available";
VAL_ 2566894992 bobuCAMreq5_BASE 0 "not requested" 1 "requested" 2 "error" 3 "not available";
VAL_ 2566897296 bobuAudioMute_BASE 0 "no request" 1 "request" 2 "error" 3 "not available";
VAL_ 2566897296 bobuRecircModeReq_BASE 0 "take no action" 1 "request to activate recirculation mode" 2 "error" 3 "not available";
VAL_ 2566897296 footboardSw1_BASE 0 "Footboard not occupied" 1 "Footboard occupied" 2 "error" 3 "not available";
VAL_ 2566897296 lockCruisRange_BASE 0 "no action" 1 "lock change to R" 2 "lock change to D" 3 "lock change to R and D" 4 "reserved" 5 "reserved" 6 "reserved" 7 "reserved" 8 "reserved" 9 "reserved" 10 "reserved" 11 "reserved" 12 "reserved" 13 "reserved" 14 "error" 15 "not available";
VAL_ 2566897296 bobuSignalHornExtInhReq_BASE 0 "no action" 1 "inhibit horn" 2 "error" 3 "not available";
VAL_ 2564817040 DPFregenerationInhibitSw_BASE 0 "not active" 1 "active" 2 "error" 3 "not available";
VAL_ 2566656656 leftFrontWindowPositionCommand_B 0 "window move up" 1 "window move down" 2 "window auto up" 3 "window auto down" 4 "reserved" 5 "reserved" 6 "reserved" 7 "take no action";
VAL_ 2566656656 righFrontWindowPositionCommand_B 0 "window move up" 1 "window move down" 2 "window auto up" 3 "window auto down" 4 "reserved" 5 "reserved" 6 "reserved" 7 "take no action";
VAL_ 2566656656 remoteCabDoorLockRequest_BASE 0 "request unlock left front cab door latch (driver door on LH steer vehicles)" 1 "request unlock right front cab door latch (front passenger door for LH steer vehicles)" 2 "request unlock left rear cab door latch" 3 "request unlock right rear cab door latch" 4 "request unlock all cab door latches" 5 "request lock all cab door latches" 6 "reserved" 7 "take no action";
VAL_ 2365443216 hazardLightSwitch_BASE 0 "Hazard Lamps to be Off" 1 "Hazard Lamps to be Flashing" 2 "Error" 3 "Not available (do not change)";
VAL_ 2564817041 DPFregenerationInhibitSw_BASE 0 "not active" 1 "active" 2 "error" 3 "not available";
VAL_ 2566656657 leftFrontWindowPositionCommand_B 0 "window move up" 1 "window move down" 2 "window auto up" 3 "window auto down" 4 "reserved" 5 "reserved" 6 "reserved" 7 "take no action";
VAL_ 2566656657 righFrontWindowPositionCommand_B 0 "window move up" 1 "window move down" 2 "window auto up" 3 "window auto down" 4 "reserved" 5 "reserved" 6 "reserved" 7 "take no action";
VAL_ 2566656657 remoteCabDoorLockRequest_BASE 0 "request unlock left front cab door latch (driver door on LH steer vehicles)" 1 "request unlock right front cab door latch (front passenger door for LH steer vehicles)" 2 "request unlock left rear cab door latch" 3 "request unlock right rear cab door latch" 4 "request unlock all cab door latches" 5 "request lock all cab door latches" 6 "reserved" 7 "take no action";
VAL_ 2364538257 CCswitchStatus_KSM 0 "neutral" 1 "Aus" 4 "Set-" 16 "Wiederaufnahme" 64 "Set+" 170 "Defekt";
VAL_ 2364538257 motorStart_KSM 0 "keine Start-Anforderung" 1 "Anforderung Normal Start" 2 "Anforderung Not Start" 3 "not defined, keine Anforderung";
VAL_ 2364538257 motorStop_KSM 0 "normale_Mengensollwertbildung" 1 "Nullmenge wegen Motor Stop" 2 "invalid, wie Interpretation wie 00" 3 "invalid, wie Interpretation wie 00";
VAL_ 2365443217 hazardLightSwitch_BASE 0 "Hazard Lamps to be Off" 1 "Hazard Lamps to be Flashing" 2 "Error" 3 "Not available (do not change)";
VAL_ 2348885905 gearShiftInhibitRequest_BASIS 0 "gear shifts are allowed" 1 "gear shifts are inhibited" 2 "invalid" 3 "take no action";
VAL_ 2348885905 torqueConvLockupDisableReq_BASIS 0 "allow torque converter lockup" 1 "disable torque converter lockup" 2 "error" 3 "not available";
VAL_ 2348885905 disengageDrivelineRequest_BASIS 0 "Allow driveline engagement" 1 "Disengage driveline" 2 "invalid" 3 "Take no action";
VAL_ 2348885905 transmissionMode1_BASE 0 "Transmission Mode 1 not active" 1 "Transmission Mode 1 Active" 2 "error" 3 "not available";
VAL_ 2566897297 bobuAudioMute_BASE 0 "no request" 1 "request" 2 "error" 3 "not available";
VAL_ 2566897297 bobuRecircModeReq_BASE 0 "take no action" 1 "request to activate recirculation mode" 2 "error" 3 "not available";
VAL_ 2566897297 footboardSw1_BASE 0 "Footboard not occupied" 1 "Footboard occupied" 2 "error" 3 "not available";
VAL_ 2566897297 lockCruisRange_BASE 0 "no action" 1 "lock change to R" 2 "lock change to D" 3 "lock change to R and D" 4 "reserved" 5 "reserved" 6 "reserved" 7 "reserved" 8 "reserved" 9 "reserved" 10 "reserved" 11 "reserved" 12 "reserved" 13 "reserved" 14 "error" 15 "not available";
VAL_ 2566897297 bobuSignalHornExtInhReq_BASE 0 "no action" 1 "inhibit horn" 2 "error" 3 "not available";
VAL_ 2566894993 bobuCAMreq1_BASE 0 "not requested" 1 "requested" 2 "error" 3 "not available";
VAL_ 2566894993 bobuCAMreq2_BASE 0 "not requested" 1 "requested" 2 "error" 3 "not available";
VAL_ 2566894993 bobuCAMreq3_BASE 0 "not requested" 1 "requested" 2 "error" 3 "not available";
VAL_ 2566894993 bobuCAMreq4_BASE 0 "not requested" 1 "requested" 2 "error" 3 "not available";
VAL_ 2566894993 bobuCAMreq5_BASE 0 "not requested" 1 "requested" 2 "error" 3 "not available";
VAL_ 2349075345 XBRcontrolMode_BASIS 0 "Override disabled" 1 "acceleration control with addition mode" 2 "acceleration control with maximum mode" 3 "not defined";
VAL_ 2565865813 haltBrakeSwitch_BASIS 0 "halt brake switch passive" 1 "halt brake switch active" 2 "error" 3 "not available";
VAL_ 2364538197 engineOverrideControlMode_KSM 0 "override disable" 1 "speed control" 2 "torque control" 3 "speed/ torque limit control";
VAL_ 2364538197 engineReqSpeedControlConditions_ 0 "Transient Optimized for driveline disengaged and non-lockup conditions" 1 "Stability Optimized for driveline disengaged and non-lockup conditions" 2 "Stability Optimized for driveline engaged and/or in lockup condition 1 (e.g., vehicle driveline)" 3 "Stability Optimized for driveline engaged and/or in lockup condition 2 (e.g., PTO driveline)";
VAL_ 2364538197 CCswitchStatus_KSM 0 "neutral" 1 "Aus" 4 "Set-" 16 "Wiederaufnahme" 64 "Set+" 170 "Defekt";
VAL_ 2364538197 motorStart_KSM 0 "keine Start-Anforderung" 1 "Anforderung Normal Start" 2 "Anforderung Not Start" 3 "not defined, keine Anforderung";
VAL_ 2364538197 motorStop_KSM 0 "normale_Mengensollwertbildung" 1 "Nullmenge wegen Motor Stop" 2 "invalid, wie Interpretation wie 00" 3 "invalid, wie Interpretation wie 00";
VAL_ 2364538197 ZDRmodeRequest_BASIS 0 "Mode 0" 1 "0001-0111 Mode 1- Mode 7" 8 "ZDR abschalten" 9 "1001-1110 reserved" 15 "not available";
VAL_ 2365573717 gearShiftInhibitRequest_KSM 0 "gear shifts are allowed" 1 "gear shifts are inhibited" 2 "invalid" 3 "take no action";
VAL_ 2365573717 torqueConvLockupDisableReq_KSM 0 "allow torque converter lockup" 1 "disable torque converter lockup" 2 "invalid" 3 "take no action";
VAL_ 2365573717 disengageDrivelineRequest_KSM 0 "Allow driveline engagement" 1 "Disengage driveline" 2 "invalid" 3 "Take no action";
VAL_ 2365573717 PTO3requestNMV_VAR1 0 "no request" 1 "request";
VAL_ 2365573717 PTO1request_VAR1 0 "no request" 1 "request";
VAL_ 2365573717 PTO2request_VAR1 0 "no request" 1 "request";
VAL_ 2365573717 driveProgramReqBobu_BASE 0 "default" 1 "program 1 - special program (on)" 14 "error" 15 "not available";
VAL_ 2600458235 navModeGNSS_BASE 0 "No Fix" 1 "2D Fix" 2 "3D Fix" 14 "error" 15 "not available";
VAL_ 2600458235 qualityIndicatorGNSS_BASE 0 "No Satellites" 1 "GPS Mode" 2 "Differential GPS" 3 "Estimated" 14 "error" 15 "not available";
VAL_ 2600458235 summerTimeGPS_BASE 0 "Winter Time" 1 "Summer Time" 2 "error" 3 "not available";
VAL_ 2583638267 appFrameworkAppCommand_BASE 0 "Take no action" 1 "Start App" 2 "Close App" 3 "Force Quit App" 4 "Get State";
VAL_ 2600460056 rmtTstrInstallMsgHeaderRsp_BASE 1058 "RemoteTesterFeatureList_GetJobIdPosResp" 1061 "RemoteTesterFeatureList_GetTitlesPosResp" 1064 "RemoteTesterFeatureList_GetTextPosResp" 1067 "RemoteTesterFeatureList_GetUrlPosResp" 1091 "RemoteTesterFeatureList_GetJobIdNegResp" 1094 "RemoteTesterFeatureList_GetTitlesNegResp" 1097 "RemoteTesterFeatureList_GetTextNegResp" 1100 "RemoteTesterFeatureList_GetUrlNegResp";
VAL_ 2600460056 rmtTstrInstallRespCode_BASE 0 "valid" 1 "job id not valid" 2 "list index not valid";
VAL_ 2600403195 HB_Wakeup_BASE 0 "Peripherie Wakeup reason_unknown" 1 "Bus Wakeup" 2 "clamp 15 HW pin" 3 "Peripherie Wakeup 3" 4 "Peripherie Wakeup 4" 5 "Peripherie Wakeup 5" 6 "Peripherie Wakeup 6" 7 "Peripherie Wakeup 7" 8 "Peripherie Wakeup 8" 128 "Function Wakeup 1" 129 "Function Wakeup 2" 130 "Function Wakeup  3" 131 "Function Wakeup  4" 132 "Function Wakeup  5";
VAL_ 2600403195 NM_ActiveWakeupBit_BASE 0 "Node has not woken up the network (passive wakeup)" 1 "Node has woken up the network (active wakeup)";
VAL_ 2600403195 NM_CRI_BASE 0 "no partial network request information; Standard Layout" 1 "partial network request information; TNB Layout";
VAL_ 2600403195 NM_State_BASE 1 "RM from BSM" 2 "RM from PBSM" 4 "NO from RM" 8 "NO from RS";
VAL_ 2600403195 NM_CarWakeup_BASE 0 "no Car-Wakeup request" 1 "Car-Wakeup request";
VAL_ 2600403195 NM_CC_BASE 0 "CC not active" 1 "CC active";
VAL_ 2600403195 NM_activeClamp15_BASE 0 "inactive" 1 "clamp15 active";
VAL_ 2600403195 NM_activeDiag_BASE 0 "inactive" 1 "Diagnostics active";
VAL_ 2600403195 NM_activeTmin_BASE 0 "inactive" 1 "Tmin not expired";
VAL_ 2600403195 NM_activeCWU_BASE 0 "inactive" 1 "CarWakeUp active";
VAL_ 2600403195 NM_activeFC_BASE 0 "inactive" 1 "FunctionCluster request active";
VAL_ 2600403195 nmClusterActive00_BASE 0 "off" 1 "on";
VAL_ 2600403195 nmClusterActive01_BASE 0 "off" 1 "on";
VAL_ 2600403195 nmClusterActive02_BASE 0 "off" 1 "on";
VAL_ 2600403195 nmClusterActive03_BASE 0 "off" 1 "on";
VAL_ 2600403195 nmClusterActive04_BASE 0 "off" 1 "on";
VAL_ 2600403195 nmClusterActive05_BASE 0 "off" 1 "on";
VAL_ 2600403195 nmClusterActive06_BASE 0 "off" 1 "on";
VAL_ 2600403195 nmClusterActive07_BASE 0 "off" 1 "on";
VAL_ 2600403195 nmClusterActive08_BASE 0 "off" 1 "on";
VAL_ 2600403195 nmClusterActive09_BASE 0 "off" 1 "on";
VAL_ 2600403195 nmClusterActive10_BASE 0 "off" 1 "on";
VAL_ 2600403195 nmClusterActive11_BASE 0 "off" 1 "on";
VAL_ 2600403195 nmClusterActive12_BASE 0 "off" 1 "on";
VAL_ 2600403195 nmClusterActive13_BASE 0 "off" 1 "on";
VAL_ 2600403195 nmClusterActive14_BASE 0 "off" 1 "on";
VAL_ 2600403195 nmClusterActive15_BASE 0 "off" 1 "on";
VAL_ 2600403195 nmClusterActive16_BASE 0 "off" 1 "on";
VAL_ 2600403195 nmClusterActive17_BASE 0 "off" 1 "on";
VAL_ 2600403195 nmClusterActive18_BASE 0 "off" 1 "on";
VAL_ 2600403195 nmClusterActive19_BASE 0 "off" 1 "on";
VAL_ 2600403195 nmClusterActive20_BASE 0 "off" 1 "on";
VAL_ 2600403195 nmClusterActive21_BASE 0 "off" 1 "on";
VAL_ 2600403195 nmClusterActive22_BASE 0 "off" 1 "on";
VAL_ 2600403195 nmClusterActive23_BASE 0 "off" 1 "on";
VAL_ 2566893819 reihenfolge_TBM2MC 0 "keine Reihenfolge" 1 "000001-111111 Reihenfolge";
VAL_ 2566893819 abfrageZWS_FWS_TBM2MC 0 "Abfrage ZWS Termine" 1 "Abfrage FWS Termine";
VAL_ 2566893819 typMeldung_TBM2MC 0 "Abfrage" 1 "Bestätigung";
VAL_ 2566893819 abfragetyp_TBM2MC 0 "Component ID" 1 "Reihenfolge";
VAL_ 2365443157 hazardLightSwitch_BASE 0 "Hazard Lamps to be Off" 1 "Hazard Lamps to be Flashing" 2 "Error" 3 "Not available (do not change)";
VAL_ 2566895189 statusBodyEPTO_BASE 0 "off" 1 "on" 2 "error" 3 "not available";
VAL_ 2566895189 ePTOreqBodyBuilder_BASE 0 "no request to activate ePTO" 1 "request to activate ePTO" 2 "error" 3 "not available";
VAL_ 2566679953 vehicleHorn_BASE 0 "disabled" 1 "enabled" 2 "reserved / error" 3 "take no action / not available";
VAL_ 2566679953 reverseDrivingAlarm_BASE 0 "disabled" 1 "enabled" 2 "reserved / error" 3 "take no action / not available";
VAL_ 2566679952 vehicleHorn_BASE 0 "disabled" 1 "enabled" 2 "reserved / error" 3 "take no action / not available";
VAL_ 2566679952 reverseDrivingAlarm_BASE 0 "disabled" 1 "enabled" 2 "reserved / error" 3 "take no action / not available";
VAL_ 2566679893 vehicleHorn_BASE 0 "disabled" 1 "enabled" 2 "reserved / error" 3 "take no action / not available";
VAL_ 2566679893 reverseDrivingAlarm_BASE 0 "disabled" 1 "enabled" 2 "reserved / error" 3 "take no action / not available";
VAL_ 2600454916 updtMstrUpdateStatus_BASE 0 "take no action" 1 "available with driver authorization" 2 "available with information" 3 "successful" 4 "failed" 14 "error" 15 "not available";
VAL_ 2600454916 updtMstrDispSupCheckbox_BASE 0 "do not display" 1 "display" 2 "error" 3 "not available";
VAL_ 2600454916 updtMstrUpdateTypeInfo_BASE 0 "recall" 1 "safety" 2 "security" 3 "performance" 4 "new feature" 5 "feature uninstallation" 14 "error" 15 "not available";
VAL_ 2600454916 updtMstrDrvrNotifStatus_BASE 0 "no notification requested" 1 "notification requested" 2 "error" 3 "not available";
VAL_ 2351336021 MG1ICLimReqOCM_BASE 0 "Limits not currently being requested in this PG. The operating limits are not overridden" 1 "Torque Limits Mode" 2 "Speed Limits Mode" 3 "DC Side Voltage Limits Mode" 4 "DC Side Current Limits Mode" 5 "DC Side Power Limits Mode" 6 "Mechanical Power Limits Mode" 7 "SAE reserved 7" 8 "SAE reserved 8" 9 "SAE reserved 9" 10 "SAE reserved 10" 11 "SAE reserved 11" 12 "SAE reserved 12" 13 "SAE reserved 13" 14 "error" 15 "not available  - take no action";
VAL_ 2351336021 MG1ICsetpointModeReq_BASE 0 "Power On -the inverter is commanded to be powered on and able to communicate, but the Power Stage is disabled e.g. no switching or output" 1 "SAE Reserved 1" 2 "Standby - the inverter Power Stage is powered but commanded to a neutral operating mode i.e. no torque control, for example." 3 "SAE Reserved 3" 4 "SAE Reserved 4" 5 "Manufacturer specific passive mode 1" 6 "Manufacturer specific passive mode 2" 7 "Enable Torque Control Mode" 8 "Enable Speed Control Mode" 9 "Enable DC Side Voltage Mode" 10 "Enable DC Side Current Mode" 11 "Enable DC Power Control Mode" 12 "Enable Mechanical Power Control Mode" 13 "SAE Reserved" 14 "SAE Reserved" 15 "SAE Reserved" 16 "SAE Reserved" 17 "SAE Reserved" 18 "Manufacturer specific active mode 1" 19 "Manufacturer specific active mode 2" 20 "Inverter active discharge mode e.g. used to discharge capacitance within the inverter." 21 "Inverter power down command mode  - afterwards inverter will not respond to further commands." 22 "SAE Reserved 22" 23 "SAE Reserved 23" 24 "SAE Reserved 24" 25 "SAE Reserved 25" 26 "SAE Reserved 26" 27 "SAE Reserved 27" 28 "Manufacturer specific special mode 1" 29 "Manufacturer specific special mode 2" 30 "SAE Reserved 30" 31 "Not Available - Dont Care -Take No";
VAL_ 2364638805 MG2IMF1setpointMode_BASE 0 "Powered On" 1 "Waiting for Operational conditions" 2 "Standby" 3 "SAE Reserved 3" 4 "SAE Reserved 4" 5 "Manufacturer specific passive mode 1" 6 "Manufacturer specific passive mode 2" 7 "Torque Control Mode" 8 "Speed Control Mode" 9 "DC Side Voltage Mode" 10 "DC Side Current Mode" 11 "Mechanical Power Control Mode" 12 "DC Power Control Mode" 13 "SAE Reserved 13" 14 "SAE Reserved 14" 15 "SAE Reserved 15" 16 "SAE Reserved 16" 17 "SAE Reserved 17" 18 "Manufacturer specific active mode 1" 19 "Manufacturer specific active mode 2" 20 "Inverter active discharge mode e.g. used to discharge capacitance within the inverter." 21 "Inverter power down command mode  - afterwards inverter will not respond to further commands." 22 "SAE Reserved 22" 23 "SAE Reserved 23" 24 "SAE Reserved 24" 25 "SAE Reserved 25" 26 "SAE Reserved 26" 27 "SAE Reserved 27" 28 "Manufacturer specific special mode 1" 29 "Manufacturer specific special mode 2" 30 "error" 31 "Not Available - Dont Care -Take No";
VAL_ 2562139997 hubVidInp1ConnectStatus_BASE 0 "Not connected" 1 "Connected" 2 "error" 3 "not available";
VAL_ 2562139997 cameraHubTriggerPin3req_BASE 0 "Not activated" 1 "Activated" 2 "error" 3 "not available";
VAL_ 2562139997 cameraHubTriggerPin4req_BASE 0 "Not activated" 1 "Activated" 2 "error" 3 "not available";
VAL_ 2562139997 cameraHubVidChnnlState_BASE 0 "No videostream on video output" 1 "videostream from video input 1 directed to output" 2 "videostream from video input 2 directed to output" 3 "videostream from video input 3 directed to output" 4 "videostream from video input 4 directed to output" 254 "error" 255 "not available";
VAL_ 2562139997 hubVidInp2ConnectStatus_BASE 0 "Not connected" 1 "Connected" 2 "error" 3 "not available";
VAL_ 2562139997 hubVidInp3ConnectStatus_BASE 0 "Not connected" 1 "Connected" 2 "error" 3 "not available";
VAL_ 2562139997 hubVidInp4ConnectStatus_BASE 0 "Not connected" 1 "Connected" 2 "error" 3 "not available";
VAL_ 2566799505 rotatingBeaconLightCmd_BASE 0 "De-activate" 1 "Activate" 2 "Reserved" 3 "Don¿t Care";
VAL_ 2566799505 centerStopLightCmd_BASE 0 "De-activate" 1 "Activate" 2 "Reserved" 3 "Don¿t Care";
VAL_ 2566799505 tractorMarkerLightCmd_BASE 0 "De-activate" 1 "Activate" 2 "Reserved" 3 "Don¿t Care";
VAL_ 2566799505 rearFogLightCmd_BASE 0 "De-activate" 1 "Activate" 2 "Reserved" 3 "Don¿t Care";
VAL_ 2566799505 lowBeamHLReq_BASE 0 "no request" 1 "request" 2 "error" 3 "not available";
VAL_ 2566799505 implOEMOption1lightCmd_BASE 0 "deactivate" 1 "activate" 2 "error" 3 "not available";
VAL_ 2566799505 implementRightFwdWorkLightCmd_BA 0 "De-activate" 1 "Activate" 2 "Reserved" 3 "Don¿t Care";
VAL_ 2566799505 implementRearWorkLightCmd_BASE 0 "De-activate" 1 "Activate" 2 "Reserved" 3 "Don¿t Care";
VAL_ 2566799445 rotatingBeaconLightCmd_BASE 0 "De-activate" 1 "Activate" 2 "Reserved" 3 "Don¿t Care";
VAL_ 2566799445 centerStopLightCmd_BASE 0 "De-activate" 1 "Activate" 2 "Reserved" 3 "Don¿t Care";
VAL_ 2566799445 tractorMarkerLightCmd_BASE 0 "De-activate" 1 "Activate" 2 "Reserved" 3 "Don¿t Care";
VAL_ 2566799445 rearFogLightCmd_BASE 0 "De-activate" 1 "Activate" 2 "Reserved" 3 "Don¿t Care";
VAL_ 2566799445 lowBeamHLReq_BASE 0 "no request" 1 "request" 2 "error" 3 "not available";
VAL_ 2566799445 implOEMOption1lightCmd_BASE 0 "deactivate" 1 "activate" 2 "error" 3 "not available";
VAL_ 2566799445 implementRightFwdWorkLightCmd_BA 0 "De-activate" 1 "Activate" 2 "Reserved" 3 "Don¿t Care";
VAL_ 2566799445 implementRearWorkLightCmd_BASE 0 "De-activate" 1 "Activate" 2 "Reserved" 3 "Don¿t Care";
VAL_ 2566799504 rotatingBeaconLightCmd_BASE 0 "De-activate" 1 "Activate" 2 "Reserved" 3 "Don¿t Care";
VAL_ 2566799504 centerStopLightCmd_BASE 0 "De-activate" 1 "Activate" 2 "Reserved" 3 "Don¿t Care";
VAL_ 2566799504 tractorMarkerLightCmd_BASE 0 "De-activate" 1 "Activate" 2 "Reserved" 3 "Don¿t Care";
VAL_ 2566799504 rearFogLightCmd_BASE 0 "De-activate" 1 "Activate" 2 "Reserved" 3 "Don¿t Care";
VAL_ 2566799504 lowBeamHLReq_BASE 0 "no request" 1 "request" 2 "error" 3 "not available";
VAL_ 2566799504 implOEMOption1lightCmd_BASE 0 "deactivate" 1 "activate" 2 "error" 3 "not available";
VAL_ 2566799504 implementRightFwdWorkLightCmd_BA 0 "De-activate" 1 "Activate" 2 "Reserved" 3 "Don¿t Care";
VAL_ 2566799504 implementRearWorkLightCmd_BASE 0 "De-activate" 1 "Activate" 2 "Reserved" 3 "Don¿t Care";
VAL_ 2566799760 rotatingBeaconLightCmd_BASE 0 "De-activate" 1 "Activate" 2 "Reserved" 3 "Don¿t Care";
VAL_ 2566799760 centerStopLightCmd_BASE 0 "De-activate" 1 "Activate" 2 "Reserved" 3 "Don¿t Care";
VAL_ 2566799760 tractorMarkerLightCmd_BASE 0 "De-activate" 1 "Activate" 2 "Reserved" 3 "Don¿t Care";
VAL_ 2566799760 rearFogLightCmd_BASE 0 "De-activate" 1 "Activate" 2 "Reserved" 3 "Don¿t Care";
VAL_ 2566799760 lowBeamHLReq_BASE 0 "no request" 1 "request" 2 "error" 3 "not available";
VAL_ 2566799760 implOEMOption1lightCmd_BASE 0 "deactivate" 1 "activate" 2 "error" 3 "not available";
VAL_ 2566799760 implementRightFwdWorkLightCmd_BA 0 "De-activate" 1 "Activate" 2 "Reserved" 3 "Don¿t Care";
VAL_ 2566799760 implementRearWorkLightCmd_BASE 0 "De-activate" 1 "Activate" 2 "Reserved" 3 "Don¿t Care";
VAL_ 2566799761 rotatingBeaconLightCmd_BASE 0 "De-activate" 1 "Activate" 2 "Reserved" 3 "Don¿t Care";
VAL_ 2566799761 centerStopLightCmd_BASE 0 "De-activate" 1 "Activate" 2 "Reserved" 3 "Don¿t Care";
VAL_ 2566799761 tractorMarkerLightCmd_BASE 0 "De-activate" 1 "Activate" 2 "Reserved" 3 "Don¿t Care";
VAL_ 2566799761 rearFogLightCmd_BASE 0 "De-activate" 1 "Activate" 2 "Reserved" 3 "Don¿t Care";
VAL_ 2566799761 lowBeamHLReq_BASE 0 "no request" 1 "request" 2 "error" 3 "not available";
VAL_ 2566799761 implOEMOption1lightCmd_BASE 0 "deactivate" 1 "activate" 2 "error" 3 "not available";
VAL_ 2566799761 implementRightFwdWorkLightCmd_BA 0 "De-activate" 1 "Activate" 2 "Reserved" 3 "Don¿t Care";
VAL_ 2566799761 implementRearWorkLightCmd_BASE 0 "De-activate" 1 "Activate" 2 "Reserved" 3 "Don¿t Care";
VAL_ 2566799701 rotatingBeaconLightCmd_BASE 0 "De-activate" 1 "Activate" 2 "Reserved" 3 "Don¿t Care";
VAL_ 2566799701 centerStopLightCmd_BASE 0 "De-activate" 1 "Activate" 2 "Reserved" 3 "Don¿t Care";
VAL_ 2566799701 tractorMarkerLightCmd_BASE 0 "De-activate" 1 "Activate" 2 "Reserved" 3 "Don¿t Care";
VAL_ 2566799701 rearFogLightCmd_BASE 0 "De-activate" 1 "Activate" 2 "Reserved" 3 "Don¿t Care";
VAL_ 2566799701 lowBeamHLReq_BASE 0 "no request" 1 "request" 2 "error" 3 "not available";
VAL_ 2566799701 implOEMOption1lightCmd_BASE 0 "deactivate" 1 "activate" 2 "error" 3 "not available";
VAL_ 2566799701 implementRightFwdWorkLightCmd_BA 0 "De-activate" 1 "Activate" 2 "Reserved" 3 "Don¿t Care";
VAL_ 2566799701 implementRearWorkLightCmd_BASE 0 "De-activate" 1 "Activate" 2 "Reserved" 3 "Don¿t Care";
VAL_ 2566897493 genericBobuIn101_BASE 0 "passive" 1 "active" 2 "error" 3 "not available";
VAL_ 2566897493 genericBobuIn102_BASE 0 "passive" 1 "active" 2 "error" 3 "not available";
VAL_ 2566897493 genericBobuIn103_BASE 0 "passive" 1 "active" 2 "error" 3 "not available";
VAL_ 2566897493 genericBobuIn104_BASE 0 "passive" 1 "active" 2 "error" 3 "not available";
VAL_ 2566897493 genericBobuIn105_BASE 0 "passive" 1 "active" 2 "error" 3 "not available";
VAL_ 2566897493 genericBobuIn106_BASE 0 "passive" 1 "active" 2 "error" 3 "not available";
VAL_ 2566897237 bobuAudioMute_BASE 0 "no request" 1 "request" 2 "error" 3 "not available";
VAL_ 2566897237 bobuRecircModeReq_BASE 0 "take no action" 1 "request to activate recirculation mode" 2 "error" 3 "not available";
VAL_ 2566897237 footboardSw1_BASE 0 "Footboard not occupied" 1 "Footboard occupied" 2 "error" 3 "not available";
VAL_ 2566897237 lockCruisRange_BASE 0 "no action" 1 "lock change to R" 2 "lock change to D" 3 "lock change to R and D" 4 "reserved" 5 "reserved" 6 "reserved" 7 "reserved" 8 "reserved" 9 "reserved" 10 "reserved" 11 "reserved" 12 "reserved" 13 "reserved" 14 "error" 15 "not available";
VAL_ 2566897237 bobuSignalHornExtInhReq_BASE 0 "no action" 1 "inhibit horn" 2 "error" 3 "not available";
VAL_ 2566759568 enableSwitch_transInputShaftPTO2 0 "Enable switch off - PTO operation not desired" 1 "Enable switch off - PTO operation desired" 2 "Error" 3 "Not available";
VAL_ 2566759568 engagemStatus_PTOengAccesDrive1_ 0 "Drive not engaged" 1 "Drive engaged" 2 "Error" 3 "Not available";
VAL_ 2566759568 enableSwitch_transInputShaftPTO1 0 "Enable switch off - PTO operation not desired" 1 "Enable switch off - PTO operation desired" 2 "Error" 3 "Not available";
VAL_ 2566759568 enableSwitch_PTOengineFlywheel_B 0 "Enable switch off - PTO operation not desired" 1 "Enable switch on - PTO operation desired" 2 "Error" 3 "Not available";
VAL_ 2566759569 enableSwitch_transInputShaftPTO2 0 "Enable switch off - PTO operation not desired" 1 "Enable switch off - PTO operation desired" 2 "Error" 3 "Not available";
VAL_ 2566759569 engagemStatus_PTOengAccesDrive1_ 0 "Drive not engaged" 1 "Drive engaged" 2 "Error" 3 "Not available";
VAL_ 2566759569 enableSwitch_transInputShaftPTO1 0 "Enable switch off - PTO operation not desired" 1 "Enable switch off - PTO operation desired" 2 "Error" 3 "Not available";
VAL_ 2566759569 enableSwitch_PTOengineFlywheel_B 0 "Enable switch off - PTO operation not desired" 1 "Enable switch on - PTO operation desired" 2 "Error" 3 "Not available";
VAL_ 2600454917 extrnlChrgOTAbooked_BASE 0 "not booked" 1 "booked" 2 "error" 3 "not available";
VAL_ 2600454917 cntrctCertChrgI1OTAreq_BASE 0 "contract 1" 1 "contract 2" 2 "contract 3" 3 "contract 4" 4 "contract 5" 14 "error" 15 "not available";
VAL_ 2600454917 cntrctCertChrgI2OTAreq_BASE 0 "contract 1" 1 "contract 2" 2 "contract 3" 3 "contract 4" 4 "contract 5" 14 "error" 15 "not available";
VAL_ 2600454917 extrnlChrgHVACstrgyOTAreq_BASE 0 "towards charging end" 1 "continuously during charging" 2 "error" 3 "not available";
VAL_ 2600454917 extrnlChrgHldInfOTAreq_BASE 0 "not requested" 1 "requested" 2 "error" 3 "not available";
VAL_ 2600454917 extrnlChrgPnCslctdOTAreq_BASE 0 "PnC not requested" 1 "PnC requested" 2 "error" 3 "not available";
VAL_ 2600454917 extrnlChrgAMS_OTAreq_BASE 0 "no AMS precond request" 1 "AMS precond request" 2 "error" 3 "not available";
VAL_ 2600454917 extrnlChrgFastChrgOTAreq_BASE 0 "not requested" 1 "requested" 2 "error" 3 "not available";
VAL_ 2600454917 extrnlChrgOTActrlOTAreq_BASE 0 "OTA control disabled" 1 "OTA control enabled" 2 "error" 3 "not available";
VAL_ 2600454917 extrnlChrgSelPrcTypOTAreq_BASE 0 "no pricing/battery optimal" 1 "relative price" 2 "absolut price" 3 "CO2 emission" 4 "renewable energy %" 5 "reserved" 6 "reserved" 7 "reserved" 8 "reserved" 9 "reserved" 10 "reserved" 14 "error" 15 "not available";
VAL_ 2566759509 enableSwitch_transInputShaftPTO2 0 "Enable switch off - PTO operation not desired" 1 "Enable switch off - PTO operation desired" 2 "Error" 3 "Not available";
VAL_ 2566759509 engagemStatus_PTOengAccesDrive1_ 0 "Drive not engaged" 1 "Drive engaged" 2 "Error" 3 "Not available";
VAL_ 2566759509 enableSwitch_transInputShaftPTO1 0 "Enable switch off - PTO operation not desired" 1 "Enable switch off - PTO operation desired" 2 "Error" 3 "Not available";
VAL_ 2566759509 enableSwitch_PTOengineFlywheel_B 0 "Enable switch off - PTO operation not desired" 1 "Enable switch on - PTO operation desired" 2 "Error" 3 "Not available";
VAL_ 2348820369 engineOverrideControlMode_TCU2EN 0 "override disable" 1 "speed control" 2 "torque control" 3 "speed/ torque limit control";
VAL_ 2348820369 engineReqSpeedControlConditions_ 0 "Transient Optimized for driveline disengaged and non-lockup conditions" 1 "Stability Optimized for driveline disengaged and non-lockup conditions" 2 "Stability Optimized for driveline engaged and/or in lockup condition 1 (e.g., vehicle driveline)" 3 "Stability Optimized for driveline engaged and/or in lockup condition 2 (e.g., PTO driveline)";
VAL_ 2348820369 overrideControlModePriority_TCU2 0 "highest priority" 1 "high priority" 2 "medium priority" 3 "low priority";
VAL_ 2348820368 engineOverrideControlMode_TCU2EN 0 "override disable" 1 "speed control" 2 "torque control" 3 "speed/ torque limit control";
VAL_ 2348820368 engineReqSpeedControlConditions_ 0 "Transient Optimized for driveline disengaged and non-lockup conditions" 1 "Stability Optimized for driveline disengaged and non-lockup conditions" 2 "Stability Optimized for driveline engaged and/or in lockup condition 1 (e.g., vehicle driveline)" 3 "Stability Optimized for driveline engaged and/or in lockup condition 2 (e.g., PTO driveline)";
VAL_ 2348820368 overrideControlModePriority_TCU2 0 "highest priority" 1 "high priority" 2 "medium priority" 3 "low priority";
VAL_ 2348820309 engineOverrideControlMode_TCU2EN 0 "override disable" 1 "speed control" 2 "torque control" 3 "speed/ torque limit control";
VAL_ 2348820309 engineReqSpeedControlConditions_ 0 "Transient Optimized for driveline disengaged and non-lockup conditions" 1 "Stability Optimized for driveline disengaged and non-lockup conditions" 2 "Stability Optimized for driveline engaged and/or in lockup condition 1 (e.g., vehicle driveline)" 3 "Stability Optimized for driveline engaged and/or in lockup condition 2 (e.g., PTO driveline)";
VAL_ 2348820309 overrideControlModePriority_TCU2 0 "highest priority" 1 "high priority" 2 "medium priority" 3 "low priority";
VAL_ 2600418645 parkBrkAppReq_BASE 0 "parking brake application not requested" 1 "parking brake application requested" 2 "error" 3 "not available";
VAL_ 2600418645 parkBrkRlsReq_BASE 0 "parking brake release not requested" 1 "parking brake release requested" 2 "error" 3 "not available";
VAL_ 2600418645 parkBrkRlsInhibit_BASE 0 "no inhibit active" 1 "inhibit auto release" 2 "inhibit auto and manual release";
VAL_ 2600466261 levelControlModeRequest_BASIS 0 "Normal operation; i.e. the system performs a pure control of the vehicle hei" 1 "Traction help (load transfer); i.e. the driven axle is loaded to a maximum value given by legislation or design" 2 "Load fixing; i.e. the driven axlen is loaded to a value defined by the driver" 3 "Pressure ratio 1; i.e. the ratio between the pressures at the driven axle and at the third axle is controlled, so that the ratio equals a fixed value 1" 4 "Pressure ratio 2; i.e. the ratio between the pressures at the driven axle and at the third axle is controlled, so that the ratio equals a fixed value 2" 5 "Optimum traction 1; i.e. the pressure at the driven axle is controlled at a fixed value 1" 6 "Optimum traction 2; i.e. the pressure at the driven axle is controlled at a fixed value 2" 7 "Traction help - load reduce; (i.e. reduce axle load of driven axle to normal load condition)" 8 "Exhaust bellows" 9 "1001-1101 Not defined" 14 "reserved" 15 "take no action";
VAL_ 2600466261 prohibitAutomaticASC_BASE 0 "No request" 1 "Request prohibit automatic air suspension control" 2 "Error indicator" 3 "Not available";
VAL_ 2600466261 leftTurnSignalLightsCmd_BASE 0 "De-activate" 1 "Activate" 2 "Reserved" 3 "Don¿t Care";
VAL_ 2600466261 rightTurnSignalLightsCmd_BASE 0 "De-activate" 1 "Activate" 2 "Reserved" 3 "Don¿t Care";
VAL_ 2600466261 footboardSw1_BASE 0 "Footboard not occupied" 1 "Footboard occupied" 2 "error" 3 "not available";
VAL_ 2600466261 generalCamera3Active_BASE 0 "not active" 1 "active" 2 "error" 3 "not available";
VAL_ 2600466261 generalCamera4Active_BASE 0 "not active" 1 "active" 2 "error" 3 "not available";
VAL_ 2600466261 extAccelDemReqBB2_BASE 0 "braking not requested" 1 "braking requested" 2 "error" 3 "not available";
VAL_ 2600466261 bobuNomLvlReqAxle_BASE 0 "No level request" 1 "Normal Level 1,(i.e. the level prescribed for normal driving, given by design)" 2 "Normal Level 2,(i.e. a level permitted for driving, for example to lower the vehicle in case of high speed)" 3 "Normal Level 3,(i.e. a level permitted for driving, for example to lift the vehicle in case of offroad)" 4 "Preset Level,(i.e. a level to be defined externally via CAN)" 5 "Customer Level,(i.e. a level to be defined by customer via parameter setting)" 6 "Upper Level,(i.e. the highest level to be controlled)" 7 "Lower Level,(i.e. the lowest level to be controlled)" 8 "Stop level change,(i.e. the level change in process shall be stopped immediately)" 9 "Raise Request (Continuously raising front axle, as long as active)." 10 "Lower Request (Continuously lowering front axle, as long as active)." 11 "1011-1101 Not defined" 14 "reserved" 15 "don't care/take no action";
VAL_ 2566894737 bobuLiftAxle1posCmd_BASE 0 "no request" 1 "lift axle position down" 2 "lift axle position up" 3 "not available / take no action";
VAL_ 2566894737 bobuLiftAxle2posCmd_BASE 0 "no request" 1 "lift axle position down" 2 "lift axle position up" 3 "not available / take no action";
VAL_ 2566894737 bobuLvlCtrlModeRequest_BASE 0 "Normal operation; i.e. the system performs a pure control of the vehicle hei" 1 "Traction help (load transfer); i.e. the driven axle is loaded to a maximum value given by legislation or design" 2 "Load fixing; i.e. the driven axlen is loaded to a value defined by the driver" 3 "Pressure ratio 1; i.e. the ratio between the pressures at the driven axle and at the third axle is controlled, so that the ratio equals a fixed value 1" 4 "Pressure ratio 2; i.e. the ratio between the pressures at the driven axle and at the third axle is controlled, so that the ratio equals a fixed value 2" 5 "Optimum traction 1; i.e. the pressure at the driven axle is controlled at a fixed value 1" 6 "Optimum traction 2; i.e. the pressure at the driven axle is controlled at a fixed value 2" 7 "Traction help - load reduce; (i.e. reduce axle load of driven axle to normal load condition)" 8 "Exhaust bellows" 9 "not defined" 10 "not defined" 11 "not defined" 12 "not defined" 13 "not defined" 14 "error" 15 "available";
VAL_ 2566894737 bobuNomLvlReqRA_BASE 0 "No level request" 1 "Normal Level 1,(i.e. the level prescribed for normal driving, given by design)" 2 "Normal Level 2,(i.e. a level permitted for driving, for example to lower the vehicle in case of high speed)" 3 "Normal Level 3,(i.e. a level permitted for driving, for example to lift the vehicle in case of offroad)" 4 "Preset Level,(i.e. a level to be defined externally via CAN)" 5 "Customer Level,(i.e. a level to be defined by customer via parameter setting)" 6 "Upper Level,(i.e. the highest level to be controlled)" 7 "Lower Level,(i.e. the lowest level to be controlled)" 8 "Stop level change,(i.e. the level change in process shall be stopped immediately)" 9 "Raise Request (Continuously raising front axle, as long as active)." 10 "Lower Request (Continuously lowering front axle, as long as active)." 11 "not defined" 12 "not defined" 13 "not defined" 14 "error" 15 "available";
VAL_ 2566894737 bobuNomLvlReqFA_BASE 0 "No level request" 1 "Normal Level 1,(i.e. the level prescribed for normal driving, given by design)" 2 "Normal Level 2,(i.e. a level permitted for driving, for example to lower the vehicle in case of high speed)" 3 "Normal Level 3,(i.e. a level permitted for driving, for example to lift the vehicle in case of offroad)" 4 "Preset Level,(i.e. a level to be defined externally via CAN)" 5 "Customer Level,(i.e. a level to be defined by customer via parameter setting)" 6 "Upper Level,(i.e. the highest level to be controlled)" 7 "Lower Level,(i.e. the lowest level to be controlled)" 8 "Stop level change,(i.e. the level change in process shall be stopped immediately)" 9 "Raise Request (Continuously raising front axle, as long as active)." 10 "Lower Request (Continuously lowering front axle, as long as active)." 11 "not defined" 12 "not defined" 13 "not defined" 14 "error" 15 "available";
VAL_ 2566894737 bobuProhibitAutoASC_BASE 0 "No request" 1 "Request prohibit automatic air suspension control" 2 "error" 3 "not available";
VAL_ 2566894677 bobuLiftAxle1posCmd_BASE 0 "no request" 1 "lift axle position down" 2 "lift axle position up" 3 "not available / take no action";
VAL_ 2566894677 bobuLiftAxle2posCmd_BASE 0 "no request" 1 "lift axle position down" 2 "lift axle position up" 3 "not available / take no action";
VAL_ 2566894677 bobuLvlCtrlModeRequest_BASE 0 "Normal operation; i.e. the system performs a pure control of the vehicle hei" 1 "Traction help (load transfer); i.e. the driven axle is loaded to a maximum value given by legislation or design" 2 "Load fixing; i.e. the driven axlen is loaded to a value defined by the driver" 3 "Pressure ratio 1; i.e. the ratio between the pressures at the driven axle and at the third axle is controlled, so that the ratio equals a fixed value 1" 4 "Pressure ratio 2; i.e. the ratio between the pressures at the driven axle and at the third axle is controlled, so that the ratio equals a fixed value 2" 5 "Optimum traction 1; i.e. the pressure at the driven axle is controlled at a fixed value 1" 6 "Optimum traction 2; i.e. the pressure at the driven axle is controlled at a fixed value 2" 7 "Traction help - load reduce; (i.e. reduce axle load of driven axle to normal load condition)" 8 "Exhaust bellows" 9 "not defined" 10 "not defined" 11 "not defined" 12 "not defined" 13 "not defined" 14 "error" 15 "available";
VAL_ 2566894677 bobuNomLvlReqRA_BASE 0 "No level request" 1 "Normal Level 1,(i.e. the level prescribed for normal driving, given by design)" 2 "Normal Level 2,(i.e. a level permitted for driving, for example to lower the vehicle in case of high speed)" 3 "Normal Level 3,(i.e. a level permitted for driving, for example to lift the vehicle in case of offroad)" 4 "Preset Level,(i.e. a level to be defined externally via CAN)" 5 "Customer Level,(i.e. a level to be defined by customer via parameter setting)" 6 "Upper Level,(i.e. the highest level to be controlled)" 7 "Lower Level,(i.e. the lowest level to be controlled)" 8 "Stop level change,(i.e. the level change in process shall be stopped immediately)" 9 "Raise Request (Continuously raising front axle, as long as active)." 10 "Lower Request (Continuously lowering front axle, as long as active)." 11 "not defined" 12 "not defined" 13 "not defined" 14 "error" 15 "available";
VAL_ 2566894677 bobuNomLvlReqFA_BASE 0 "No level request" 1 "Normal Level 1,(i.e. the level prescribed for normal driving, given by design)" 2 "Normal Level 2,(i.e. a level permitted for driving, for example to lower the vehicle in case of high speed)" 3 "Normal Level 3,(i.e. a level permitted for driving, for example to lift the vehicle in case of offroad)" 4 "Preset Level,(i.e. a level to be defined externally via CAN)" 5 "Customer Level,(i.e. a level to be defined by customer via parameter setting)" 6 "Upper Level,(i.e. the highest level to be controlled)" 7 "Lower Level,(i.e. the lowest level to be controlled)" 8 "Stop level change,(i.e. the level change in process shall be stopped immediately)" 9 "Raise Request (Continuously raising front axle, as long as active)." 10 "Lower Request (Continuously lowering front axle, as long as active)." 11 "not defined" 12 "not defined" 13 "not defined" 14 "error" 15 "available";
VAL_ 2566894677 bobuProhibitAutoASC_BASE 0 "No request" 1 "Request prohibit automatic air suspension control" 2 "error" 3 "not available";
VAL_ 2566894736 bobuLiftAxle1posCmd_BASE 0 "no request" 1 "lift axle position down" 2 "lift axle position up" 3 "not available / take no action";
VAL_ 2566894736 bobuLiftAxle2posCmd_BASE 0 "no request" 1 "lift axle position down" 2 "lift axle position up" 3 "not available / take no action";
VAL_ 2566894736 bobuLvlCtrlModeRequest_BASE 0 "Normal operation; i.e. the system performs a pure control of the vehicle hei" 1 "Traction help (load transfer); i.e. the driven axle is loaded to a maximum value given by legislation or design" 2 "Load fixing; i.e. the driven axlen is loaded to a value defined by the driver" 3 "Pressure ratio 1; i.e. the ratio between the pressures at the driven axle and at the third axle is controlled, so that the ratio equals a fixed value 1" 4 "Pressure ratio 2; i.e. the ratio between the pressures at the driven axle and at the third axle is controlled, so that the ratio equals a fixed value 2" 5 "Optimum traction 1; i.e. the pressure at the driven axle is controlled at a fixed value 1" 6 "Optimum traction 2; i.e. the pressure at the driven axle is controlled at a fixed value 2" 7 "Traction help - load reduce; (i.e. reduce axle load of driven axle to normal load condition)" 8 "Exhaust bellows" 9 "not defined" 10 "not defined" 11 "not defined" 12 "not defined" 13 "not defined" 14 "error" 15 "available";
VAL_ 2566894736 bobuNomLvlReqRA_BASE 0 "No level request" 1 "Normal Level 1,(i.e. the level prescribed for normal driving, given by design)" 2 "Normal Level 2,(i.e. a level permitted for driving, for example to lower the vehicle in case of high speed)" 3 "Normal Level 3,(i.e. a level permitted for driving, for example to lift the vehicle in case of offroad)" 4 "Preset Level,(i.e. a level to be defined externally via CAN)" 5 "Customer Level,(i.e. a level to be defined by customer via parameter setting)" 6 "Upper Level,(i.e. the highest level to be controlled)" 7 "Lower Level,(i.e. the lowest level to be controlled)" 8 "Stop level change,(i.e. the level change in process shall be stopped immediately)" 9 "Raise Request (Continuously raising front axle, as long as active)." 10 "Lower Request (Continuously lowering front axle, as long as active)." 11 "not defined" 12 "not defined" 13 "not defined" 14 "error" 15 "available";
VAL_ 2566894736 bobuNomLvlReqFA_BASE 0 "No level request" 1 "Normal Level 1,(i.e. the level prescribed for normal driving, given by design)" 2 "Normal Level 2,(i.e. a level permitted for driving, for example to lower the vehicle in case of high speed)" 3 "Normal Level 3,(i.e. a level permitted for driving, for example to lift the vehicle in case of offroad)" 4 "Preset Level,(i.e. a level to be defined externally via CAN)" 5 "Customer Level,(i.e. a level to be defined by customer via parameter setting)" 6 "Upper Level,(i.e. the highest level to be controlled)" 7 "Lower Level,(i.e. the lowest level to be controlled)" 8 "Stop level change,(i.e. the level change in process shall be stopped immediately)" 9 "Raise Request (Continuously raising front axle, as long as active)." 10 "Lower Request (Continuously lowering front axle, as long as active)." 11 "not defined" 12 "not defined" 13 "not defined" 14 "error" 15 "available";
VAL_ 2566894736 bobuProhibitAutoASC_BASE 0 "No request" 1 "Request prohibit automatic air suspension control" 2 "error" 3 "not available";
VAL_ 2667525634 appValSwitch4Req_BASE 0 "not enabled" 1 "enabled" 2 "error" 3 "not available";
VAL_ 2667525634 appValSwitch5Req_BASE 0 "not enabled" 1 "enabled" 2 "error" 3 "not available";
VAL_ 2667525634 appValSwitch2Req_BASE 0 "not enabled" 1 "enabled" 2 "error" 3 "not available";
VAL_ 2667525634 appValSwitch1Req_BASE 0 "not enabled" 1 "enabled" 2 "error" 3 "not available";
VAL_ 2667525634 appValSwitch3Req_BASE 0 "not enabled" 1 "enabled" 2 "error" 3 "not available";
VAL_ 2667525634 activateDrvProgConfig_BASE 0 "dont activate" 1 "activate" 2 "error" 3 "not available";
VAL_ 2600454912 chllngngEnvrnmntDet_BASE 0 "not detected" 1 "detected" 2 "error" 3 "not available";
VAL_ 2600415573 genericBobuDisp1_BASE 0 "no request" 1 "request bodybuilder specific symbol and text" 2 "error" 3 "not available";
VAL_ 2600415573 genericBobuDisp6_BASE 0 "no request" 1 "request bodybuilder specific symbol and text" 2 "error" 3 "not available";
VAL_ 2600415573 genericBobuDisp7_BASE 0 "no request" 1 "request bodybuilder specific symbol and text" 2 "error" 3 "not available";
VAL_ 2600415573 genericBobuDisp8_BASE 0 "no request" 1 "request bodybuilder specific symbol and text" 2 "error" 3 "not available";
VAL_ 2600415573 genericBobuDisp9_BASE 0 "no request" 1 "request bodybuilder specific symbol and text" 2 "error" 3 "not available";
VAL_ 2600415573 genericBobuDisp10_BASE 0 "no request" 1 "request bodybuilder specific symbol and text" 2 "error" 3 "not available";
VAL_ 2600415573 genericBobuDisp2_BASE 0 "no request" 1 "request bodybuilder specific symbol and text" 2 "error" 3 "not available";
VAL_ 2600415573 genericBobuDisp3_BASE 0 "no request" 1 "request bodybuilder specific symbol and text" 2 "error" 3 "not available";
VAL_ 2600415573 genericBobuDisp4_BASE 0 "no request" 1 "request bodybuilder specific symbol and text" 2 "error" 3 "not available";
VAL_ 2600415573 genericBobuDisp5_BASE 0 "no request" 1 "request bodybuilder specific symbol and text" 2 "error" 3 "not available";
VAL_ 2600415632 genericBobuDisp1_BASE 0 "no request" 1 "request bodybuilder specific symbol and text" 2 "error" 3 "not available";
VAL_ 2600415632 genericBobuDisp6_BASE 0 "no request" 1 "request bodybuilder specific symbol and text" 2 "error" 3 "not available";
VAL_ 2600415632 genericBobuDisp7_BASE 0 "no request" 1 "request bodybuilder specific symbol and text" 2 "error" 3 "not available";
VAL_ 2600415632 genericBobuDisp8_BASE 0 "no request" 1 "request bodybuilder specific symbol and text" 2 "error" 3 "not available";
VAL_ 2600415632 genericBobuDisp9_BASE 0 "no request" 1 "request bodybuilder specific symbol and text" 2 "error" 3 "not available";
VAL_ 2600415632 genericBobuDisp10_BASE 0 "no request" 1 "request bodybuilder specific symbol and text" 2 "error" 3 "not available";
VAL_ 2600415632 genericBobuDisp2_BASE 0 "no request" 1 "request bodybuilder specific symbol and text" 2 "error" 3 "not available";
VAL_ 2600415632 genericBobuDisp3_BASE 0 "no request" 1 "request bodybuilder specific symbol and text" 2 "error" 3 "not available";
VAL_ 2600415632 genericBobuDisp4_BASE 0 "no request" 1 "request bodybuilder specific symbol and text" 2 "error" 3 "not available";
VAL_ 2600415632 genericBobuDisp5_BASE 0 "no request" 1 "request bodybuilder specific symbol and text" 2 "error" 3 "not available";
VAL_ 2600415633 genericBobuDisp1_BASE 0 "no request" 1 "request bodybuilder specific symbol and text" 2 "error" 3 "not available";
VAL_ 2600415633 genericBobuDisp6_BASE 0 "no request" 1 "request bodybuilder specific symbol and text" 2 "error" 3 "not available";
VAL_ 2600415633 genericBobuDisp7_BASE 0 "no request" 1 "request bodybuilder specific symbol and text" 2 "error" 3 "not available";
VAL_ 2600415633 genericBobuDisp8_BASE 0 "no request" 1 "request bodybuilder specific symbol and text" 2 "error" 3 "not available";
VAL_ 2600415633 genericBobuDisp9_BASE 0 "no request" 1 "request bodybuilder specific symbol and text" 2 "error" 3 "not available";
VAL_ 2600415633 genericBobuDisp10_BASE 0 "no request" 1 "request bodybuilder specific symbol and text" 2 "error" 3 "not available";
VAL_ 2600415633 genericBobuDisp2_BASE 0 "no request" 1 "request bodybuilder specific symbol and text" 2 "error" 3 "not available";
VAL_ 2600415633 genericBobuDisp3_BASE 0 "no request" 1 "request bodybuilder specific symbol and text" 2 "error" 3 "not available";
VAL_ 2600415633 genericBobuDisp4_BASE 0 "no request" 1 "request bodybuilder specific symbol and text" 2 "error" 3 "not available";
VAL_ 2600415633 genericBobuDisp5_BASE 0 "no request" 1 "request bodybuilder specific symbol and text" 2 "error" 3 "not available";
VAL_ 2600454918 extrnlChrgModeOTAreq_BASE 0 "immediate charging" 1 "timer charging" 2 "station controlled charging (fallback immediate)" 3 "station controlled charging (fallback timer)" 4 "reserved" 5 "reserved" 6 "reserved" 7 "reserved" 8 "reserved" 9 "reserved" 10 "reserved" 14 "error" 15 "not available";
VAL_ 2600454918 extrnlChrgPreCondOTAreq_BASE 0 "no HVAC precond request" 1 "HVAC precond request" 2 "error" 3 "not available";
VAL_ 2600454918 extrnlChrgAllwdOTAreq_BASE 0 "charging not allowed" 1 "charging allowed" 2 "error" 3 "not available";
VAL_ 2600454913 SRPACCdistLvl_BASE 14 "error" 15 "not available";
VAL_ 2600454913 SRPecoLevel_BASE 0 "display preset 0" 1 "display preset 1" 2 "display preset 2" 3 "display preset 3" 4 "display preset 4" 5 "display preset 5" 6 "display preset 6" 7 "display preset 7" 14 "error" 15 "not available";
VAL_ 2600454913 SRPchangeType_BASE 0 "immediate change" 1 "change on PCCA situation" 2 "error" 3 "not available";
VAL_ 2600454914 SRPdrivingProg_BASE -1 "kein Programm" 0 "Programm 0 (default)" 1 "Programm 1" 2 "Programm 2" 3 "Programm 3" 4 "Programm 4" 5 "Programm 5" 6 "Programm 6" 7 "Programm 7" 8 "Programm 8" 9 "Programm 9" 10 "Programm 10" 11 "Programm 11" 12 "Programm 12" 13 "Programm 13" 14 "Programm 14" 61 "error" 62 "not available";
VAL_ 2600454914 wasteEnergyModeActSRP_BASE 0 "WasteEnergyMode not activated" 1 "WasteEnergy is activated" 2 "error" 3 "not available";
